VERSION "dbc-export 1 2026.26.6.5"

NS_ :

BS_:

BU_: APP APS BMS CC CMP CMPD CP DAS DI DIF DIR EPBL EPBR EVSE FC GTW HCML HCMR HVP ICR PCS PCS2 PLG PM PMF PMR PTC SCCM SCM SCS SDCR TAS UMC V2G VC VCBATT VCBATT0 VCBATT1 VCBATT2 VCFRONT VCFRONT1 VCFRONT2 VCLEFT VCRIGHT VCSEAT2L VCSEAT2R VCSEC

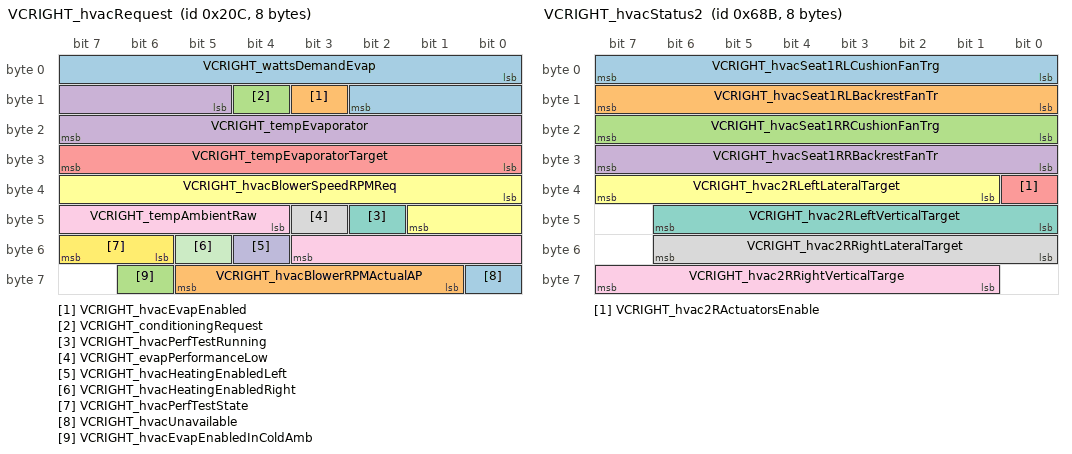
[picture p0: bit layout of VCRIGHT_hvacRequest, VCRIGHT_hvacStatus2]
BO_ 524 VCRIGHT_hvacRequest: 8 VCRIGHT
 SG_ VCRIGHT_wattsDemandEvap : 0|11@1+ (5,0) [0|10000] "W" Vector__XXX
 SG_ VCRIGHT_hvacEvapEnabled : 11|1@1+ (1,0) [0|1] "" Vector__XXX
 SG_ VCRIGHT_conditioningRequest : 12|1@1+ (1,0) [0|1] "" Vector__XXX
 SG_ VCRIGHT_tempEvaporator : 13|11@1+ (0.1,-40) [-40|105] "degC" Vector__XXX
 SG_ VCRIGHT_tempEvaporatorTarget : 24|8@1+ (0.2,0) [0|50] "degC" Vector__XXX
 SG_ VCRIGHT_hvacBlowerSpeedRPMReq : 32|10@1+ (5,0) [0|5115] "RPM" Vector__XXX
 SG_ VCRIGHT_hvacPerfTestRunning : 42|1@1+ (1,0) [0|1] "" Vector__XXX
 SG_ VCRIGHT_evapPerformanceLow : 43|1@1+ (1,0) [0|1] "" Vector__XXX
 SG_ VCRIGHT_tempAmbientRaw : 44|8@1+ (0.5,-40) [-39.5|80] "degC" Vector__XXX
 SG_ VCRIGHT_hvacHeatingEnabledLeft : 52|1@1+ (1,0) [0|1] "" Vector__XXX
 SG_ VCRIGHT_hvacHeatingEnabledRight : 53|1@1+ (1,0) [0|1] "" Vector__XXX
 SG_ VCRIGHT_hvacPerfTestState : 54|2@1+ (1,0) [0|3] "" Vector__XXX
 SG_ VCRIGHT_hvacUnavailable : 56|1@1+ (1,0) [0|1] "" Vector__XXX
 SG_ VCRIGHT_hvacBlowerRPMActualAP : 57|5@1+ (200,0) [0|4200] "rpm" Vector__XXX
 SG_ VCRIGHT_hvacEvapEnabledInColdAmb : 62|1@1+ (1,0) [0|1] "" Vector__XXX

BO_ 579 VCRIGHT_hvacStatus: 8 VCRIGHT
 SG_ VCRIGHT_hvacStatusIndex M : 0|3@1+ (1,0) [0|7] "" Vector__XXX
 SG_ VCRIGHT_warmingUpStatus m0 : 10|5@1+ (3,7) [7|100] "%" Vector__XXX
 SG_ VCRIGHT_coolingDownStatus m0 : 15|5@1+ (3,7) [7|100] "%" Vector__XXX
 SG_ VCRIGHT_childModeHVACState m0 : 20|2@1+ (1,0) [0|3] "" Vector__XXX
 SG_ VCRIGHT_dogModeState m0 : 22|4@1+ (1,0) [0|15] "" Vector__XXX
 SG_ VCRIGHT_hvacCabinTempEstValid m0 : 26|1@1+ (1,0) [0|1] "" Vector__XXX
 SG_ VCRIGHT_COPNotRunningReasonFilte m0 : 27|3@1+ (1,0) [0|7] "" Vector__XXX
 SG_ VCRIGHT_hvacCabinTempEst m0 : 30|11@1+ (0.1,-40) [-40|164] "degC" Vector__XXX
 SG_ VCRIGHT_hvacAirDistributionMode m0 : 41|3@1+ (1,0) [0|7] "" Vector__XXX
 SG_ VCRIGHT_hvacBlowerSegment m0 : 44|4@1+ (1,0) [0|15] "" Vector__XXX
 SG_ VCRIGHT_hvacRecirc m0 : 48|2@1+ (1,0) [0|3] "" Vector__XXX
 SG_ VCRIGHT_hvacACRunning m0 : 50|1@1+ (1,0) [0|1] "" Vector__XXX
 SG_ VCRIGHT_hvacPowerState m0 : 51|3@1+ (1,0) [0|7] "" Vector__XXX
 SG_ VCRIGHT_hvacVentStatus m0 : 54|2@1+ (1,0) [0|3] "" Vector__XXX
 SG_ VCRIGHT_hvacSecondRowState m0 : 56|3@1+ (1,0) [0|7] "" Vector__XXX
 SG_ VCRIGHT_hvacSystemNominal m0 : 59|1@1+ (1,0) [0|1] "" Vector__XXX
 SG_ VCRIGHT_hvacModelInitStatus m0 : 60|4@1+ (1,0) [0|15] "" Vector__XXX
 SG_ VCRIGHT_hvacMassflowRefrigSysRig m1 : 3|7@1+ (1,0) [0|125] "g/s" Vector__XXX
 SG_ VCRIGHT_hvacRecircDoorPercent m1 : 10|6@1+ (1.6,0) [0|100] "%" Vector__XXX
 SG_ VCRIGHT_tempDuctLeft m1 : 16|8@1+ (0.5,-22) [-22|105] "degC" Vector__XXX
 SG_ VCRIGHT_hvacMassflowRefrigSystem m1 : 24|8@1+ (1,0) [0|250] "g/s" Vector__XXX
 SG_ VCRIGHT_tempDuctRight m1 : 32|8@1+ (0.5,-22) [-22|105] "degC" Vector__XXX
 SG_ VCRIGHT_hvacMassflowRefrigSysLef m1 : 40|7@1+ (1,0) [0|125] "g/s" Vector__XXX
 SG_ VCRIGHT_hvacDuctTargetLeft m1 : 48|8@1+ (0.5,-40) [-40|80] "degC" Vector__XXX
 SG_ VCRIGHT_hvacDuctTargetRight m1 : 56|8@1+ (0.5,-40) [-40|80] "degC" Vector__XXX
 SG_ VCRIGHT_enableTripleCameraFanPow m2 : 9|1@1+ (1,0) [0|1] "" Vector__XXX
 SG_ VCRIGHT_tempDuctRightUpper m2 : 10|8@1+ (0.5,-22) [-22|105] "degC" Vector__XXX
 SG_ VCRIGHT_hpSplitTempsEnabled m2 : 18|1@1+ (1,0) [0|1] "" Vector__XXX
 SG_ VCRIGHT_hvacEvapInletTempEstimat m2 : 19|10@1+ (0.13,-40) [-40|90] "degC" Vector__XXX
 SG_ VCRIGHT_tempMonitorNotNominal m2 : 29|1@1+ (1,0) [0|1] "" Vector__XXX
 SG_ VCRIGHT_hvacCabinAtTempTarget m2 : 30|1@1+ (1,0) [0|1] "" Vector__XXX
 SG_ VCRIGHT_hvacReqSecondRow m2 : 31|1@1+ (1,0) [0|1] "" Vector__XXX
 SG_ VCRIGHT_hvacAirflowReason m2 : 32|5@1+ (1,0) [0|31] "" Vector__XXX
 SG_ VCRIGHT_autoHvacBlowerShouldLimi m2 : 37|1@1+ (1,0) [0|1] "" Vector__XXX
 SG_ VCRIGHT_hvacReqThirdRow m2 : 38|1@1+ (1,0) [0|1] "" Vector__XXX
 SG_ VCRIGHT_solarLoadOnVehicle m2 : 40|8@1+ (4,0) [0|1016] "W/m2" Vector__XXX
 SG_ VCRIGHT_refrigDistCommanded m2 : 48|1@1+ (1,0) [0|1] "" Vector__XXX
 SG_ VCRIGHT_hvacFrontRightSeatFanSta m2 : 49|2@1+ (1,0) [0|3] "" Vector__XXX
 SG_ VCRIGHT_hvacFrontLeftSeatFanStat m2 : 51|2@1+ (1,0) [0|3] "" Vector__XXX
 SG_ VCRIGHT_hvacRefHighPowerRequest m2 : 53|1@1+ (1,0) [0|1] "" Vector__XXX
 SG_ VCRIGHT_windshieldCameraHeaterDu m2 : 54|5@1+ (5,0) [0|100] "%" Vector__XXX
 SG_ VCRIGHT_extendedHvacPerfTestSupp m2 : 59|4@1+ (1,0) [0|15] "" Vector__XXX
 SG_ VCRIGHT_hvacFrontRightSeatHeatSt m3 : 4|2@1+ (1,0) [0|3] "" Vector__XXX
 SG_ VCRIGHT_hvacSeatFrontLeftTempTar m3 : 6|8@1+ (0.5,-40) [-40|80] "degC" Vector__XXX
 SG_ VCRIGHT_hvacManualToAutoNotify m3 : 14|3@1+ (1,0) [0|7] "" Vector__XXX
 SG_ VCRIGHT_hvacRequestsFullAuto m3 : 17|3@1+ (1,0) [0|7] "" Vector__XXX
 SG_ VCRIGHT_passengerPresentHvacCycl m3 : 21|1@1+ (1,0) [0|1] "" Vector__XXX
 SG_ VCRIGHT_hvacRequestsAutoIntake m3 : 22|1@1+ (1,0) [0|1] "" Vector__XXX
 SG_ VCRIGHT_steeringWheelHeatStatus m3 : 24|2@1+ (1,0) [0|3] "" Vector__XXX
 SG_ VCRIGHT_autoDefogStatus m3 : 26|2@1+ (1,0) [0|3] "" Vector__XXX
 SG_ VCRIGHT_solarElevation m3 : 31|9@1- (0.5,0) [-127.5|127.5] "deg" Vector__XXX
 SG_ VCRIGHT_minsToSunrise m3 : 40|8@1+ (10,0) [0|2540] "min" Vector__XXX
 SG_ VCRIGHT_minsToSunset m3 : 48|8@1+ (10,0) [0|2540] "min" Vector__XXX
 SG_ VCRIGHT_hvacLimitedReasonRight m3 : 56|3@1+ (1,0) [0|7] "" Vector__XXX
 SG_ VCRIGHT_hvacLimitedReasonLeft m3 : 59|3@1+ (1,0) [0|7] "" Vector__XXX
 SG_ VCRIGHT_hvacOverheatProtActive m3 : 63|1@1+ (1,0) [0|1] "" Vector__XXX
 SG_ VCRIGHT_autoSwingAvailable m4 : 9|1@1+ (1,0) [0|1] "" Vector__XXX
 SG_ VCRIGHT_tempDuctLeftUpper m4 : 10|8@1+ (0.5,-22) [-22|105] "degC" Vector__XXX
 SG_ VCRIGHT_hvacFrontLeftSeatHeatSta m4 : 18|2@1+ (1,0) [0|3] "" Vector__XXX
 SG_ VCRIGHT_hvacQdotLeft m4 : 20|14@1+ (1,-8191) [-8191|8191] "W" Vector__XXX
 SG_ VCRIGHT_hvacQdotRight m4 : 34|14@1+ (1,-8191) [-8191|8191] "W" Vector__XXX
 SG_ VCRIGHT_tempDuctLeftLower m4 : 48|8@1+ (0.5,-22) [-22|105] "degC" Vector__XXX
 SG_ VCRIGHT_tempDuctRightLower m4 : 56|8@1+ (0.5,-22) [-22|105] "degC" Vector__XXX
 SG_ VCRIGHT_foggingControllerResetRe m5 : 9|15@1+ (1,0) [0|32767] "" Vector__XXX
 SG_ VCRIGHT_modeledCabinPressure m5 : 24|8@1+ (1,0) [0|255] "Pa" Vector__XXX
 SG_ VCRIGHT_blowerTorqueIndex m5 : 32|7@1+ (1,0) [0|127] "%" Vector__XXX
 SG_ VCRIGHT_autoSwingLeftPosX m5 : 39|8@1+ (0.4,0) [0|100] "%" Vector__XXX
 SG_ VCRIGHT_autoSwingRightPositionX m5 : 48|8@1+ (0.4,0) [0|100] "%" Vector__XXX

BO_ 1675 VCRIGHT_hvacStatus2: 8 VCRIGHT
 SG_ VCRIGHT_hvacSeat1RLCushionFanTrg : 0|8@1+ (0.5,0) [0|100] "%" Vector__XXX
 SG_ VCRIGHT_hvacSeat1RLBackrestFanTr : 8|8@1+ (0.5,0) [0|100] "%" Vector__XXX
 SG_ VCRIGHT_hvacSeat1RRCushionFanTrg : 16|8@1+ (0.5,0) [0|100] "%" Vector__XXX
 SG_ VCRIGHT_hvacSeat1RRBackrestFanTr : 24|8@1+ (0.5,0) [0|100] "%" Vector__XXX
 SG_ VCRIGHT_hvac2RActuatorsEnable : 32|1@1+ (1,0) [0|1] "" Vector__XXX
 SG_ VCRIGHT_hvac2RLeftLateralTarget : 33|7@1+ (1,0) [0|100] "%" Vector__XXX
 SG_ VCRIGHT_hvac2RLeftVerticalTarget : 40|7@1+ (1,0) [0|100] "%" Vector__XXX
 SG_ VCRIGHT_hvac2RRightLateralTarget : 48|7@1+ (1,0) [0|100] "%" Vector__XXX
 SG_ VCRIGHT_hvac2RRightVerticalTarge : 57|7@1+ (1,0) [0|100] "%" Vector__XXX

BO_ 771 VCRIGHT_info: 8 VCRIGHT
 SG_ VCRIGHT_infoIndex M : 0|8@1+ (1,0) [0|255] "" Vector__XXX
 SG_ VCRIGHT_infoBuildType m10 : 8|3@1+ (1,0) [0|7] "" Vector__XXX
 SG_ VCRIGHT_infoBuildConfigId m10 : 16|16@1+ (1,0) [0|65535] "" Vector__XXX
 SG_ VCRIGHT_infoHardwareId m10 : 32|16@1+ (1,0) [0|65535] "" Vector__XXX
 SG_ VCRIGHT_infoComponentId m10 : 48|16@1+ (1,0) [0|65535] "" Vector__XXX
 SG_ VCRIGHT_infoPcbaId m11 : 8|8@1+ (1,0) [0|255] "" Vector__XXX
 SG_ VCRIGHT_infoAssemblyId m11 : 16|8@1+ (1,0) [0|254] "" Vector__XXX
 SG_ VCRIGHT_infoUsageId m11 : 24|16@1+ (1,0) [0|65535] "" Vector__XXX
 SG_ VCRIGHT_infoSubUsageId m11 : 40|16@1+ (1,0) [0|65535] "" Vector__XXX
 SG_ VCRIGHT_infoAppCrc m13 : 8|32@1+ (1,0) [0|4294967295] "" Vector__XXX
 SG_ VCRIGHT_infoLUMBARRAppCRC m16 : 32|32@1+ (1,0) [0|4294967295] "" Vector__XXX
 SG_ VCRIGHT_infoAppGitHash m17 : 8|56@1+ (1,0) [0|7.20575940379e+16] "" Vector__XXX
 SG_ VCRIGHT_infoBootGitHash m18 : 8|56@1+ (1,0) [0|7.20575940379e+16] "" Vector__XXX
 SG_ VCRIGHT_infoPlatformType m19 : 8|8@1+ (1,0) [0|255] "" Vector__XXX
 SG_ VCRIGHT_infoBootUdsProtoVersion m20 : 8|16@1+ (1,0) [0|65535] "" Vector__XXX
 SG_ VCRIGHT_infoBootCrc m20 : 24|32@1+ (1,0) [0|4294967295] "" Vector__XXX

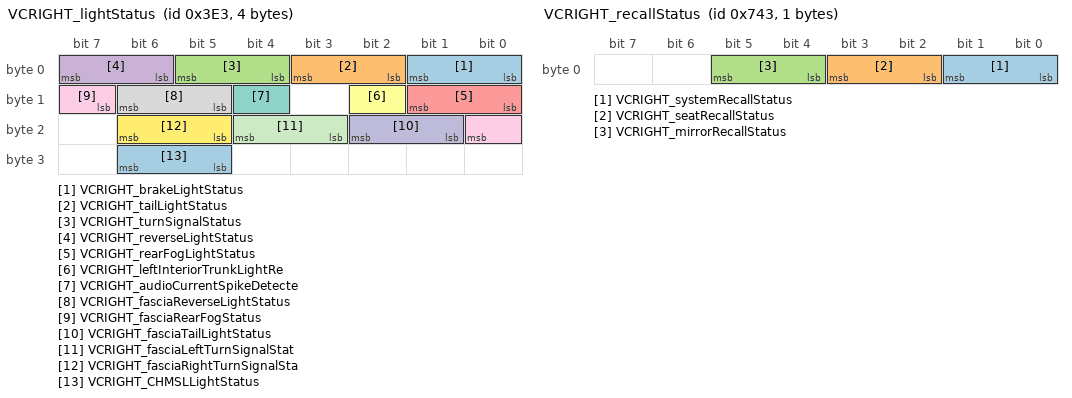
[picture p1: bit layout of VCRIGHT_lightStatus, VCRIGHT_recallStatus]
BO_ 995 VCRIGHT_lightStatus: 4 VCRIGHT
 SG_ VCRIGHT_brakeLightStatus : 0|2@1+ (1,0) [0|2] "" Vector__XXX
 SG_ VCRIGHT_tailLightStatus : 2|2@1+ (1,0) [0|2] "" Vector__XXX
 SG_ VCRIGHT_turnSignalStatus : 4|2@1+ (1,0) [0|2] "" Vector__XXX
 SG_ VCRIGHT_reverseLightStatus : 6|2@1+ (1,0) [0|2] "" Vector__XXX
 SG_ VCRIGHT_rearFogLightStatus : 8|2@1+ (1,0) [0|2] "" Vector__XXX
 SG_ VCRIGHT_leftInteriorTrunkLightRe : 10|1@1+ (1,0) [0|1] "" Vector__XXX
 SG_ VCRIGHT_audioCurrentSpikeDetecte : 12|1@1+ (1,0) [0|1] "" Vector__XXX
 SG_ VCRIGHT_fasciaReverseLightStatus : 13|2@1+ (1,0) [0|2] "" Vector__XXX
 SG_ VCRIGHT_fasciaRearFogStatus : 15|2@1+ (1,0) [0|2] "" Vector__XXX
 SG_ VCRIGHT_fasciaTailLightStatus : 17|2@1+ (1,0) [0|2] "" Vector__XXX
 SG_ VCRIGHT_fasciaLeftTurnSignalStat : 19|2@1+ (1,0) [0|2] "" Vector__XXX
 SG_ VCRIGHT_fasciaRightTurnSignalSta : 21|2@1+ (1,0) [0|2] "" Vector__XXX
 SG_ VCRIGHT_CHMSLLightStatus : 29|2@1+ (1,0) [0|2] "" Vector__XXX

BO_ 1803 VCRIGHT_logging0point1Hz: 8 VCRIGHT
 SG_ VCRIGHT_logging0point1HzIndex M : 0|4@1+ (1,0) [0|15] "" Vector__XXX
 SG_ VCRIGHT_glareShieldEstimatedResi m2 : 4|6@1+ (0.5,10) [10|40] "Ohm" Vector__XXX
 SG_ VCRIGHT_cabinAirFilterLifeRemain m2 : 10|7@1+ (1,0) [0|127] "%" Vector__XXX
 SG_ VCRIGHT_HEPAAirFilterLifeRemaini m2 : 17|7@1+ (1,0) [0|127] "%" Vector__XXX
 SG_ VCRIGHT_leftPTCCompromisedRod m2 : 24|3@1+ (1,0) [0|7] "" Vector__XXX
 SG_ VCRIGHT_rightPTCCompromisedRod m2 : 27|3@1+ (1,0) [0|7] "" Vector__XXX
 SG_ VCRIGHT_hepaFilterHealthScore m2 : 32|7@1+ (1,0) [0|127] "%" Vector__XXX
 SG_ VCRIGHT_cabinFilterHealthScore m2 : 40|7@1+ (1,0) [0|127] "%" Vector__XXX
 SG_ VCRIGHT_cabinTempBreathLevelFOff m2 : 47|8@1+ (0.5,-40) [-40|80] "degC" Vector__XXX
 SG_ VCRIGHT_airDistributionModeAdjus m2 : 55|9@1+ (0.001,1) [1|1.5] "-" Vector__XXX
 SG_ VCRIGHT_hvacLHBleedEndStop m3 : 8|8@1+ (0.02,0) [0|5] "V" Vector__XXX
 SG_ VCRIGHT_hvacRHBleedEndStop m3 : 16|8@1+ (0.02,0) [0|5] "V" Vector__XXX
 SG_ VCRIGHT_hvacLHVaneEndStop m3 : 24|8@1+ (0.02,0) [0|5] "V" Vector__XXX
 SG_ VCRIGHT_hvacRHVaneEndStop m3 : 32|8@1+ (0.02,0) [0|5] "V" Vector__XXX
 SG_ VCRIGHT_hvacUpperModeEndStop m3 : 40|8@1+ (0.02,0) [0|5] "V" Vector__XXX
 SG_ VCRIGHT_hvacLowerModeEndStop m3 : 48|8@1+ (0.02,0) [0|5] "V" Vector__XXX
 SG_ VCRIGHT_hvacIntakeEndStop m3 : 56|8@1+ (0.02,0) [0|5] "V" Vector__XXX
 SG_ VCRIGHT_hvacLHBleedZeroStop m4 : 8|8@1+ (0.02,0) [0|5] "V" Vector__XXX
 SG_ VCRIGHT_hvacRHBleedZeroStop m4 : 16|8@1+ (0.02,0) [0|5] "V" Vector__XXX
 SG_ VCRIGHT_hvacLHVaneZeroStop m4 : 24|8@1+ (0.02,0) [0|5] "V" Vector__XXX
 SG_ VCRIGHT_hvacRHVaneZeroStop m4 : 32|8@1+ (0.02,0) [0|5] "V" Vector__XXX
 SG_ VCRIGHT_hvacUpperModeZeroStop m4 : 40|8@1+ (0.02,0) [0|5] "V" Vector__XXX
 SG_ VCRIGHT_hvacLowerModeZeroStop m4 : 48|8@1+ (0.02,0) [0|5] "V" Vector__XXX
 SG_ VCRIGHT_hvacIntakeZeroStop m4 : 56|8@1+ (0.02,0) [0|5] "V" Vector__XXX
 SG_ VCRIGHT_averageDuctTempFCooling m5 : 8|8@1+ (0.5,-40) [-40|80] "degC" Vector__XXX
 SG_ VCRIGHT_fasciaTailLeftLightCurre m5 : 16|9@1+ (0.002,0) [0|1.02] "A" Vector__XXX
 SG_ VCRIGHT_fasciaTailLeftLight_0001 m5 : 25|3@1+ (1,0) [1|7] "" Vector__XXX
 SG_ VCRIGHT_fasciaTailRightLightCurr m5 : 28|9@1+ (0.002,0) [0|1.02] "A" Vector__XXX
 SG_ VCRIGHT_fasciaTailRightLigh_0001 m5 : 37|3@1+ (1,0) [1|7] "" Vector__XXX
 SG_ VCRIGHT_liftgateTailLeftLightCur m5 : 40|9@1+ (0.002,0) [0|1.02] "A" Vector__XXX
 SG_ VCRIGHT_liftgateTailLeftLig_0001 m5 : 49|3@1+ (1,0) [1|7] "" Vector__XXX
 SG_ VCRIGHT_liftgateTailRightLightCu m5 : 52|3@1+ (1,0) [1|7] "" Vector__XXX
 SG_ VCRIGHT_ambientTempLimp m6 : 8|8@1+ (0.5,-40) [-40|80] "degC" Vector__XXX
 SG_ VCRIGHT_cabinProbeTempLimp m6 : 16|8@1+ (0.5,-40) [-40|80] "degC" Vector__XXX
 SG_ VCRIGHT_thsTempLimp m6 : 24|8@1+ (0.5,-40) [-40|80] "degC" Vector__XXX
 SG_ VCRIGHT_thsCabinWaterMassLimp m6 : 32|8@1+ (0.5,0) [0|124] "g/kg" Vector__XXX
 SG_ VCRIGHT_thsSolarIrradianceLimp m6 : 40|8@1+ (5,0) [0|1270] "W/m2" Vector__XXX
 SG_ VCRIGHT_silentWakeRecordCount m6 : 48|5@1+ (1,0) [0|31] "" Vector__XXX
 SG_ VCRIGHT_interiorCameraLedCurrent m6 : 56|8@1+ (8,0) [0|2032] "mA" Vector__XXX
 SG_ VCRIGHT_evapCondensateMass m7 : 8|8@1+ (2,0) [0|500] "g" Vector__XXX
 SG_ VCRIGHT_airwaveRightLateralTotal m7 : 16|16@1+ (6100,0) [0|399763500] "deg" Vector__XXX
 SG_ VCRIGHT_airwaveLeftLateralTotalT m7 : 32|16@1+ (6100,0) [0|399763500] "deg" Vector__XXX
 SG_ VCRIGHT_hvacRearEndStop m7 : 48|8@1+ (0.02,0) [0|5] "V" Vector__XXX
 SG_ VCRIGHT_hvacRearZeroStop m7 : 56|8@1+ (0.02,0) [0|5] "V" Vector__XXX
 SG_ VCRIGHT_evapLoadInFresh m8 : 8|8@1+ (35,0) [0|8000] "W" Vector__XXX
 SG_ VCRIGHT_evapLoadInRecirc m8 : 16|8@1+ (35,0) [0|8000] "W" Vector__XXX
 SG_ VCRIGHT_tempIncarCabinDeep m8 : 24|8@1+ (0.5,-40) [-40|85] "degC" Vector__XXX
 SG_ VCRIGHT_cabinTempBreathLeve_0001 m8 : 32|8@1+ (0.5,-40) [-40|80] "degC" Vector__XXX
 SG_ VCRIGHT_cabinTempBreathLevelF10m m8 : 40|8@1+ (0.5,-40) [-40|80] "degC" Vector__XXX
 SG_ VCRIGHT_cabinTempBreathLeve_0002 m8 : 48|8@1+ (0.5,-40) [-40|80] "degC" Vector__XXX
 SG_ VCRIGHT_cabinTempBreathLevelF5mi m8 : 56|8@1+ (0.5,-40) [-40|80] "degC" Vector__XXX
 SG_ VCRIGHT_foggingMonitorRuntime m9 : 4|12@1+ (10,0) [0|40950] "Hours" Vector__XXX
 SG_ VCRIGHT_cabinTempInteriorFHeatin m9 : 16|8@1+ (0.5,-40) [-40|80] "degC" Vector__XXX
 SG_ VCRIGHT_cabinTempInteriorFCoolin m9 : 24|8@1+ (0.5,-40) [-40|80] "degC" Vector__XXX
 SG_ VCRIGHT_filterLifeBlowerTorque m9 : 32|10@1+ (0.006,-1.5) [-1.5|4.5] "Nm" Vector__XXX
 SG_ VCRIGHT_averageDuctTempFHeating m9 : 48|8@1+ (0.5,-40) [-40|80] "degC" Vector__XXX
 SG_ VCRIGHT_thsSolarSensorType m9 : 56|2@1+ (1,0) [0|3] "" Vector__XXX
 SG_ VCRIGHT_thsTempSensorType m9 : 58|2@1+ (1,0) [0|3] "" Vector__XXX

BO_ 611 VCRIGHT_logging10Hz: 8 VCRIGHT
 SG_ VCRIGHT_logging10HzIndex M : 0|3@1+ (1,0) [0|7] "" Vector__XXX
 SG_ VCRIGHT_hvacLHBleedTarget m0 : 3|8@1+ (0.4,0) [0|100] "%" Vector__XXX
 SG_ VCRIGHT_hvacRHBleedTarget m0 : 11|8@1+ (0.4,0) [0|100] "%" Vector__XXX
 SG_ VCRIGHT_hvacLHVaneTarget m0 : 19|8@1+ (0.4,0) [0|100] "%" Vector__XXX
 SG_ VCRIGHT_hvacRHVaneTarget m0 : 27|8@1+ (0.4,0) [0|100] "%" Vector__XXX
 SG_ VCRIGHT_hvacUpperModeTarget m0 : 35|10@1+ (0.1,0) [0|100] "%" Vector__XXX
 SG_ VCRIGHT_hvacLowerModeTarget m0 : 45|8@1+ (0.4,0) [0|100] "%" Vector__XXX
 SG_ VCRIGHT_hvacIntakeTarget m0 : 53|8@1+ (0.4,0) [0|100] "%" Vector__XXX
 SG_ VCRIGHT_hvacLHBleedPosition m1 : 3|8@1+ (0.4,0) [0|100] "%" Vector__XXX
 SG_ VCRIGHT_hvacRHBleedPosition m1 : 11|8@1+ (0.4,0) [0|100] "%" Vector__XXX
 SG_ VCRIGHT_hvacLHVanePosition m1 : 19|8@1+ (0.4,0) [0|100] "%" Vector__XXX
 SG_ VCRIGHT_hvacRHVanePosition m1 : 27|8@1+ (0.4,0) [0|100] "%" Vector__XXX
 SG_ VCRIGHT_hvacUpperModePosition m1 : 35|10@1+ (0.1,0) [0|100] "%" Vector__XXX
 SG_ VCRIGHT_hvacLowerModePosition m1 : 45|8@1+ (0.4,0) [0|100] "%" Vector__XXX
 SG_ VCRIGHT_hvacIntakePosition m1 : 53|8@1+ (0.4,0) [0|100] "%" Vector__XXX
 SG_ VCRIGHT_hvacLHBleedActuatorState m2 : 3|2@1+ (1,0) [0|3] "" Vector__XXX
 SG_ VCRIGHT_hvacRHBleedActuatorState m2 : 5|2@1+ (1,0) [0|3] "" Vector__XXX
 SG_ VCRIGHT_hvacLHVaneActuatorState m2 : 8|2@1+ (1,0) [0|3] "" Vector__XXX
 SG_ VCRIGHT_hvacRHVaneActuatorState m2 : 10|2@1+ (1,0) [0|3] "" Vector__XXX
 SG_ VCRIGHT_hvacUpperModeActState m2 : 12|2@1+ (1,0) [0|3] "" Vector__XXX
 SG_ VCRIGHT_hvacLowerModeActState m2 : 14|2@1+ (1,0) [0|3] "" Vector__XXX
 SG_ VCRIGHT_hvacIntakeActuatorState m2 : 16|2@1+ (1,0) [0|3] "" Vector__XXX
 SG_ VCRIGHT_hvacRearActuatorState m2 : 18|2@1+ (1,0) [0|3] "" Vector__XXX
 SG_ VCRIGHT_EvapPulldownBiasActive m2 : 20|1@1+ (1,0) [0|1] "" Vector__XXX
 SG_ VCRIGHT_tempDatLeftEst m2 : 21|9@1+ (0.5,-22) [-22|200] "degC" Vector__XXX
 SG_ VCRIGHT_tempDatRightEst m2 : 30|9@1+ (0.5,-22) [-22|200] "degC" Vector__XXX
 SG_ VCRIGHT_tempDuctLeftEst m2 : 40|8@1+ (0.5,-22) [-22|105] "degC" Vector__XXX
 SG_ VCRIGHT_tempDuctRightEst m2 : 48|8@1+ (0.5,-22) [-22|105] "degC" Vector__XXX
 SG_ VCRIGHT_ptcHeaterBadRodDetection m2 : 56|4@1+ (1,0) [0|15] "" Vector__XXX
 SG_ VCRIGHT_upperModeDrvActuatorStat m2 : 60|4@1+ (1,0) [0|15] "" Vector__XXX
 SG_ VCRIGHT_leftVerticalActuato_0001 m3 : 8|8@1+ (1,0) [0|255] "" Vector__XXX
 SG_ VCRIGHT_leftLateralActuatorStatu m3 : 16|8@1+ (1,0) [0|255] "" Vector__XXX
 SG_ VCRIGHT_rightVerticalActuat_0001 m3 : 24|8@1+ (1,0) [0|255] "" Vector__XXX
 SG_ VCRIGHT_rightLateralActuato_0001 m3 : 32|8@1+ (1,0) [0|255] "" Vector__XXX
 SG_ VCRIGHT_leftVerticalActuatorStat m3 : 40|4@1+ (1,0) [0|15] "" Vector__XXX
 SG_ VCRIGHT_leftLateralActuatorState m3 : 44|4@1+ (1,0) [0|15] "" Vector__XXX
 SG_ VCRIGHT_rightVerticalActuatorSta m3 : 48|4@1+ (1,0) [0|15] "" Vector__XXX
 SG_ VCRIGHT_rightLateralActuatorStat m3 : 52|4@1+ (1,0) [0|15] "" Vector__XXX
 SG_ VCRIGHT_windshieldRHExteriorSurf m3 : 56|8@1+ (1,0) [0|150] "%" Vector__XXX
 SG_ VCRIGHT_leftVerticalActuatorDuty m4 : 8|6@1- (4,0) [-100|100] "%" Vector__XXX
 SG_ VCRIGHT_leftLateralActuatorDuty m4 : 16|6@1- (4,0) [-100|100] "%" Vector__XXX
 SG_ VCRIGHT_rightVerticalActuatorDut m4 : 24|6@1- (4,0) [-100|100] "%" Vector__XXX
 SG_ VCRIGHT_rightLateralActuatorDuty m4 : 30|6@1- (4,0) [-100|100] "%" Vector__XXX
 SG_ VCRIGHT_frontLeftSeatTempTargetQ m4 : 36|6@1+ (0.75,20) [20|60] "degC" Vector__XXX
 SG_ VCRIGHT_frontRightSeatTempTarget m4 : 42|6@1+ (1,20) [20|60] "degC" Vector__XXX
 SG_ VCRIGHT_hvacRearPosition m4 : 48|8@1+ (0.4,0) [0|100] "%" Vector__XXX
 SG_ VCRIGHT_hvacRearTarget m4 : 56|8@1+ (0.4,0) [0|100] "%" Vector__XXX

BO_ 691 VCRIGHT_logging1Hz: 8 VCRIGHT
 SG_ VCRIGHT_logging1HzIndex M : 0|5@1+ (1,0) [0|31] "" Vector__XXX
 SG_ VCRIGHT_glareShieldHeaterState m0 : 5|3@1+ (1,0) [0|7] "" Vector__XXX
 SG_ VCRIGHT_tempIncarCabinProbe m0 : 8|8@1+ (0.5,-40) [-40|85] "degC" Vector__XXX
 SG_ VCRIGHT_cabinTempInteriorL2 m0 : 16|8@1+ (0.5,-40) [-40|80] "degC" Vector__XXX
 SG_ VCRIGHT_cabinTempInteriorSunnyL2 m0 : 24|8@1+ (0.6,-40) [-40|100] "degC" Vector__XXX
 SG_ VCRIGHT_tempIncarCabinMid m0 : 32|8@1+ (0.5,-40) [-40|85] "degC" Vector__XXX
 SG_ VCRIGHT_cabinTempInteriorL3 m0 : 40|8@1+ (0.5,-40) [-40|80] "degC" Vector__XXX
 SG_ VCRIGHT_cabinTempInteriorSunnyL3 m0 : 48|8@1+ (0.6,-40) [-40|100] "degC" Vector__XXX
 SG_ VCRIGHT_tempWetBulb m0 : 56|8@1+ (0.5,-40) [-40|80] "degC" Vector__XXX
 SG_ VCRIGHT_isRainingOrSnowing m1 : 5|1@1+ (1,0) [0|1] "" Vector__XXX
 SG_ VCRIGHT_cabinTempGlassRoof m1 : 8|8@1+ (0.5,-40) [-40|80] "degC" Vector__XXX
 SG_ VCRIGHT_cabinTempWindshield m1 : 16|8@1+ (0.5,-40) [-40|80] "degC" Vector__XXX
 SG_ VCRIGHT_cabinTempInterior m1 : 24|8@1+ (0.5,-40) [-40|80] "degC" Vector__XXX
 SG_ VCRIGHT_cabinTempInteriorSunny m1 : 32|8@1+ (0.6,-40) [-40|100] "degC" Vector__XXX
 SG_ VCRIGHT_cabinTempSideGlassLeft m1 : 40|8@1+ (0.5,-40) [-40|80] "degC" Vector__XXX
 SG_ VCRIGHT_cabinTempSideGlassRight m1 : 48|8@1+ (0.5,-40) [-40|80] "degC" Vector__XXX
 SG_ VCRIGHT_cabinTempBreathLevel m1 : 56|8@1+ (0.5,-40) [-40|80] "degC" Vector__XXX
 SG_ VCRIGHT_pcbaTemperature m2 : 5|11@1+ (0.125,-40) [-40|150] "degC" Vector__XXX
 SG_ VCRIGHT_wattsHeaterLeftTotal m2 : 16|10@1+ (5,0) [0|4000] "W" Vector__XXX
 SG_ VCRIGHT_wattsHeaterRightTotal m2 : 26|10@1+ (5,0) [0|4000] "W" Vector__XXX
 SG_ VCRIGHT_qdotLeftFFUnsat m2 : 36|9@1- (10,0) [-1500|1500] "W" Vector__XXX
 SG_ VCRIGHT_qdotRightFFUnsat m2 : 45|9@1- (10,0) [-1500|1500] "W" Vector__XXX
 SG_ VCRIGHT_nvhLevelDb m2 : 54|9@1+ (0.1,30) [30|80] "dB" Vector__XXX
 SG_ VCRIGHT_hvacSetTempActualLeft m3 : 8|8@1+ (0.1,15) [15|28] "degC" Vector__XXX
 SG_ VCRIGHT_hvacSetTempActualRight m3 : 16|8@1+ (0.1,15) [15|28] "degC" Vector__XXX
 SG_ VCRIGHT_hvacAutoTransitionReason m3 : 24|5@1+ (1,0) [0|31] "" Vector__XXX
 SG_ VCRIGHT_hvacMassflowTarget m3 : 29|8@1+ (1,0) [0|200] "g/s" Vector__XXX
 SG_ VCRIGHT_hvacQdotLimitedLeft m3 : 37|1@1+ (1,0) [0|1] "" Vector__XXX
 SG_ VCRIGHT_hvacQdotLimitedRight m3 : 38|1@1+ (1,0) [0|1] "" Vector__XXX
 SG_ VCRIGHT_LHPanelAirflowBlocked m3 : 39|1@1+ (1,0) [0|1] "" Vector__XXX
 SG_ VCRIGHT_RHPanelAirflowBlocked m3 : 40|1@1+ (1,0) [0|1] "" Vector__XXX
 SG_ VCRIGHT_floorAirflowBlocked m3 : 41|1@1+ (1,0) [0|1] "" Vector__XXX
 SG_ VCRIGHT_defrostAirflowBlocked m3 : 42|1@1+ (1,0) [0|1] "" Vector__XXX
 SG_ VCRIGHT_hvacFilterLifeDetectActi m3 : 43|1@1+ (1,0) [0|1] "" Vector__XXX
 SG_ VCRIGHT_hvacLHBleedOperationMode m3 : 44|1@1+ (1,0) [0|1] "" Vector__XXX
 SG_ VCRIGHT_hvacRHBleedOperationMode m3 : 45|1@1+ (1,0) [0|1] "" Vector__XXX
 SG_ VCRIGHT_hvacLHVaneOperationMode m3 : 46|1@1+ (1,0) [0|1] "" Vector__XXX
 SG_ VCRIGHT_hvacRHVaneOperationMode m3 : 47|1@1+ (1,0) [0|1] "" Vector__XXX
 SG_ VCRIGHT_hvacUpperModeOpMode m3 : 48|1@1+ (1,0) [0|1] "" Vector__XXX
 SG_ VCRIGHT_hvacLowerModeOpMode m3 : 49|1@1+ (1,0) [0|1] "" Vector__XXX
 SG_ VCRIGHT_hvacIntakeOperationMode m3 : 50|1@1+ (1,0) [0|1] "" Vector__XXX
 SG_ VCRIGHT_hvacRearOperationMode m3 : 51|1@1+ (1,0) [0|1] "" Vector__XXX
 SG_ VCRIGHT_isProbeFeedbackApplied m3 : 52|3@1+ (1,0) [0|7] "" Vector__XXX
 SG_ VCRIGHT_feedbackPullDownScalar m3 : 55|2@1+ (30,70) [70|130] "-" Vector__XXX
 SG_ VCRIGHT_feedForwardPullDownScala m3 : 57|6@1+ (1,70) [70|130] "-" Vector__XXX
 SG_ VCRIGHT_convectionTargetLeft m4 : 5|9@1+ (4,-1000) [-1000|1000] "W/m2" Vector__XXX
 SG_ VCRIGHT_convectionTargetRight m4 : 14|9@1+ (4,-1000) [-1000|1000] "W/m2" Vector__XXX
 SG_ VCRIGHT_convectionDeliveredLeft m4 : 23|9@1+ (4,-1000) [-1000|1000] "W/m2" Vector__XXX
 SG_ VCRIGHT_convectionDeliveredRight m4 : 32|9@1+ (4,-1000) [-1000|1000] "W/m2" Vector__XXX
 SG_ VCRIGHT_solarLoadRightOccupant m4 : 41|7@1+ (2,0) [0|252] "W/m2" Vector__XXX
 SG_ VCRIGHT_solarLoadLeftOccupant m4 : 48|7@1+ (2,0) [0|252] "W/m2" Vector__XXX
 SG_ VCRIGHT_ptcShutOutletMitigationA m4 : 55|1@1+ (1,0) [0|1] "" Vector__XXX
 SG_ VCRIGHT_solarLoadFromThsTemp m4 : 56|8@1+ (8,-1020) [-1020|1012] "W/m2" Vector__XXX
 SG_ VCRIGHT_hvacFoggingRiskLeve_0003 m5 : 5|6@1+ (1.6,0) [0|100] "%" Vector__XXX
 SG_ VCRIGHT_hvacFoggingRiskLeve_0004 m5 : 11|6@1+ (1.6,0) [0|100] "%" Vector__XXX
 SG_ VCRIGHT_hvacFoggingRiskLeve_0001 m5 : 17|6@1+ (1.6,0) [0|100] "%" Vector__XXX
 SG_ VCRIGHT_ptcHeaterTempDuctHigh m5 : 23|1@1+ (1,0) [0|1] "" Vector__XXX
 SG_ VCRIGHT_ptcHeaterTempDuctFault m5 : 24|1@1+ (1,0) [0|1] "" Vector__XXX
 SG_ VCRIGHT_ptcHeaterNoAirflow m5 : 25|1@1+ (1,0) [0|1] "" Vector__XXX
 SG_ VCRIGHT_ptcHeaterHvacActNotReady m5 : 26|1@1+ (1,0) [0|1] "" Vector__XXX
 SG_ VCRIGHT_ptcHeaterNoUiRequest m5 : 27|1@1+ (1,0) [0|1] "" Vector__XXX
 SG_ VCRIGHT_ptcHeaterNoHighVoltage m5 : 28|1@1+ (1,0) [0|1] "" Vector__XXX
 SG_ VCRIGHT_ptcHeaterLAirPathBlocked m5 : 29|1@1+ (1,0) [0|1] "" Vector__XXX
 SG_ VCRIGHT_ptcHeaterRAirPathBlocked m5 : 30|1@1+ (1,0) [0|1] "" Vector__XXX
 SG_ VCRIGHT_ptcHeaterReqAirpathBlock m5 : 31|1@1+ (1,0) [0|1] "" Vector__XXX
 SG_ VCRIGHT_hvacQdotFeedforward m5 : 32|16@1+ (1,-32767) [-32767|32767] "W" Vector__XXX
 SG_ VCRIGHT_cabinTempWshldDefog m5 : 48|8@1+ (0.5,-40) [-40|80] "degC" Vector__XXX
 SG_ VCRIGHT_cabinTempWshldDefogTop m5 : 56|8@1+ (0.5,-40) [-40|80] "degC" Vector__XXX
 SG_ VCRIGHT_hvacLHBleedVoltage m6 : 8|8@1+ (0.02,0) [0|5] "V" Vector__XXX
 SG_ VCRIGHT_hvacRHBleedVoltage m6 : 16|8@1+ (0.02,0) [0|5] "V" Vector__XXX
 SG_ VCRIGHT_hvacLHVaneVoltage m6 : 24|8@1+ (0.02,0) [0|5] "V" Vector__XXX
 SG_ VCRIGHT_hvacRHVaneVoltage m6 : 32|8@1+ (0.02,0) [0|5] "V" Vector__XXX
 SG_ VCRIGHT_hvacUpperModeVoltage m6 : 40|8@1+ (0.02,0) [0|5] "V" Vector__XXX
 SG_ VCRIGHT_hvacLowerModeVoltage m6 : 48|8@1+ (0.02,0) [0|5] "V" Vector__XXX
 SG_ VCRIGHT_hvacIntakeVoltage m6 : 56|8@1+ (0.02,0) [0|5] "V" Vector__XXX
 SG_ VCRIGHT_cabinTempBreathLevelFHea m7 : 5|8@1+ (0.5,-40) [-40|80] "degC" Vector__XXX
 SG_ VCRIGHT_cabinTempBreathLevelFCoo m7 : 13|8@1+ (0.5,-40) [-40|80] "degC" Vector__XXX
 SG_ VCRIGHT_hvacTorqueMassflowLinear m7 : 21|8@1+ (1,0) [0|250] "g/s" Vector__XXX
 SG_ VCRIGHT_hvacTorqueMassflowEstima m7 : 29|3@1+ (1,0) [0|7] "" Vector__XXX
 SG_ VCRIGHT_hvacFoggingRiskLevelCons m7 : 32|6@1+ (1.6,0) [0|100] "%" Vector__XXX
 SG_ VCRIGHT_hvacWindshieldRHConserva m7 : 38|6@1+ (2,0) [0|125] "%" Vector__XXX
 SG_ VCRIGHT_hvacFoggingRiskLevelFeed m7 : 44|7@1- (1.6,0) [-100|100] "%" Vector__XXX
 SG_ VCRIGHT_hvacFoggingRiskLevelInte m7 : 51|7@1- (1.6,0) [-100|100] "%" Vector__XXX
 SG_ VCRIGHT_hvacFoggingRiskLeve_0002 m7 : 58|6@1+ (1.6,0) [0|100] "%" Vector__XXX
 SG_ VCRIGHT_hvacCabOvrheatProtActive m8 : 5|1@1+ (1,0) [0|1] "" Vector__XXX
 SG_ VCRIGHT_hvacCabinPurgeAllowed m8 : 6|1@1+ (1,0) [0|1] "" Vector__XXX
 SG_ VCRIGHT_hvacCabOvrheatProtAllowe m8 : 7|1@1+ (1,0) [0|1] "" Vector__XXX
 SG_ VCRIGHT_AP_humidityModelBasedCab m8 : 8|10@1+ (0.04,0) [0|40] "g/kg" Vector__XXX
 SG_ VCRIGHT_cabinTempFanCurrent m8 : 18|6@1+ (0.001,-0.01) [-0.01|0.05] "A" Vector__XXX
 SG_ VCRIGHT_cabinTempFanOutput m8 : 24|1@1+ (1,0) [0|1] "" Vector__XXX
 SG_ VCRIGHT_cloudinessEstimatedPct m8 : 25|7@1+ (1,0) [0|100] "%" Vector__XXX
 SG_ VCRIGHT_solarLoadOnVehFiltered m8 : 32|8@1+ (4,0) [0|1016] "W/m2" Vector__XXX
 SG_ VCRIGHT_cabinTempProbeEstimate m8 : 40|8@1+ (0.5,-40) [-40|80] "degC" Vector__XXX
 SG_ VCRIGHT_cabinTempThs m8 : 48|8@1+ (0.5,-40) [-40|80] "degC" Vector__XXX
 SG_ VCRIGHT_cabinTempThsBracket m8 : 56|8@1+ (0.5,-40) [-40|80] "degC" Vector__XXX
 SG_ VCRIGHT_leftHeatOvertempProtect m9 : 5|1@1+ (1,0) [0|1] "" Vector__XXX
 SG_ VCRIGHT_rightHeatOvertempProtect m9 : 6|1@1+ (1,0) [0|1] "" Vector__XXX
 SG_ VCRIGHT_CO2ppm m9 : 7|10@1+ (5,0) [0|4000] "-" Vector__XXX
 SG_ VCRIGHT_timeLeftToCabinModelInit m9 : 17|7@1+ (1,0) [0|127] "" Vector__XXX
 SG_ VCRIGHT_hvacEstimateWindshieldRH m9 : 24|8@1+ (1,0) [0|150] "%" Vector__XXX
 SG_ VCRIGHT_hvacFoggingRiskLevel m9 : 32|7@1+ (1,0) [0|100] "%" Vector__XXX
 SG_ VCRIGHT_hvacCabinHumidityLevel m9 : 39|7@1+ (1,0) [0|100] "%" Vector__XXX
 SG_ VCRIGHT_hvacFlashFoggingDetected m9 : 47|1@1+ (1,0) [0|1] "" Vector__XXX
 SG_ VCRIGHT_solarSensitivityInfr m9 : 48|7@1+ (1,0) [0|100] "-" Vector__XXX
 SG_ VCRIGHT_solarSensitivityInfrCorr m9 : 55|7@1+ (1,0) [0|100] "-" Vector__XXX
 SG_ VCRIGHT_lumbarCurrent m10 : 5|4@1+ (0.2,0) [0|3] "A" Vector__XXX
 SG_ VCRIGHT_ocsCurrent m10 : 9|3@1+ (0.01,0) [0|0.07] "A" Vector__XXX
 SG_ VCRIGHT_rcmCurrent m10 : 12|5@1+ (0.1,0) [0|3.1] "A" Vector__XXX
 SG_ VCRIGHT_radioTunerCurrent m10 : 17|4@1+ (0.1,0) [0|1.5] "A" Vector__XXX
 SG_ VCRIGHT_rearOilPumpCurrent m10 : 21|5@1+ (0.5,0) [0|15.5] "A" Vector__XXX
 SG_ VCRIGHT_rearDefrostCurrent m10 : 26|5@1+ (2,0) [0|62] "A" Vector__XXX
 SG_ VCRIGHT_tailLightCurrent m10 : 31|4@1+ (0.1,0) [0|1.5] "A" Vector__XXX
 SG_ VCRIGHT_turnTailStopLightCurrent m10 : 35|4@1+ (0.1,0) [0|1.5] "A" Vector__XXX
 SG_ VCRIGHT_reverseFogLightsCurrent m10 : 39|4@1+ (0.1,0) [0|1.4] "A" Vector__XXX
 SG_ VCRIGHT_stopReverseTurnLightCurr m10 : 43|4@1+ (0.1,0) [0|1.5] "A" Vector__XXX
 SG_ VCRIGHT_sideMirrorCurrent m10 : 47|5@1+ (0.2,0) [0|6.2] "A" Vector__XXX
 SG_ VCRIGHT_sideMirrorHeaterCurrent m10 : 52|5@1+ (0.2,0) [0|6] "A" Vector__XXX
 SG_ VCRIGHT_frontSeatHeatCushionPwr m10 : 57|7@1+ (1,0) [0|127] "W" Vector__XXX
 SG_ VCRIGHT_trunkInteriorLEDCurrent m11 : 8|4@1+ (5,0) [0|70] "mA" Vector__XXX
 SG_ VCRIGHT_mapPocketLEDsCurrent m11 : 12|4@1+ (5,0) [0|70] "mA" Vector__XXX
 SG_ VCRIGHT_miscEFuseCurrent m11 : 16|5@1+ (0.05,0) [0|1.5] "A" Vector__XXX
 SG_ VCRIGHT_interiorHandleLEDCurrent m11 : 21|4@1+ (2,0) [0|30] "mA" Vector__XXX
 SG_ VCRIGHT_miscInteriorLightsCurren m11 : 25|3@1+ (5,0) [0|30] "mA" Vector__XXX
 SG_ VCRIGHT_frontPuddleLEDCurrent m11 : 28|3@1+ (0.05,0) [0|0.3] "A" Vector__XXX
 SG_ VCRIGHT_rearPuddleLEDCurrent m11 : 31|3@1+ (0.05,0) [0|0.3] "A" Vector__XXX
 SG_ VCRIGHT_liftgateShutfaceLEDCurre m11 : 34|3@1+ (5,0) [0|30] "mA" Vector__XXX
 SG_ VCRIGHT_3rSeatTOSCurrent m11 : 37|4@1+ (5,0) [0|70] "mA" Vector__XXX
 SG_ VCRIGHT_vbatFusedCurrent m11 : 41|4@1+ (0.1,0) [0|1.4] "A" Vector__XXX
 SG_ VCRIGHT_cabinTempGlassGridHeater m11 : 45|8@1+ (0.5,-40) [-40|80] "degC" Vector__XXX
 SG_ VCRIGHT_hvacAirflowReasonRight m11 : 53|5@1+ (1,0) [0|31] "" Vector__XXX
 SG_ VCRIGHT_hvacAirflowReasonLeft m11 : 58|5@1+ (1,0) [0|31] "" Vector__XXX
 SG_ VCRIGHT_hvacMassflowTargetLeft m12 : 5|8@1+ (1,0) [0|200] "g/s" Vector__XXX
 SG_ VCRIGHT_hvacMassflowTargetRight m12 : 13|8@1+ (1,0) [0|200] "g/s" Vector__XXX
 SG_ VCRIGHT_solarLoadLeftOccupantFil m12 : 21|7@1+ (2,0) [0|252] "W/m2" Vector__XXX
 SG_ VCRIGHT_solarLoadRightOccupantFi m12 : 28|7@1+ (2,0) [0|252] "W/m2" Vector__XXX
 SG_ VCRIGHT_windshieldRHCapped m12 : 35|8@1+ (1,0) [0|150] "%" Vector__XXX
 SG_ VCRIGHT_feedbackWarmUpScalar m12 : 43|2@1+ (16,84) [84|116] "-" Vector__XXX
 SG_ VCRIGHT_maxMassflowScalarWarmUp m12 : 45|5@1+ (1,74) [74|100] "-" Vector__XXX
 SG_ VCRIGHT_feedforwardWarmUpScalar m12 : 50|6@1+ (1,80) [80|120] "-" Vector__XXX
 SG_ VCRIGHT_frontSeatHeatBackrestPwr m12 : 56|7@1+ (1,0) [0|127] "W" Vector__XXX
 SG_ VCRIGHT_maxMassflowScalar m13 : 5|6@1+ (1,60) [60|100] "-" Vector__XXX
 SG_ VCRIGHT_massflowTargetAutoInManu m13 : 11|8@1+ (1,0) [0|250] "g/s" Vector__XXX
 SG_ VCRIGHT_airflowReasonAutoInManua m13 : 19|5@1+ (1,0) [0|31] "" Vector__XXX
 SG_ VCRIGHT_airflowReasonAutoIn_0001 m13 : 24|5@1+ (1,0) [0|31] "" Vector__XXX
 SG_ VCRIGHT_airflowReasonAutoIn_0002 m13 : 29|5@1+ (1,0) [0|31] "" Vector__XXX
 SG_ VCRIGHT_hvacTorqueMassflowQuadra m13 : 34|8@1+ (1,0) [0|250] "g/s" Vector__XXX
 SG_ VCRIGHT_vocSweatMassSeat m13 : 42|8@1+ (1,0) [0|254] "mg" Vector__XXX
 SG_ VCRIGHT_vocSweatConcentrationAir m13 : 50|8@1+ (0.1,0) [0|25.4] "mg/m3" Vector__XXX
 SG_ VCRIGHT_hvacBiLevelWhsldRhEst m13 : 58|6@1+ (2,20) [20|120] "%" Vector__XXX
 SG_ VCRIGHT_steeringWheelSurfaceTemp m14 : 5|10@1+ (0.1,-35) [-35|65] "degC" Vector__XXX
 SG_ VCRIGHT_steeringWheelSurfac_0001 m14 : 16|10@1+ (0.1,-35) [-35|65] "degC" Vector__XXX
 SG_ VCRIGHT_timeToComfortHeating m14 : 26|6@1+ (15,-15) [-15|930] "s" Vector__XXX
 SG_ VCRIGHT_timeToComfortCooling m14 : 32|6@1+ (15,-15) [-15|930] "s" Vector__XXX
 SG_ VCRIGHT_cabinWaterMassRaw m14 : 38|8@1+ (0.1,0) [0|25] "g/kg" Vector__XXX
 SG_ VCRIGHT_massflowSingleZoneSplit m14 : 46|7@1+ (1,0) [0|100] "-" Vector__XXX
 SG_ VCRIGHT_VOCPurgeState m14 : 53|3@1+ (1,0) [0|7] "" Vector__XXX
 SG_ VCRIGHT_cameraFoggingMonitorStat m14 : 56|3@1+ (1,0) [0|7] "" Vector__XXX
 SG_ VCRIGHT_windWeatherSource m14 : 59|2@1+ (1,0) [0|3] "" Vector__XXX
 SG_ VCRIGHT_humidityRatioWeatherSour m14 : 61|2@1+ (1,0) [0|3] "" Vector__XXX
 SG_ VCRIGHT_cabinOverheatProtectNotR m15 : 5|14@1+ (1,0) [0|16383] "" Vector__XXX
 SG_ VCRIGHT_hvacIntakeReason m15 : 19|5@1+ (1,0) [0|31] "" Vector__XXX
 SG_ VCRIGHT_hvacCabinPurgeActive m15 : 24|1@1+ (1,0) [0|1] "" Vector__XXX
 SG_ VCRIGHT_solarAzimuthCarRef m15 : 25|11@1- (0.5,0) [-511|511.5] "deg" Vector__XXX
 SG_ VCRIGHT_massflowPulldownBias m15 : 36|4@1+ (7,0) [0|100] "%" Vector__XXX
 SG_ VCRIGHT_evapPulldownBias m15 : 40|4@1+ (7,0) [0|100] "%" Vector__XXX
 SG_ VCRIGHT_modeledMassflowFresh m15 : 44|8@1+ (1,0) [0|255] "g/s" Vector__XXX
 SG_ VCRIGHT_modeledMassflowRecirc m15 : 52|8@1+ (1,0) [0|255] "g/s" Vector__XXX
 SG_ VCRIGHT_hvacLimpModeStatus m15 : 60|3@1+ (1,0) [0|7] "" Vector__XXX
 SG_ VCRIGHT_hvacEstimatedCameraWinds m16 : 5|8@1+ (1,0) [0|150] "%" Vector__XXX
 SG_ VCRIGHT_hvacRearVoltage m16 : 13|8@1+ (0.02,0) [0|5] "V" Vector__XXX
 SG_ VCRIGHT_cabinTempRoofL2 m16 : 21|8@1+ (0.5,-40) [-40|85] "degC" Vector__XXX
 SG_ VCRIGHT_cabinTempRoofL3 m16 : 29|8@1+ (0.5,-40) [-40|85] "degC" Vector__XXX
 SG_ VCRIGHT_odorRoutineState m16 : 37|3@1+ (1,0) [0|6] "" Vector__XXX
 SG_ VCRIGHT_rgbLedFrontCurrent m16 : 40|10@1+ (0.000488758552819,0) [0|0.499999999534] "A" Vector__XXX
 SG_ VCRIGHT_rgbLedRearCurrent m16 : 50|10@1+ (0.000488758552819,0) [0|0.499999999534] "A" Vector__XXX
 SG_ VCRIGHT_rgbLedFrontOutput m16 : 60|1@1+ (1,0) [0|1] "" Vector__XXX
 SG_ VCRIGHT_rgbLedRearOutput m16 : 61|1@1+ (1,0) [0|1] "" Vector__XXX
 SG_ VCRIGHT_cameraDefogState m16 : 62|2@1+ (1,0) [0|3] "" Vector__XXX

BO_ 1859 VCRIGHT_recallStatus: 1 VCRIGHT
 SG_ VCRIGHT_systemRecallStatus : 0|2@1+ (1,0) [1|3] "" Vector__XXX
 SG_ VCRIGHT_seatRecallStatus : 2|2@1+ (1,0) [1|3] "" Vector__XXX
 SG_ VCRIGHT_mirrorRecallStatus : 4|2@1+ (1,0) [1|3] "" Vector__XXX

BO_ 794 VCRIGHT_restraintStatus: 8 VCRIGHT
 SG_ VCRIGHT_frontOccupancyStatus : 0|3@1+ (1,0) [0|6] "" Vector__XXX
 SG_ VCRIGHT_frontBuckleStatus : 3|2@1+ (1,0) [0|3] "" Vector__XXX
 SG_ VCRIGHT_rearCenterBuckleStatus : 5|2@1+ (1,0) [0|3] "" Vector__XXX
 SG_ VCRIGHT_rearRightBuckleStatus : 8|2@1+ (1,0) [0|3] "" Vector__XXX
 SG_ VCRIGHT_rearRightOccupancyStatus : 10|2@1+ (1,0) [0|3] "" Vector__XXX
 SG_ VCRIGHT_3RowLeftBuckleStatus : 12|2@1+ (1,0) [0|3] "" Vector__XXX
 SG_ VCRIGHT_3RowRightBuckleStatus : 14|2@1+ (1,0) [0|3] "" Vector__XXX
 SG_ VCRIGHT_3RowLeftOccupancyStatus : 16|2@1+ (1,0) [0|3] "" Vector__XXX
 SG_ VCRIGHT_3RowRightOccupancyStatus : 18|2@1+ (1,0) [0|3] "" Vector__XXX
 SG_ VCRIGHT_seatTrackPosition : 20|3@1+ (1,0) [0|6] "" Vector__XXX
 SG_ VCRIGHT_occupantClassification : 23|3@1+ (1,0) [0|6] "" Vector__XXX
 SG_ VCRIGHT_occupantClassificationQF : 26|1@1+ (1,0) [0|1] "" Vector__XXX
 SG_ VCRIGHT_classificationEnabled : 27|1@1+ (1,0) [0|1] "" Vector__XXX
 SG_ VCRIGHT_classificationEnabledQF : 28|1@1+ (1,0) [0|1] "" Vector__XXX
 SG_ VCRIGHT_3RowRightABStatus : 30|2@1+ (1,0) [0|3] "" Vector__XXX
 SG_ VCRIGHT_restraintStatusCounter : 52|4@1+ (1,0) [0|15] "" Vector__XXX
 SG_ VCRIGHT_restraintStatusChecksum : 56|8@1+ (1,0) [0|255] "" Vector__XXX

BO_ 1251 VCRIGHT_seatStatus: 8 VCRIGHT
 SG_ VCRIGHT_seatStatusIndex M : 0|3@1+ (1,0) [0|7] "" Vector__XXX
 SG_ VC_AH_1RowRightSeatMovementHealt m0 : 5|3@1+ (1,0) [0|7] "" Vector__XXX
 SG_ VCRIGHT_frontSeatTrackPos m0 : 8|16@1- (1,0) [-32768|32767] "" Vector__XXX
 SG_ VCRIGHT_frontSeatTrackCurrent m0 : 24|12@1- (0.01,0) [-20.48|20.47] "A" Vector__XXX
 SG_ VCRIGHT_frontSeatTrackDuty m0 : 36|12@1- (0.1,0) [-204.8|204.7] "%" Vector__XXX
 SG_ VCRIGHT_frontSeatTrackState m0 : 48|3@1+ (1,0) [0|7] "" Vector__XXX
 SG_ VCRIGHT_frontSeatTrackCalibrated m0 : 51|1@1+ (1,0) [0|1] "" Vector__XXX
 SG_ VCRIGHT_frontSeatTrackLog m0 : 52|1@1+ (1,0) [0|1] "" Vector__XXX
 SG_ VCRIGHT_frontSeatTrackBridgeSt m0 : 53|2@1+ (1,0) [0|3] "" Vector__XXX
 SG_ VCRIGHT_frontSeatTrackPercentage m0 : 55|7@1+ (1,0) [0|100] "%" Vector__XXX
 SG_ VCRIGHT_frontSeatBackPos m1 : 8|16@1- (1,0) [-32768|32767] "" Vector__XXX
 SG_ VCRIGHT_frontSeatBackCurrent m1 : 24|12@1- (0.01,0) [-20.48|20.47] "A" Vector__XXX
 SG_ VCRIGHT_frontSeatBackDuty m1 : 36|12@1- (0.1,0) [-204.8|204.7] "%" Vector__XXX
 SG_ VCRIGHT_frontSeatBackState m1 : 48|3@1+ (1,0) [0|7] "" Vector__XXX
 SG_ VCRIGHT_frontSeatBackCalibrated m1 : 51|1@1+ (1,0) [0|1] "" Vector__XXX
 SG_ VCRIGHT_frontSeatBackLog m1 : 52|1@1+ (1,0) [0|1] "" Vector__XXX
 SG_ VCRIGHT_frontSeatBackBridgeSt m1 : 53|2@1+ (1,0) [0|3] "" Vector__XXX
 SG_ VCRIGHT_frontSeatBackPercentage m1 : 55|7@1+ (1,0) [0|100] "%" Vector__XXX
 SG_ VCRIGHT_frontSeatLiftPos m2 : 8|16@1- (1,0) [-32768|32767] "" Vector__XXX
 SG_ VCRIGHT_frontSeatLiftCurrent m2 : 24|12@1- (0.01,0) [-20.48|20.47] "A" Vector__XXX
 SG_ VCRIGHT_frontSeatLiftDuty m2 : 36|12@1- (0.1,0) [-204.8|204.7] "%" Vector__XXX
 SG_ VCRIGHT_frontSeatLiftState m2 : 48|3@1+ (1,0) [0|7] "" Vector__XXX
 SG_ VCRIGHT_frontSeatLiftCalibrated m2 : 51|1@1+ (1,0) [0|1] "" Vector__XXX
 SG_ VCRIGHT_frontSeatLiftLog m2 : 52|1@1+ (1,0) [0|1] "" Vector__XXX
 SG_ VCRIGHT_frontSeatLiftBridgeSt m2 : 53|2@1+ (1,0) [0|3] "" Vector__XXX
 SG_ VCRIGHT_frontSeatLiftPercentage m2 : 55|7@1+ (1,0) [0|100] "%" Vector__XXX
 SG_ VCRIGHT_frontSeatTiltPos m3 : 8|16@1- (1,0) [-32768|32767] "" Vector__XXX
 SG_ VCRIGHT_frontSeatTiltCurrent m3 : 24|12@1- (0.01,0) [-20.48|20.47] "A" Vector__XXX
 SG_ VCRIGHT_frontSeatTiltDuty m3 : 36|12@1- (0.1,0) [-204.8|204.7] "%" Vector__XXX
 SG_ VCRIGHT_frontSeatTiltState m3 : 48|3@1+ (1,0) [0|7] "" Vector__XXX
 SG_ VCRIGHT_frontSeatTiltCalibrated m3 : 51|1@1+ (1,0) [0|1] "" Vector__XXX
 SG_ VCRIGHT_frontSeatTiltLog m3 : 52|1@1+ (1,0) [0|1] "" Vector__XXX
 SG_ VCRIGHT_frontSeatTiltBridgeSt m3 : 53|2@1+ (1,0) [0|3] "" Vector__XXX
 SG_ VCRIGHT_frontSeatTiltPercentage m3 : 55|7@1+ (1,0) [0|100] "%" Vector__XXX
 SG_ VCRIGHT_lumbarAState m4 : 3|3@1+ (1,0) [0|7] "" Vector__XXX
 SG_ VCRIGHT_lumbarBState m4 : 6|3@1+ (1,0) [0|7] "" Vector__XXX
 SG_ VCRIGHT_lumbarAPressureHpa m4 : 9|12@1+ (1,0) [0|4095] "" Vector__XXX
 SG_ VCRIGHT_lumbarAPressureHpaFilt m4 : 21|10@1+ (1,0) [0|1023] "" Vector__XXX
 SG_ VCRIGHT_lumbarBPressureHpa m4 : 31|12@1+ (1,0) [0|4095] "" Vector__XXX
 SG_ VCRIGHT_lumbarBPressureHpaFilt m4 : 43|10@1+ (1,0) [0|1023] "" Vector__XXX
 SG_ VCRIGHT_lumbarActiveTooLongErr m4 : 53|1@1+ (1,0) [0|1] "" Vector__XXX
 SG_ VCRIGHT_lumbarMaxPErr m4 : 54|1@1+ (1,0) [0|1] "" Vector__XXX
 SG_ VCRIGHT_lumbarOvercurrentErr m4 : 55|1@1+ (1,0) [0|1] "" Vector__XXX
 SG_ VCRIGHT_lumbarMaxOperatingPErr m4 : 56|1@1+ (1,0) [0|1] "" Vector__XXX
 SG_ VCRIGHT_lumbarMinPErr m4 : 57|1@1+ (1,0) [0|1] "" Vector__XXX
 SG_ VCRIGHT_lumbarGeneralErr m4 : 58|1@1+ (1,0) [0|1] "" Vector__XXX
 SG_ VCRIGHT_lumbarDevMaxPumpPressA m4 : 59|1@1+ (1,0) [0|1] "" Vector__XXX
 SG_ VCRIGHT_lumbarDevMaxPumpPressB m4 : 60|1@1+ (1,0) [0|1] "" Vector__XXX
 SG_ VCRIGHT_frontSeatTrackPosReal m5 : 3|12@1- (1,0) [-2048|2047] "mm" Vector__XXX
 SG_ VCRIGHT_frontSeatBackPosReal m5 : 16|12@1- (0.1,0) [-204.8|204.7] "deg" Vector__XXX
 SG_ VCRIGHT_frontSeatLiftPosReal m5 : 28|12@1- (1,0) [-2048|2047] "mm" Vector__XXX
 SG_ VCRIGHT_frontSeatTiltPosReal m5 : 40|12@1- (0.1,0) [-204.8|204.7] "deg" Vector__XXX
 SG_ VCRIGHT_frontSeatThighSuppo_0001 m5 : 52|12@1- (1,0) [-2048|2047] "mm" Vector__XXX
 SG_ VCRIGHT_frontSeatTrackPosOffset m6 : 3|12@1- (1,0) [-2048|2047] "mm" Vector__XXX
 SG_ VCRIGHT_frontSeatBackPosOffset m6 : 16|12@1- (0.1,0) [-204.8|204.7] "deg" Vector__XXX
 SG_ VCRIGHT_frontSeatLiftPosOffset m6 : 28|12@1- (1,0) [-2048|2047] "mm" Vector__XXX
 SG_ VCRIGHT_frontSeatTiltPosOffset m6 : 40|12@1- (0.1,0) [-204.8|204.7] "deg" Vector__XXX
 SG_ VCRIGHT_frontSeatThighSupportPos m6 : 52|12@1- (1,0) [-2048|2047] "mm" Vector__XXX
 SG_ VCRIGHT_lumbarAPressurePercentag m7 : 3|7@1+ (1,0) [0|100] "%" Vector__XXX
 SG_ VCRIGHT_lumbarBPressurePercentag m7 : 10|7@1+ (1,0) [0|100] "%" Vector__XXX

BO_ 739 VCRIGHT_seatStatus2: 7 VCRIGHT
 SG_ VCRIGHT_seatStatus2Index M : 0|4@1+ (1,0) [0|15] "" Vector__XXX
 SG_ VCRIGHT_frontSeatHeatCurrent m0 : 4|12@1+ (0.01,0) [0|40.95] "A" Vector__XXX
 SG_ VCRIGHT_frontSeatHeatDuty m0 : 16|8@1+ (1,0) [0|255] "%" Vector__XXX
 SG_ VCRIGHT_frontSeatHeatTmp m0 : 24|12@1- (0.05,0) [-40|80] "degC" Vector__XXX
 SG_ VCRIGHT_frontSeatHeatTmpTarget m0 : 36|8@1- (0.5,0) [0|60] "degC" Vector__XXX
 SG_ VCRIGHT_frontSeatHeatInhibited m0 : 44|1@1+ (1,0) [0|1] "" Vector__XXX
 SG_ VCRIGHT_frontSeatHeatPowered m0 : 45|1@1+ (1,0) [0|1] "" Vector__XXX
 SG_ VC_AH_1RowRightSeatHeatVentHealt m0 : 54|2@1+ (1,0) [0|3] "" Vector__XXX
 SG_ VCRIGHT_rearLSeatHeatCurrent m1 : 4|12@1+ (0.01,0) [0|40.95] "A" Vector__XXX
 SG_ VCRIGHT_rearLSeatHeatDuty m1 : 16|8@1+ (1,0) [0|255] "%" Vector__XXX
 SG_ VCRIGHT_rearLSeatHeatTmp m1 : 24|12@1- (0.05,0) [-40|80] "degC" Vector__XXX
 SG_ VCRIGHT_rearLSeatHeatTmpTarget m1 : 36|8@1- (0.5,0) [0|60] "degC" Vector__XXX
 SG_ VCRIGHT_rearLSeatHeatInhibited m1 : 44|1@1+ (1,0) [0|1] "" Vector__XXX
 SG_ VCRIGHT_rearLSeatHeatPowered m1 : 45|1@1+ (1,0) [0|1] "" Vector__XXX
 SG_ VCRIGHT_rearCSeatHeatCurrent m2 : 4|12@1+ (0.01,0) [0|40.95] "A" Vector__XXX
 SG_ VCRIGHT_rearCSeatHeatDuty m2 : 16|8@1+ (1,0) [0|255] "%" Vector__XXX
 SG_ VCRIGHT_rearCSeatHeatTmp m2 : 24|12@1- (0.05,0) [-40|80] "degC" Vector__XXX
 SG_ VCRIGHT_rearCSeatHeatTmpTarget m2 : 36|8@1- (0.5,0) [0|60] "degC" Vector__XXX
 SG_ VCRIGHT_rearCSeatHeatInhibited m2 : 44|1@1+ (1,0) [0|1] "" Vector__XXX
 SG_ VCRIGHT_rearCSeatHeatPowered m2 : 45|1@1+ (1,0) [0|1] "" Vector__XXX
 SG_ VCRIGHT_rearRSeatHeatCurrent m3 : 4|12@1+ (0.01,0) [0|40.95] "A" Vector__XXX
 SG_ VCRIGHT_rearRSeatHeatDuty m3 : 16|8@1+ (1,0) [0|255] "%" Vector__XXX
 SG_ VCRIGHT_rearRSeatHeatTmp m3 : 24|12@1- (0.05,0) [-40|80] "degC" Vector__XXX
 SG_ VCRIGHT_rearRSeatHeatTmpTarget m3 : 36|8@1- (0.5,0) [0|60] "degC" Vector__XXX
 SG_ VCRIGHT_rearRSeatHeatInhibited m3 : 44|1@1+ (1,0) [0|1] "" Vector__XXX
 SG_ VCRIGHT_rearRSeatHeatPowered m3 : 45|1@1+ (1,0) [0|1] "" Vector__XXX
 SG_ VCRIGHT_2RowSeatReclineState m11 : 4|4@1+ (1,0) [0|14] "" Vector__XXX
 SG_ VCRIGHT_2RowSeatReclineDuty m11 : 8|8@1- (1,0) [-100|100] "%" Vector__XXX
 SG_ VCRIGHT_2RowSeatReclineCurrent m11 : 16|12@1- (0.05,0) [-100|100] "A" Vector__XXX
 SG_ VCRIGHT_2RowSeatReclineCalibrate m11 : 28|1@1+ (1,0) [0|1] "" Vector__XXX
 SG_ VCRIGHT_2RowSeatReclinePositionR m11 : 29|12@1- (1,0) [-2048|2047] "" Vector__XXX
 SG_ VCRIGHT_2RowSeatReclineAngle m11 : 41|12@1- (0.1,0) [-204.8|204.7] "deg" Vector__XXX
 SG_ VCRIGHT_2RowSeatReclineAbsPosSwi m11 : 53|2@1+ (1,0) [1|3] "" Vector__XXX
 SG_ VCRIGHT_2RowSeatReclinePositionS m12 : 4|3@1+ (1,0) [0|7] "" Vector__XXX
 SG_ VCRIGHT_2RowSeatReclineAdjustmen m12 : 7|1@1+ (1,0) [0|1] "" Vector__XXX
 SG_ VCRIGHT_2RowSeatReclineFoldAllow m12 : 8|1@1+ (1,0) [0|1] "" Vector__XXX
 SG_ VCRIGHT_2RowSeatReclineUnfoldAll m12 : 9|1@1+ (1,0) [0|1] "" Vector__XXX
 SG_ VCRIGHT_2RowSeatReclineNextToggl m12 : 10|2@1+ (1,0) [0|3] "" Vector__XXX
 SG_ VCRIGHT_2RowSeatReclineChoreoBlo m12 : 12|1@1+ (1,0) [0|1] "" Vector__XXX
 SG_ VCRIGHT_2RowSeat1RClashAvoidance m12 : 13|3@1+ (1,0) [0|7] "" Vector__XXX
 SG_ VCRIGHT_2RowSeat1RClashAvoi_0001 m12 : 16|2@1+ (1,0) [0|3] "" Vector__XXX
 SG_ VCRIGHT_2RowSeatReclineAbsP_0001 m12 : 18|12@1- (0.1,0) [-204.8|204.7] "deg" Vector__XXX
 SG_ VC_AH_2RowRightSeatMovementHealt m12 : 53|3@1+ (1,0) [0|7] "" Vector__XXX
 SG_ VCRIGHT_3RowSeatReclineState m14 : 4|4@1+ (1,0) [0|14] "" Vector__XXX
 SG_ VCRIGHT_3RowSeatReclineDuty m14 : 8|8@1- (1,0) [-100|100] "%" Vector__XXX
 SG_ VCRIGHT_3RowSeatReclineCurrent m14 : 16|12@1- (0.05,0) [-100|100] "A" Vector__XXX
 SG_ VCRIGHT_3RowSeatReclineCalibrate m14 : 28|1@1+ (1,0) [0|1] "" Vector__XXX
 SG_ VCRIGHT_3RowSeatReclinePositionR m14 : 29|12@1- (1,0) [-2048|2047] "" Vector__XXX
 SG_ VCRIGHT_3RowSeatReclineAngle m14 : 41|12@1- (0.1,0) [-204.8|204.7] "deg" Vector__XXX
 SG_ VCRIGHT_3RowSeatReclineNextToggl m14 : 53|2@1+ (1,0) [0|3] "" Vector__XXX
 SG_ VCRIGHT_3RRightSeatHeatCurrent m15 : 5|12@1+ (0.01,0) [0|40.95] "A" Vector__XXX
 SG_ VCRIGHT_3RRightSeatHeatDuty m15 : 17|8@1- (1,0) [-100|100] "%" Vector__XXX
 SG_ VCRIGHT_3RRightSeatHeatTmp m15 : 25|12@1- (0.05,0) [-40|80] "degC" Vector__XXX
 SG_ VCRIGHT_3RRightSeatHeatTmpTarget m15 : 37|8@1- (0.5,0) [0|60] "degC" Vector__XXX
 SG_ VCRIGHT_3RRightSeatHeatInhibited m15 : 45|1@1+ (1,0) [0|1] "" Vector__XXX
 SG_ VCRIGHT_3RowSeatReclinePositionS m15 : 46|3@1+ (1,0) [0|7] "" Vector__XXX
 SG_ VCRIGHT_3RowSeatReclineAdjustmen m15 : 49|1@1+ (1,0) [0|1] "" Vector__XXX
 SG_ VCRIGHT_3RowSeatReclineFoldAllow m15 : 50|1@1+ (1,0) [0|1] "" Vector__XXX
 SG_ VCRIGHT_3RowSeatReclineUnfoldAll m15 : 51|1@1+ (1,0) [0|1] "" Vector__XXX
 SG_ VCRIGHT_3RowSeatReclineChoreoBlo m15 : 52|1@1+ (1,0) [0|1] "" Vector__XXX
 SG_ VCRIGHT_3RowSeatReclineAbsPosSwi m15 : 53|2@1+ (1,0) [1|3] "" Vector__XXX

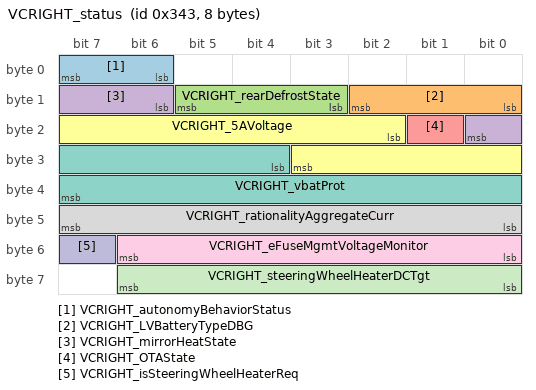
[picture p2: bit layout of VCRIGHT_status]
BO_ 835 VCRIGHT_status: 8 VCRIGHT
 SG_ VCRIGHT_autonomyBehaviorStatus : 6|2@1+ (1,0) [0|3] "" Vector__XXX
 SG_ VCRIGHT_LVBatteryTypeDBG : 8|3@1+ (1,0) [0|7] "" Vector__XXX
 SG_ VCRIGHT_rearDefrostState : 11|3@1+ (1,0) [1|7] "" Vector__XXX
 SG_ VCRIGHT_mirrorHeatState : 14|3@1+ (1,0) [1|7] "" Vector__XXX
 SG_ VCRIGHT_OTAState : 17|1@1+ (1,0) [0|1] "" Vector__XXX
 SG_ VCRIGHT_5AVoltage : 18|10@1+ (0.005443676,0) [0|5.568880548] "V" Vector__XXX
 SG_ VCRIGHT_vbatProt : 28|12@1+ (0.005443676,0) [0|22.29185322] "V" Vector__XXX
 SG_ VCRIGHT_rationalityAggregateCurr : 40|8@1+ (0.5,0) [0|127.5] "A" Vector__XXX
 SG_ VCRIGHT_eFuseMgmtVoltageMonitor : 48|7@1+ (0.125,0) [0|15.875] "V" Vector__XXX
 SG_ VCRIGHT_isSteeringWheelHeaterReq : 55|1@1+ (1,0) [0|1] "" Vector__XXX
 SG_ VCRIGHT_steeringWheelHeaterDCTgt : 56|7@1+ (0.01,0) [0|1] "-" Vector__XXX

BO_TX_BU_ 524 : VCRIGHT;
BO_TX_BU_ 579 : VCRIGHT;
BO_TX_BU_ 1675 : VCRIGHT;
BO_TX_BU_ 771 : VCRIGHT;
BO_TX_BU_ 995 : VCRIGHT;
BO_TX_BU_ 1803 : VCRIGHT;
BO_TX_BU_ 611 : VCRIGHT;
BO_TX_BU_ 691 : VCRIGHT;
BO_TX_BU_ 1859 : VCRIGHT;
BO_TX_BU_ 794 : VCRIGHT;
BO_TX_BU_ 1251 : VCRIGHT;
BO_TX_BU_ 739 : VCRIGHT;
BO_TX_BU_ 835 : VCRIGHT;
CM_ BO_ 524 "Right body controller message: hvac request; frame length observed on a vehicle bus";
CM_ SG_ 524 VCRIGHT_wattsDemandEvap "Right body controller: watts demand evap";
CM_ SG_ 524 VCRIGHT_hvacEvapEnabled "Right body controller: hvac evap enabled";
CM_ SG_ 524 VCRIGHT_conditioningRequest "Right body controller: conditioning request";
CM_ SG_ 524 VCRIGHT_tempEvaporator "Evaporator temperature; raw 2047 = signal not available (SNA)";
CM_ SG_ 524 VCRIGHT_tempEvaporatorTarget "Evaporator temperature target; raw 255 = signal not available (SNA)";
CM_ SG_ 524 VCRIGHT_hvacBlowerSpeedRPMReq "Right body controller: hvac blower speed RPM req";
CM_ SG_ 524 VCRIGHT_hvacPerfTestRunning "Right body controller: hvac perf test running";
CM_ SG_ 524 VCRIGHT_evapPerformanceLow "Right body controller: evap performance low";
CM_ SG_ 524 VCRIGHT_tempAmbientRaw "Right body controller: temp ambient raw; raw 0 = signal not available (SNA)";
CM_ SG_ 524 VCRIGHT_hvacHeatingEnabledLeft "Right body controller: hvac heating enabled left";
CM_ SG_ 524 VCRIGHT_hvacHeatingEnabledRight "Right body controller: hvac heating enabled right";
CM_ SG_ 524 VCRIGHT_hvacPerfTestState "The HVAC performance test running state";
CM_ SG_ 524 VCRIGHT_hvacUnavailable "Right body controller: hvac unavailable";
CM_ SG_ 524 VCRIGHT_hvacBlowerRPMActualAP "Right body controller: hvac blower RPM actual AP";
CM_ SG_ 524 VCRIGHT_hvacEvapEnabledInColdAmb "Right body controller: hvac evap enabled in cold ambient";
CM_ BO_ 579 "Right body controller message: hvac status; frame length observed on a vehicle bus";
CM_ SG_ 579 VCRIGHT_hvacStatusIndex "Right body controller: hvac status index";
CM_ SG_ 579 VCRIGHT_warmingUpStatus "Right body controller: warming up status";
CM_ SG_ 579 VCRIGHT_coolingDownStatus "Right body controller: cooling down status";
CM_ SG_ 579 VCRIGHT_childModeHVACState "Right body controller: child mode HVAC state";
CM_ SG_ 579 VCRIGHT_dogModeState "Reports the state of Dog Mode.";
CM_ SG_ 579 VCRIGHT_hvacCabinTempEstValid "Right body controller: hvac cabin temp est valid";
CM_ SG_ 579 VCRIGHT_COPNotRunningReasonFilte "Reports the reason cabin overheat protection is not running for User Interface (UI).";
CM_ SG_ 579 VCRIGHT_hvacCabinTempEst "Estimated temperature of the cabin";
CM_ SG_ 579 VCRIGHT_hvacAirDistributionMode "Cabin airflow distribution";
CM_ SG_ 579 VCRIGHT_hvacBlowerSegment "Cabin airflow blower set speed segment";
CM_ SG_ 579 VCRIGHT_hvacRecirc "UI airflow recirculation request state";
CM_ SG_ 579 VCRIGHT_hvacACRunning "Air conditioning is active";
CM_ SG_ 579 VCRIGHT_hvacPowerState "Commanded HVAC power state from UI";
CM_ SG_ 579 VCRIGHT_hvacVentStatus "HVAC vent status";
CM_ SG_ 579 VCRIGHT_hvacSecondRowState "Right body controller: hvac second row state";
CM_ SG_ 579 VCRIGHT_hvacSystemNominal "HVAC system state";
CM_ SG_ 579 VCRIGHT_hvacModelInitStatus "Right body controller: hvac model init status";
CM_ SG_ 579 VCRIGHT_hvacMassflowRefrigSysRig "Right body controller: hvac massflow refrig sys right";
CM_ SG_ 579 VCRIGHT_hvacRecircDoorPercent "Reports the HVAC air recirculation massflow fraction target.";
CM_ SG_ 579 VCRIGHT_tempDuctLeft "Fusion of upper and lower left duct temp sensor values for Heat Pump HVAC case, Raw left/right duct temp sensor value for the legacy HVAC case; raw 255 = signal not available (SNA)";
CM_ SG_ 579 VCRIGHT_hvacMassflowRefrigSystem "Right body controller: hvac massflow refrig system";
CM_ SG_ 579 VCRIGHT_tempDuctRight "Fusion of upper and lower right duct temp sensor values for Heat Pump HVAC case, Raw left/right duct temp sensor value for the legacy HVAC case; raw 255 = signal not available (SNA)";
CM_ SG_ 579 VCRIGHT_hvacMassflowRefrigSysLef "Right body controller: hvac massflow refrig sys left";
CM_ SG_ 579 VCRIGHT_hvacDuctTargetLeft "Left airflow duct temperature target; raw 255 = signal not available (SNA)";
CM_ SG_ 579 VCRIGHT_hvacDuctTargetRight "Right airflow duct temperature target; raw 255 = signal not available (SNA)";
CM_ SG_ 579 VCRIGHT_enableTripleCameraFanPow "Right body controller: enable triple camera fan power in sleep";
CM_ SG_ 579 VCRIGHT_tempDuctRightUpper "Right body controller: temp duct right upper; raw 255 = signal not available (SNA)";
CM_ SG_ 579 VCRIGHT_hpSplitTempsEnabled "Right body controller: hp split temps enabled";
CM_ SG_ 579 VCRIGHT_hvacEvapInletTempEstimat "Right body controller: hvac evap inlet temp estimate; raw 1023 = signal not available (SNA)";
CM_ SG_ 579 VCRIGHT_tempMonitorNotNominal "Right body controller: temp monitor not nominal";
CM_ SG_ 579 VCRIGHT_hvacCabinAtTempTarget "Cabin has reached target temp, send signal to UI";
CM_ SG_ 579 VCRIGHT_hvacReqSecondRow "Right body controller: hvac req second row";
CM_ SG_ 579 VCRIGHT_hvacAirflowReason "Reason for cabin airflow";
CM_ SG_ 579 VCRIGHT_autoHvacBlowerShouldLimi "Cabin airflow blower auto set speed recommendation based on NVH";
CM_ SG_ 579 VCRIGHT_hvacReqThirdRow "Right body controller: hvac req third row";
CM_ SG_ 579 VCRIGHT_solarLoadOnVehicle "Right body controller: solar load on vehicle; raw 255 = signal not available (SNA)";
CM_ SG_ 579 VCRIGHT_refrigDistCommanded "The HVAC system has set its settings to run the refrigerant distribution routine";
CM_ SG_ 579 VCRIGHT_hvacFrontRightSeatFanSta "Right body controller: hvac front right seat fan status";
CM_ SG_ 579 VCRIGHT_hvacFrontLeftSeatFanStat "Right body controller: hvac front left seat fan status";
CM_ SG_ 579 VCRIGHT_hvacRefHighPowerRequest "Right body controller: hvac ref high power request";
CM_ SG_ 579 VCRIGHT_windshieldCameraHeaterDu "Right body controller: windshield camera heater duty request";
CM_ SG_ 579 VCRIGHT_extendedHvacPerfTestSupp "The extended HVAC performance test running state";
CM_ SG_ 579 VCRIGHT_hvacFrontRightSeatHeatSt "Right body controller: hvac front right seat heat status";
CM_ SG_ 579 VCRIGHT_hvacSeatFrontLeftTempTar "Front left seat heating target temperature";
CM_ SG_ 579 VCRIGHT_hvacManualToAutoNotify "Right body controller: hvac manual to auto notify";
CM_ SG_ 579 VCRIGHT_hvacRequestsFullAuto "Request that the UI go to full auto HVAC mode";
CM_ SG_ 579 VCRIGHT_passengerPresentHvacCycl "Right body controller: passenger present hvac cycle";
CM_ SG_ 579 VCRIGHT_hvacRequestsAutoIntake "Request that the UI go to auto intake HVAC mode";
CM_ SG_ 579 VCRIGHT_steeringWheelHeatStatus "Right body controller: steering wheel heat status";
CM_ SG_ 579 VCRIGHT_autoDefogStatus "Indicates defog status of auto HVAC, used for providing messaging to the user";
CM_ SG_ 579 VCRIGHT_solarElevation "Right body controller: solar elevation; raw 256 = signal not available (SNA)";
CM_ SG_ 579 VCRIGHT_minsToSunrise "Right body controller: mins to sunrise; raw 255 = signal not available (SNA)";
CM_ SG_ 579 VCRIGHT_minsToSunset "Right body controller: mins to sunset; raw 255 = signal not available (SNA)";
CM_ SG_ 579 VCRIGHT_hvacLimitedReasonRight "Right body controller: hvac limited reason right";
CM_ SG_ 579 VCRIGHT_hvacLimitedReasonLeft "Right body controller: hvac limited reason left";
CM_ SG_ 579 VCRIGHT_hvacOverheatProtActive "Status of cabin overheat protection";
CM_ SG_ 579 VCRIGHT_autoSwingAvailable "Right body controller: auto swing available";
CM_ SG_ 579 VCRIGHT_tempDuctLeftUpper "Right body controller: temp duct left upper; raw 255 = signal not available (SNA)";
CM_ SG_ 579 VCRIGHT_hvacFrontLeftSeatHeatSta "Right body controller: hvac front left seat heat status";
CM_ SG_ 579 VCRIGHT_hvacQdotLeft "Right body controller: hvac qdot left";
CM_ SG_ 579 VCRIGHT_hvacQdotRight "Right body controller: hvac qdot right";
CM_ SG_ 579 VCRIGHT_tempDuctLeftLower "Right body controller: temp duct left lower; raw 255 = signal not available (SNA)";
CM_ SG_ 579 VCRIGHT_tempDuctRightLower "Right body controller: temp duct right lower; raw 255 = signal not available (SNA)";
CM_ SG_ 579 VCRIGHT_foggingControllerResetRe "Right body controller: fogging controller reset reason";
CM_ SG_ 579 VCRIGHT_modeledCabinPressure "Right body controller: modeled cabin pressure";
CM_ SG_ 579 VCRIGHT_blowerTorqueIndex "Right body controller: blower torque index";
CM_ SG_ 579 VCRIGHT_autoSwingLeftPosX "Right body controller: auto swing left pos x";
CM_ SG_ 579 VCRIGHT_autoSwingRightPositionX "Right body controller: auto swing right position x";
CM_ BO_ 1675 "Right body controller message: hvac status2; frame length from the layout, not yet observed on a vehicle bus";
CM_ SG_ 1675 VCRIGHT_hvacSeat1RLCushionFanTrg "Right body controller: hvac seat1 RL cushion fan trgt";
CM_ SG_ 1675 VCRIGHT_hvacSeat1RLBackrestFanTr "Right body controller: hvac seat1 RL backrest fan trgt";
CM_ SG_ 1675 VCRIGHT_hvacSeat1RRCushionFanTrg "Right body controller: hvac seat1 RR cushion fan trgt";
CM_ SG_ 1675 VCRIGHT_hvacSeat1RRBackrestFanTr "Right body controller: hvac seat1 RR backrest fan trgt";
CM_ SG_ 1675 VCRIGHT_hvac2RActuatorsEnable "Right body controller: hvac2 r actuators enable";
CM_ SG_ 1675 VCRIGHT_hvac2RLeftLateralTarget "Right body controller: hvac2 r left lateral target";
CM_ SG_ 1675 VCRIGHT_hvac2RLeftVerticalTarget "Right body controller: hvac2 r left vertical target";
CM_ SG_ 1675 VCRIGHT_hvac2RRightLateralTarget "Right body controller: hvac2 r right lateral target";
CM_ SG_ 1675 VCRIGHT_hvac2RRightVerticalTarge "Right body controller: hvac2 r right vertical target";
CM_ BO_ 771 "Right body controller message: info; frame length observed on a vehicle bus";
CM_ SG_ 771 VCRIGHT_infoIndex "Right body controller: info index";
CM_ SG_ 771 VCRIGHT_infoBuildType "Right body controller: info build type";
CM_ SG_ 771 VCRIGHT_infoBuildConfigId "Right body controller: info build config id";
CM_ SG_ 771 VCRIGHT_infoHardwareId "Right body controller: info hardware id";
CM_ SG_ 771 VCRIGHT_infoComponentId "Right body controller: info component id";
CM_ SG_ 771 VCRIGHT_infoPcbaId "Right body controller: info pcba id";
CM_ SG_ 771 VCRIGHT_infoAssemblyId "Right body controller: info assembly id; raw 255 = signal not available (SNA)";
CM_ SG_ 771 VCRIGHT_infoUsageId "Right body controller: info usage id";
CM_ SG_ 771 VCRIGHT_infoSubUsageId "Right body controller: info sub usage id";
CM_ SG_ 771 VCRIGHT_infoAppCrc "Right body controller: info app crc";
CM_ SG_ 771 VCRIGHT_infoLUMBARRAppCRC "Right body controller: info LUMBARR app CRC";
CM_ SG_ 771 VCRIGHT_infoAppGitHash "Right body controller: info app git hash";
CM_ SG_ 771 VCRIGHT_infoBootGitHash "Right body controller: info boot git hash";
CM_ SG_ 771 VCRIGHT_infoPlatformType "Right body controller: info platform type";
CM_ SG_ 771 VCRIGHT_infoBootUdsProtoVersion "Right body controller: info boot uds proto version";
CM_ SG_ 771 VCRIGHT_infoBootCrc "Right body controller: info boot crc";
CM_ BO_ 995 "Right body controller message: light status; frame length observed on a vehicle bus";
CM_ SG_ 995 VCRIGHT_brakeLightStatus "Status of rear right brake light source; raw 3 = signal not available (SNA)";
CM_ SG_ 995 VCRIGHT_tailLightStatus "Status of right tail (rear position) light source; raw 3 = signal not available (SNA)";
CM_ SG_ 995 VCRIGHT_turnSignalStatus "Status of rear right turn signal light source; raw 3 = signal not available (SNA)";
CM_ SG_ 995 VCRIGHT_reverseLightStatus "Status of the reverse light source(s); raw 3 = signal not available (SNA)";
CM_ SG_ 995 VCRIGHT_rearFogLightStatus "The desired on/off state of the rear fog light source(s); raw 3 = signal not available (SNA)";
CM_ SG_ 995 VCRIGHT_leftInteriorTrunkLightRe "Right body controller: left interior trunk light req";
CM_ SG_ 995 VCRIGHT_audioCurrentSpikeDetecte "Right body controller: audio current spike detected";
CM_ SG_ 995 VCRIGHT_fasciaReverseLightStatus "Status of fascia reverse lamp; raw 3 = signal not available (SNA)";
CM_ SG_ 995 VCRIGHT_fasciaRearFogStatus "Status of fascia rear fog lamp; raw 3 = signal not available (SNA)";
CM_ SG_ 995 VCRIGHT_fasciaTailLightStatus "Status of fascia tail lamp; raw 3 = signal not available (SNA)";
CM_ SG_ 995 VCRIGHT_fasciaLeftTurnSignalStat "Status of fascia left turn signal; raw 3 = signal not available (SNA)";
CM_ SG_ 995 VCRIGHT_fasciaRightTurnSignalSta "Status of fascia right turn signal; raw 3 = signal not available (SNA)";
CM_ SG_ 995 VCRIGHT_CHMSLLightStatus "Status of center high mount stop lamp; raw 3 = signal not available (SNA)";
CM_ BO_ 1803 "Right body controller message: logging0point1 hz; frame length observed on a vehicle bus";
CM_ SG_ 1803 VCRIGHT_logging0point1HzIndex "Right body controller: logging0point1 hz index";
CM_ SG_ 1803 VCRIGHT_glareShieldEstimatedResi "Reports estimated resistance of the glare shield heater.";
CM_ SG_ 1803 VCRIGHT_cabinAirFilterLifeRemain "Life remaining on the cabin air filter";
CM_ SG_ 1803 VCRIGHT_HEPAAirFilterLifeRemaini "Life remaining on the cabin air filter";
CM_ SG_ 1803 VCRIGHT_leftPTCCompromisedRod "Right body controller: left PTC compromised rod";
CM_ SG_ 1803 VCRIGHT_rightPTCCompromisedRod "Right body controller: right PTC compromised rod";
CM_ SG_ 1803 VCRIGHT_hepaFilterHealthScore "Right body controller: hepa filter health score";
CM_ SG_ 1803 VCRIGHT_cabinFilterHealthScore "Right body controller: cabin filter health score";
CM_ SG_ 1803 VCRIGHT_cabinTempBreathLevelFOff "Right body controller: cabin temp breath level f off; raw 255 = signal not available (SNA)";
CM_ SG_ 1803 VCRIGHT_airDistributionModeAdjus "Right body controller: air distribution mode adjustment factor";
CM_ SG_ 1803 VCRIGHT_hvacLHBleedEndStop "Right body controller: hvac LH bleed end stop";
CM_ SG_ 1803 VCRIGHT_hvacRHBleedEndStop "Right body controller: hvac RH bleed end stop";
CM_ SG_ 1803 VCRIGHT_hvacLHVaneEndStop "Right body controller: hvac LH vane end stop";
CM_ SG_ 1803 VCRIGHT_hvacRHVaneEndStop "Right body controller: hvac RH vane end stop";
CM_ SG_ 1803 VCRIGHT_hvacUpperModeEndStop "Right body controller: hvac upper mode end stop";
CM_ SG_ 1803 VCRIGHT_hvacLowerModeEndStop "Right body controller: hvac lower mode end stop";
CM_ SG_ 1803 VCRIGHT_hvacIntakeEndStop "Right body controller: hvac intake end stop";
CM_ SG_ 1803 VCRIGHT_hvacLHBleedZeroStop "Right body controller: hvac LH bleed zero stop";
CM_ SG_ 1803 VCRIGHT_hvacRHBleedZeroStop "Right body controller: hvac RH bleed zero stop";
CM_ SG_ 1803 VCRIGHT_hvacLHVaneZeroStop "Right body controller: hvac LH vane zero stop";
CM_ SG_ 1803 VCRIGHT_hvacRHVaneZeroStop "Right body controller: hvac RH vane zero stop";
CM_ SG_ 1803 VCRIGHT_hvacUpperModeZeroStop "Right body controller: hvac upper mode zero stop";
CM_ SG_ 1803 VCRIGHT_hvacLowerModeZeroStop "Right body controller: hvac lower mode zero stop";
CM_ SG_ 1803 VCRIGHT_hvacIntakeZeroStop "Right body controller: hvac intake zero stop";
CM_ SG_ 1803 VCRIGHT_averageDuctTempFCooling "Estimated average duct temp temp 15 min into the drive; raw 255 = signal not available (SNA)";
CM_ SG_ 1803 VCRIGHT_fasciaTailLeftLightCurre "Current sensed by the left fascia tail light HSD (high side driver); raw 511 = signal not available (SNA)";
CM_ SG_ 1803 VCRIGHT_fasciaTailLeftLight_0001 "State representing validity of the left fascia tail light HSD (high side driver) current sense; raw 0 = signal not available (SNA)";
CM_ SG_ 1803 VCRIGHT_fasciaTailRightLightCurr "Current sensed by the right fascia tail light HSD (high side driver); raw 511 = signal not available (SNA)";
CM_ SG_ 1803 VCRIGHT_fasciaTailRightLigh_0001 "State representing validity of the right fascia tail light HSD (high side driver) current sense; raw 0 = signal not available (SNA)";
CM_ SG_ 1803 VCRIGHT_liftgateTailLeftLightCur "Current sensed by the left liftgate tail light HSD (high side driver); raw 511 = signal not available (SNA)";
CM_ SG_ 1803 VCRIGHT_liftgateTailLeftLig_0001 "State representing validity of the left liftgate tail light HSD (high side driver) current sense; raw 0 = signal not available (SNA)";
CM_ SG_ 1803 VCRIGHT_liftgateTailRightLightCu "State representing validity of the right liftgate tail light HSD (high side driver) current sense; raw 0 = signal not available (SNA)";
CM_ SG_ 1803 VCRIGHT_ambientTempLimp "Reports the estimated ambient temperature in limp mode; raw 255 = signal not available (SNA)";
CM_ SG_ 1803 VCRIGHT_cabinProbeTempLimp "Reports the estimated cabin probe temperature in limp mode; raw 255 = signal not available (SNA)";
CM_ SG_ 1803 VCRIGHT_thsTempLimp "Reports the estimated Tesla HVAC Sensor (THS) temperature in limp mode; raw 255 = signal not available (SNA)";
CM_ SG_ 1803 VCRIGHT_thsCabinWaterMassLimp "Reports the estimated Tesla HVAC Sensor (THS) humidity cabin water mass backup in limp mode.";
CM_ SG_ 1803 VCRIGHT_thsSolarIrradianceLimp "Reports the estimated Tesla HVAC Sensor (THS) solar irradiance backup in limp mode; raw 255 = signal not available (SNA)";
CM_ SG_ 1803 VCRIGHT_silentWakeRecordCount "Reports the number of records recorded during silent wake events.";
CM_ SG_ 1803 VCRIGHT_interiorCameraLedCurrent "Right body controller: interior camera led current; raw 255 = signal not available (SNA)";
CM_ SG_ 1803 VCRIGHT_evapCondensateMass "Right body controller: evap condensate mass";
CM_ SG_ 1803 VCRIGHT_airwaveRightLateralTotal "Right body controller: airwave right lateral total travel";
CM_ SG_ 1803 VCRIGHT_airwaveLeftLateralTotalT "Right body controller: airwave left lateral total travel";
CM_ SG_ 1803 VCRIGHT_hvacRearEndStop "Right body controller: hvac rear end stop";
CM_ SG_ 1803 VCRIGHT_hvacRearZeroStop "Right body controller: hvac rear zero stop";
CM_ SG_ 1803 VCRIGHT_evapLoadInFresh "Right body controller: evap load in fresh";
CM_ SG_ 1803 VCRIGHT_evapLoadInRecirc "Right body controller: evap load in recirc";
CM_ SG_ 1803 VCRIGHT_tempIncarCabinDeep "Right body controller: temp incar cabin deep; raw 255 = signal not available (SNA)";
CM_ SG_ 1803 VCRIGHT_cabinTempBreathLeve_0001 "Right body controller: cabin temp breath level f10min heating; raw 255 = signal not available (SNA)";
CM_ SG_ 1803 VCRIGHT_cabinTempBreathLevelF10m "Right body controller: cabin temp breath level f10min cooling; raw 255 = signal not available (SNA)";
CM_ SG_ 1803 VCRIGHT_cabinTempBreathLeve_0002 "Right body controller: cabin temp breath level f5min heating; raw 255 = signal not available (SNA)";
CM_ SG_ 1803 VCRIGHT_cabinTempBreathLevelF5mi "Right body controller: cabin temp breath level f5min cooling; raw 255 = signal not available (SNA)";
CM_ SG_ 1803 VCRIGHT_foggingMonitorRuntime "Total runtime of the overnight camera fogging monitor";
CM_ SG_ 1803 VCRIGHT_cabinTempInteriorFHeatin "Right body controller: cabin temp interior f heating; raw 255 = signal not available (SNA)";
CM_ SG_ 1803 VCRIGHT_cabinTempInteriorFCoolin "Right body controller: cabin temp interior f cooling; raw 255 = signal not available (SNA)";
CM_ SG_ 1803 VCRIGHT_filterLifeBlowerTorque "Right body controller: filter life blower torque; raw 1023 = signal not available (SNA)";
CM_ SG_ 1803 VCRIGHT_averageDuctTempFHeating "Estimated average duct temp temp 15 min into the drive; raw 255 = signal not available (SNA)";
CM_ SG_ 1803 VCRIGHT_thsSolarSensorType "Indicates the solar sensor type for THS";
CM_ SG_ 1803 VCRIGHT_thsTempSensorType "Indicates the temperature sensor type for THS";
CM_ BO_ 611 "Right body controller message: logging10 hz; frame length observed on a vehicle bus";
CM_ SG_ 611 VCRIGHT_logging10HzIndex "Right body controller: logging10 hz index";
CM_ SG_ 611 VCRIGHT_hvacLHBleedTarget "Right body controller: hvac LH bleed target";
CM_ SG_ 611 VCRIGHT_hvacRHBleedTarget "Right body controller: hvac RH bleed target";
CM_ SG_ 611 VCRIGHT_hvacLHVaneTarget "Right body controller: hvac LH vane target";
CM_ SG_ 611 VCRIGHT_hvacRHVaneTarget "Right body controller: hvac RH vane target";
CM_ SG_ 611 VCRIGHT_hvacUpperModeTarget "Right body controller: hvac upper mode target";
CM_ SG_ 611 VCRIGHT_hvacLowerModeTarget "Right body controller: hvac lower mode target";
CM_ SG_ 611 VCRIGHT_hvacIntakeTarget "Right body controller: hvac intake target";
CM_ SG_ 611 VCRIGHT_hvacLHBleedPosition "Right body controller: hvac LH bleed position";
CM_ SG_ 611 VCRIGHT_hvacRHBleedPosition "Right body controller: hvac RH bleed position";
CM_ SG_ 611 VCRIGHT_hvacLHVanePosition "Right body controller: hvac LH vane position";
CM_ SG_ 611 VCRIGHT_hvacRHVanePosition "Right body controller: hvac RH vane position";
CM_ SG_ 611 VCRIGHT_hvacUpperModePosition "Right body controller: hvac upper mode position";
CM_ SG_ 611 VCRIGHT_hvacLowerModePosition "Right body controller: hvac lower mode position";
CM_ SG_ 611 VCRIGHT_hvacIntakePosition "Right body controller: hvac intake position";
CM_ SG_ 611 VCRIGHT_hvacLHBleedActuatorState "Right body controller: hvac LH bleed actuator state";
CM_ SG_ 611 VCRIGHT_hvacRHBleedActuatorState "Right body controller: hvac RH bleed actuator state";
CM_ SG_ 611 VCRIGHT_hvacLHVaneActuatorState "Right body controller: hvac LH vane actuator state";
CM_ SG_ 611 VCRIGHT_hvacRHVaneActuatorState "Right body controller: hvac RH vane actuator state";
CM_ SG_ 611 VCRIGHT_hvacUpperModeActState "Right body controller: hvac upper mode act state";
CM_ SG_ 611 VCRIGHT_hvacLowerModeActState "Right body controller: hvac lower mode act state";
CM_ SG_ 611 VCRIGHT_hvacIntakeActuatorState "Right body controller: hvac intake actuator state";
CM_ SG_ 611 VCRIGHT_hvacRearActuatorState "Right body controller: hvac rear actuator state";
CM_ SG_ 611 VCRIGHT_EvapPulldownBiasActive "Indicates if an evap pulldown smell mitigation is active";
CM_ SG_ 611 VCRIGHT_tempDatLeftEst "Right body controller: temp dat left est; raw 255 = signal not available (SNA)";
CM_ SG_ 611 VCRIGHT_tempDatRightEst "Right body controller: temp dat right est; raw 255 = signal not available (SNA)";
CM_ SG_ 611 VCRIGHT_tempDuctLeftEst "Right body controller: temp duct left est; raw 255 = signal not available (SNA)";
CM_ SG_ 611 VCRIGHT_tempDuctRightEst "Right body controller: temp duct right est; raw 255 = signal not available (SNA)";
CM_ SG_ 611 VCRIGHT_ptcHeaterBadRodDetection "Right body controller: ptc heater bad rod detection state";
CM_ SG_ 611 VCRIGHT_upperModeDrvActuatorStat "Reports the HVAC actuator state";
CM_ SG_ 611 VCRIGHT_leftVerticalActuato_0001 "Right body controller: left vertical actuator status";
CM_ SG_ 611 VCRIGHT_leftLateralActuatorStatu "Right body controller: left lateral actuator status";
CM_ SG_ 611 VCRIGHT_rightVerticalActuat_0001 "Right body controller: right vertical actuator status";
CM_ SG_ 611 VCRIGHT_rightLateralActuato_0001 "Right body controller: right lateral actuator status";
CM_ SG_ 611 VCRIGHT_leftVerticalActuatorStat "Reports the HVAC actuator state";
CM_ SG_ 611 VCRIGHT_leftLateralActuatorState "Reports the HVAC actuator state";
CM_ SG_ 611 VCRIGHT_rightVerticalActuatorSta "Reports the HVAC actuator state";
CM_ SG_ 611 VCRIGHT_rightLateralActuatorStat "Reports the HVAC actuator state";
CM_ SG_ 611 VCRIGHT_windshieldRHExteriorSurf "Right body controller: windshield RH exterior surface; raw 255 = signal not available (SNA)";
CM_ SG_ 611 VCRIGHT_leftVerticalActuatorDuty "Reports the HVAC motor duty cycle";
CM_ SG_ 611 VCRIGHT_leftLateralActuatorDuty "Reports the HVAC motor duty cycle";
CM_ SG_ 611 VCRIGHT_rightVerticalActuatorDut "Reports the HVAC motor duty cycle";
CM_ SG_ 611 VCRIGHT_rightLateralActuatorDuty "Reports the HVAC motor duty cycle";
CM_ SG_ 611 VCRIGHT_frontLeftSeatTempTargetQ "Reports the front left seat heating target temperature.";
CM_ SG_ 611 VCRIGHT_frontRightSeatTempTarget "Reports the front right seat heating target temperature.";
CM_ SG_ 611 VCRIGHT_hvacRearPosition "Right body controller: hvac rear position";
CM_ SG_ 611 VCRIGHT_hvacRearTarget "Right body controller: hvac rear target";
CM_ BO_ 691 "Right body controller message: logging1 hz; frame length observed on a vehicle bus";
CM_ SG_ 691 VCRIGHT_logging1HzIndex "Right body controller: logging1 hz index";
CM_ SG_ 691 VCRIGHT_glareShieldHeaterState "State of the glare shield heater";
CM_ SG_ 691 VCRIGHT_tempIncarCabinProbe "Right body controller: temp incar cabin probe; raw 255 = signal not available (SNA)";
CM_ SG_ 691 VCRIGHT_cabinTempInteriorL2 "Right body controller: cabin temp interior L2; raw 255 = signal not available (SNA)";
CM_ SG_ 691 VCRIGHT_cabinTempInteriorSunnyL2 "Right body controller: cabin temp interior sunny L2; raw 255 = signal not available (SNA)";
CM_ SG_ 691 VCRIGHT_tempIncarCabinMid "Right body controller: temp incar cabin mid; raw 250 = signal not available (SNA)";
CM_ SG_ 691 VCRIGHT_cabinTempInteriorL3 "Right body controller: cabin temp interior L3; raw 255 = signal not available (SNA)";
CM_ SG_ 691 VCRIGHT_cabinTempInteriorSunnyL3 "Right body controller: cabin temp interior sunny L3; raw 255 = signal not available (SNA)";
CM_ SG_ 691 VCRIGHT_tempWetBulb "Estimate the rain temp; raw 255 = signal not available (SNA)";
CM_ SG_ 691 VCRIGHT_isRainingOrSnowing "Right body controller: is raining or snowing";
CM_ SG_ 691 VCRIGHT_cabinTempGlassRoof "Modeled cabin temperature near the glass roof; raw 255 = signal not available (SNA)";
CM_ SG_ 691 VCRIGHT_cabinTempWindshield "Windshield temperature estimate; raw 255 = signal not available (SNA)";
CM_ SG_ 691 VCRIGHT_cabinTempInterior "Modeled interior cabin temperature; raw 255 = signal not available (SNA)";
CM_ SG_ 691 VCRIGHT_cabinTempInteriorSunny "Modeled interior surface temperature exposed to direct sunlight; raw 255 = signal not available (SNA)";
CM_ SG_ 691 VCRIGHT_cabinTempSideGlassLeft "Modeled glass temperature left; raw 255 = signal not available (SNA)";
CM_ SG_ 691 VCRIGHT_cabinTempSideGlassRight "Modeled glass temperature right; raw 255 = signal not available (SNA)";
CM_ SG_ 691 VCRIGHT_cabinTempBreathLevel "Modeled cabin temperature near occupant breathing level; raw 255 = signal not available (SNA)";
CM_ SG_ 691 VCRIGHT_pcbaTemperature "Right body controller: pcba temperature";
CM_ SG_ 691 VCRIGHT_wattsHeaterLeftTotal "Right body controller: watts heater left total";
CM_ SG_ 691 VCRIGHT_wattsHeaterRightTotal "Right body controller: watts heater right total";
CM_ SG_ 691 VCRIGHT_qdotLeftFFUnsat "Right body controller: qdot left FF unsat";
CM_ SG_ 691 VCRIGHT_qdotRightFFUnsat "Right body controller: qdot right FF unsat";
CM_ SG_ 691 VCRIGHT_nvhLevelDb "Right body controller: nvh level db";
CM_ SG_ 691 VCRIGHT_hvacSetTempActualLeft "HVAC internal left temperature set point";
CM_ SG_ 691 VCRIGHT_hvacSetTempActualRight "HVAC internal right temperature set point";
CM_ SG_ 691 VCRIGHT_hvacAutoTransitionReason "Reason for airflow mode change when system is operating in auto";
CM_ SG_ 691 VCRIGHT_hvacMassflowTarget "Right body controller: hvac massflow target";
CM_ SG_ 691 VCRIGHT_hvacQdotLimitedLeft "Right body controller: hvac qdot limited left";
CM_ SG_ 691 VCRIGHT_hvacQdotLimitedRight "Right body controller: hvac qdot limited right";
CM_ SG_ 691 VCRIGHT_LHPanelAirflowBlocked "Right body controller: LH panel airflow blocked";
CM_ SG_ 691 VCRIGHT_RHPanelAirflowBlocked "Right body controller: RH panel airflow blocked";
CM_ SG_ 691 VCRIGHT_floorAirflowBlocked "Right body controller: floor airflow blocked";
CM_ SG_ 691 VCRIGHT_defrostAirflowBlocked "Right body controller: defrost airflow blocked";
CM_ SG_ 691 VCRIGHT_hvacFilterLifeDetectActi "Indicates when filter life detection is active";
CM_ SG_ 691 VCRIGHT_hvacLHBleedOperationMode "Right body controller: hvac LH bleed operation mode";
CM_ SG_ 691 VCRIGHT_hvacRHBleedOperationMode "Right body controller: hvac RH bleed operation mode";
CM_ SG_ 691 VCRIGHT_hvacLHVaneOperationMode "Right body controller: hvac LH vane operation mode";
CM_ SG_ 691 VCRIGHT_hvacRHVaneOperationMode "Right body controller: hvac RH vane operation mode";
CM_ SG_ 691 VCRIGHT_hvacUpperModeOpMode "Right body controller: hvac upper mode op mode";
CM_ SG_ 691 VCRIGHT_hvacLowerModeOpMode "Right body controller: hvac lower mode op mode";
CM_ SG_ 691 VCRIGHT_hvacIntakeOperationMode "Right body controller: hvac intake operation mode";
CM_ SG_ 691 VCRIGHT_hvacRearOperationMode "Right body controller: hvac rear operation mode";
CM_ SG_ 691 VCRIGHT_isProbeFeedbackApplied "Right body controller: is probe feedback applied";
CM_ SG_ 691 VCRIGHT_feedbackPullDownScalar "Right body controller: feedback pull down scalar";
CM_ SG_ 691 VCRIGHT_feedForwardPullDownScala "Right body controller: feed forward pull down scalar";
CM_ SG_ 691 VCRIGHT_convectionTargetLeft "Right body controller: convection target left; raw 511 = signal not available (SNA)";
CM_ SG_ 691 VCRIGHT_convectionTargetRight "Right body controller: convection target right; raw 511 = signal not available (SNA)";
CM_ SG_ 691 VCRIGHT_convectionDeliveredLeft "Right body controller: convection delivered left; raw 511 = signal not available (SNA)";
CM_ SG_ 691 VCRIGHT_convectionDeliveredRight "Right body controller: convection delivered right; raw 511 = signal not available (SNA)";
CM_ SG_ 691 VCRIGHT_solarLoadRightOccupant "Right body controller: solar load right occupant; raw 127 = signal not available (SNA)";
CM_ SG_ 691 VCRIGHT_solarLoadLeftOccupant "Right body controller: solar load left occupant; raw 127 = signal not available (SNA)";
CM_ SG_ 691 VCRIGHT_ptcShutOutletMitigationA "Right body controller: ptc shut outlet mitigation active";
CM_ SG_ 691 VCRIGHT_solarLoadFromThsTemp "Right body controller: solar load from ths temp; raw 255 = signal not available (SNA)";
CM_ SG_ 691 VCRIGHT_hvacFoggingRiskLeve_0003 "Fogging risk feedforward with conservative estimate";
CM_ SG_ 691 VCRIGHT_hvacFoggingRiskLeve_0004 "Fogging risk feedforward with conservative target";
CM_ SG_ 691 VCRIGHT_hvacFoggingRiskLeve_0001 "Fogging risk with conservative target";
CM_ SG_ 691 VCRIGHT_ptcHeaterTempDuctHigh "Right body controller: ptc heater temp duct high";
CM_ SG_ 691 VCRIGHT_ptcHeaterTempDuctFault "Right body controller: ptc heater temp duct fault";
CM_ SG_ 691 VCRIGHT_ptcHeaterNoAirflow "Right body controller: ptc heater no airflow";
CM_ SG_ 691 VCRIGHT_ptcHeaterHvacActNotReady "Right body controller: ptc heater hvac act not ready";
CM_ SG_ 691 VCRIGHT_ptcHeaterNoUiRequest "Right body controller: ptc heater no ui request";
CM_ SG_ 691 VCRIGHT_ptcHeaterNoHighVoltage "Right body controller: ptc heater no high voltage";
CM_ SG_ 691 VCRIGHT_ptcHeaterLAirPathBlocked "Right body controller: ptc heater l air path blocked";
CM_ SG_ 691 VCRIGHT_ptcHeaterRAirPathBlocked "Right body controller: ptc heater r air path blocked";
CM_ SG_ 691 VCRIGHT_ptcHeaterReqAirpathBlock "Right body controller: ptc heater req airpath blocked";
CM_ SG_ 691 VCRIGHT_hvacQdotFeedforward "Right body controller: hvac qdot feedforward";
CM_ SG_ 691 VCRIGHT_cabinTempWshldDefog "Windshield temperature estimate used for defogging; raw 255 = signal not available (SNA)";
CM_ SG_ 691 VCRIGHT_cabinTempWshldDefogTop "Right body controller: cabin temp wshld defog top; raw 255 = signal not available (SNA)";
CM_ SG_ 691 VCRIGHT_hvacLHBleedVoltage "Right body controller: hvac LH bleed voltage";
CM_ SG_ 691 VCRIGHT_hvacRHBleedVoltage "Right body controller: hvac RH bleed voltage";
CM_ SG_ 691 VCRIGHT_hvacLHVaneVoltage "Right body controller: hvac LH vane voltage";
CM_ SG_ 691 VCRIGHT_hvacRHVaneVoltage "Right body controller: hvac RH vane voltage";
CM_ SG_ 691 VCRIGHT_hvacUpperModeVoltage "Right body controller: hvac upper mode voltage";
CM_ SG_ 691 VCRIGHT_hvacLowerModeVoltage "Right body controller: hvac lower mode voltage";
CM_ SG_ 691 VCRIGHT_hvacIntakeVoltage "Right body controller: hvac intake voltage";
CM_ SG_ 691 VCRIGHT_cabinTempBreathLevelFHea "Right body controller: cabin temp breath level f heating; raw 255 = signal not available (SNA)";
CM_ SG_ 691 VCRIGHT_cabinTempBreathLevelFCoo "Right body controller: cabin temp breath level f cooling; raw 255 = signal not available (SNA)";
CM_ SG_ 691 VCRIGHT_hvacTorqueMassflowLinear "Right body controller: hvac torque massflow linear fit";
CM_ SG_ 691 VCRIGHT_hvacTorqueMassflowEstima "Right body controller: hvac torque massflow estimate status";
CM_ SG_ 691 VCRIGHT_hvacFoggingRiskLevelCons "Fogging risk with conservative estimate";
CM_ SG_ 691 VCRIGHT_hvacWindshieldRHConserva "Windshield RH conservative estimate";
CM_ SG_ 691 VCRIGHT_hvacFoggingRiskLevelFeed "Fogging risk feedback";
CM_ SG_ 691 VCRIGHT_hvacFoggingRiskLevelInte "Fogging risk feedback integral";
CM_ SG_ 691 VCRIGHT_hvacFoggingRiskLeve_0002 "Fogging risk feedforward";
CM_ SG_ 691 VCRIGHT_hvacCabOvrheatProtActive "Status of cabin overheat protection";
CM_ SG_ 691 VCRIGHT_hvacCabinPurgeAllowed "Right body controller: hvac cabin purge allowed";
CM_ SG_ 691 VCRIGHT_hvacCabOvrheatProtAllowe "Cabin overheat protection is allowed to run";
CM_ SG_ 691 VCRIGHT_AP_humidityModelBasedCab "Right body controller: AP humidity model based cabin water mass; raw 1023 = signal not available (SNA)";
CM_ SG_ 691 VCRIGHT_cabinTempFanCurrent "Right body controller: cabin temp fan current";
CM_ SG_ 691 VCRIGHT_cabinTempFanOutput "Right body controller: cabin temp fan output";
CM_ SG_ 691 VCRIGHT_cloudinessEstimatedPct "Right body controller: cloudiness estimated pct";
CM_ SG_ 691 VCRIGHT_solarLoadOnVehFiltered "Right body controller: solar load on veh filtered; raw 255 = signal not available (SNA)";
CM_ SG_ 691 VCRIGHT_cabinTempProbeEstimate "Right body controller: cabin temp probe estimate; raw 255 = signal not available (SNA)";
CM_ SG_ 691 VCRIGHT_cabinTempThs "Estimated temperature from Tesla HVAC Sensor; raw 255 = signal not available (SNA)";
CM_ SG_ 691 VCRIGHT_cabinTempThsBracket "Right body controller: cabin temp ths bracket; raw 255 = signal not available (SNA)";
CM_ SG_ 691 VCRIGHT_leftHeatOvertempProtect "Right body controller: left heat overtemp protect";
CM_ SG_ 691 VCRIGHT_rightHeatOvertempProtect "Right body controller: right heat overtemp protect";
CM_ SG_ 691 VCRIGHT_CO2ppm "Right body controller: co2ppm; raw 1023 = signal not available (SNA)";
CM_ SG_ 691 VCRIGHT_timeLeftToCabinModelInit "Right body controller: time left to cabin model init";
CM_ SG_ 691 VCRIGHT_hvacEstimateWindshieldRH "Estimated windshield relative humidity";
CM_ SG_ 691 VCRIGHT_hvacFoggingRiskLevel "Control signal of the windshield fogging risk controller";
CM_ SG_ 691 VCRIGHT_hvacCabinHumidityLevel "Control signal of the cabin humidity controller";
CM_ SG_ 691 VCRIGHT_hvacFlashFoggingDetected "Windshield flash fogging risk detected";
CM_ SG_ 691 VCRIGHT_solarSensitivityInfr "Right body controller: solar sensitivity infr";
CM_ SG_ 691 VCRIGHT_solarSensitivityInfrCorr "Right body controller: solar sensitivity infr corr";
CM_ SG_ 691 VCRIGHT_lumbarCurrent "Electrical current of the lumbar ECU";
CM_ SG_ 691 VCRIGHT_ocsCurrent "Electrical current of the OCS ECU";
CM_ SG_ 691 VCRIGHT_rcmCurrent "Electrical current of the RCM ECU";
CM_ SG_ 691 VCRIGHT_radioTunerCurrent "Electrical current of the Radio Tuner";
CM_ SG_ 691 VCRIGHT_rearOilPumpCurrent "Right body controller: rear oil pump current";
CM_ SG_ 691 VCRIGHT_rearDefrostCurrent "Right body controller: rear defrost current";
CM_ SG_ 691 VCRIGHT_tailLightCurrent "Electrical current of the tail and license plate lights";
CM_ SG_ 691 VCRIGHT_turnTailStopLightCurrent "Reports the electrical current of the right rear turn indicator, right rear tail light, or right rear brake light";
CM_ SG_ 691 VCRIGHT_reverseFogLightsCurrent "Electrical current of the trunk fog light; raw 15 = signal not available (SNA)";
CM_ SG_ 691 VCRIGHT_stopReverseTurnLightCurr "Reports the electrical current of the right rear brake light, right rear reverse light, or right rear turn indicator";
CM_ SG_ 691 VCRIGHT_sideMirrorCurrent "Electrical current of side mirror tilt and fold";
CM_ SG_ 691 VCRIGHT_sideMirrorHeaterCurrent "Electrical current of the mirror heater; raw 31 = signal not available (SNA)";
CM_ SG_ 691 VCRIGHT_frontSeatHeatCushionPwr "Right body controller: front seat heat cushion pwr";
CM_ SG_ 691 VCRIGHT_trunkInteriorLEDCurrent "Electrical current of the trunk interior light; raw 15 = signal not available (SNA)";
CM_ SG_ 691 VCRIGHT_mapPocketLEDsCurrent "Electrical current of the map pocket lights; raw 15 = signal not available (SNA)";
CM_ SG_ 691 VCRIGHT_miscEFuseCurrent "Right body controller: misc e fuse current; raw 31 = signal not available (SNA)";
CM_ SG_ 691 VCRIGHT_interiorHandleLEDCurrent "Electrical current of the interior handle LED";
CM_ SG_ 691 VCRIGHT_miscInteriorLightsCurren "Electrical current of the misc interior lights; raw 7 = signal not available (SNA)";
CM_ SG_ 691 VCRIGHT_frontPuddleLEDCurrent "Electrical current of the front puddle LED; raw 7 = signal not available (SNA)";
CM_ SG_ 691 VCRIGHT_rearPuddleLEDCurrent "Electrical current of the rear puddle LED; raw 7 = signal not available (SNA)";
CM_ SG_ 691 VCRIGHT_liftgateShutfaceLEDCurre "Electrical current of the liftgate shutface LED; raw 7 = signal not available (SNA)";
CM_ SG_ 691 VCRIGHT_3rSeatTOSCurrent "Electrical current of the 3R TOS; raw 15 = signal not available (SNA)";
CM_ SG_ 691 VCRIGHT_vbatFusedCurrent "Right body controller: vbat fused current; raw 15 = signal not available (SNA)";
CM_ SG_ 691 VCRIGHT_cabinTempGlassGridHeater "Right body controller: cabin temp glass grid heater; raw 255 = signal not available (SNA)";
CM_ SG_ 691 VCRIGHT_hvacAirflowReasonRight "Right body controller: hvac airflow reason right";
CM_ SG_ 691 VCRIGHT_hvacAirflowReasonLeft "Right body controller: hvac airflow reason left";
CM_ SG_ 691 VCRIGHT_hvacMassflowTargetLeft "Right body controller: hvac massflow target left";
CM_ SG_ 691 VCRIGHT_hvacMassflowTargetRight "Right body controller: hvac massflow target right";
CM_ SG_ 691 VCRIGHT_solarLoadLeftOccupantFil "Right body controller: solar load left occupant filt; raw 127 = signal not available (SNA)";
CM_ SG_ 691 VCRIGHT_solarLoadRightOccupantFi "Right body controller: solar load right occupant filt; raw 127 = signal not available (SNA)";
CM_ SG_ 691 VCRIGHT_windshieldRHCapped "Estimated windshield relative humidity";
CM_ SG_ 691 VCRIGHT_feedbackWarmUpScalar "Right body controller: feedback warm up scalar";
CM_ SG_ 691 VCRIGHT_maxMassflowScalarWarmUp "Right body controller: max massflow scalar warm up";
CM_ SG_ 691 VCRIGHT_feedforwardWarmUpScalar "Right body controller: feedforward warm up scalar";
CM_ SG_ 691 VCRIGHT_frontSeatHeatBackrestPwr "Right body controller: front seat heat backrest pwr";
CM_ SG_ 691 VCRIGHT_maxMassflowScalar "Right body controller: max massflow scalar";
CM_ SG_ 691 VCRIGHT_massflowTargetAutoInManu "Right body controller: massflow target auto in manual mode";
CM_ SG_ 691 VCRIGHT_airflowReasonAutoInManua "Right body controller: airflow reason auto in manual mode";
CM_ SG_ 691 VCRIGHT_airflowReasonAutoIn_0001 "Right body controller: airflow reason auto in manual mode left";
CM_ SG_ 691 VCRIGHT_airflowReasonAutoIn_0002 "Right body controller: airflow reason auto in manual mode right";
CM_ SG_ 691 VCRIGHT_hvacTorqueMassflowQuadra "Right body controller: hvac torque massflow quadratic fit";
CM_ SG_ 691 VCRIGHT_vocSweatMassSeat "Right body controller: voc sweat mass seat; raw 255 = signal not available (SNA)";
CM_ SG_ 691 VCRIGHT_vocSweatConcentrationAir "Right body controller: voc sweat concentration air; raw 255 = signal not available (SNA)";
CM_ SG_ 691 VCRIGHT_hvacBiLevelWhsldRhEst "Right body controller: hvac bi level whsld rh est";
CM_ SG_ 691 VCRIGHT_steeringWheelSurfaceTemp "Right body controller: steering wheel surface temp est; raw 1023 = signal not available (SNA)";
CM_ SG_ 691 VCRIGHT_steeringWheelSurfac_0001 "Right body controller: steering wheel surface temp tgt; raw 1023 = signal not available (SNA)";
CM_ SG_ 691 VCRIGHT_timeToComfortHeating "Right body controller: time to comfort heating";
CM_ SG_ 691 VCRIGHT_timeToComfortCooling "Right body controller: time to comfort cooling";
CM_ SG_ 691 VCRIGHT_cabinWaterMassRaw "Right body controller: cabin water mass raw; raw 255 = signal not available (SNA)";
CM_ SG_ 691 VCRIGHT_massflowSingleZoneSplit "Right body controller: massflow single zone split";
CM_ SG_ 691 VCRIGHT_VOCPurgeState "Right body controller: VOC purge state";
CM_ SG_ 691 VCRIGHT_cameraFoggingMonitorStat "Right body controller: camera fogging monitor state";
CM_ SG_ 691 VCRIGHT_windWeatherSource "Right body controller: wind weather source";
CM_ SG_ 691 VCRIGHT_humidityRatioWeatherSour "Right body controller: humidity ratio weather source";
CM_ SG_ 691 VCRIGHT_cabinOverheatProtectNotR "Reports all reasons cabin overheat protection is not running.";
CM_ SG_ 691 VCRIGHT_hvacIntakeReason "Reason for current intake door position";
CM_ SG_ 691 VCRIGHT_hvacCabinPurgeActive "Indicates if cabin purge is active";
CM_ SG_ 691 VCRIGHT_solarAzimuthCarRef "Right body controller: solar azimuth car ref; raw 1025 = signal not available (SNA)";
CM_ SG_ 691 VCRIGHT_massflowPulldownBias "Right body controller: massflow pulldown bias";
CM_ SG_ 691 VCRIGHT_evapPulldownBias "Right body controller: evap pulldown bias";
CM_ SG_ 691 VCRIGHT_modeledMassflowFresh "Right body controller: modeled massflow fresh";
CM_ SG_ 691 VCRIGHT_modeledMassflowRecirc "Right body controller: modeled massflow recirc";
CM_ SG_ 691 VCRIGHT_hvacLimpModeStatus "Reports the cabin model limp mode status.";
CM_ SG_ 691 VCRIGHT_hvacEstimatedCameraWinds "Right body controller: hvac estimated camera windshield RH; raw 255 = signal not available (SNA)";
CM_ SG_ 691 VCRIGHT_hvacRearVoltage "Right body controller: hvac rear voltage";
CM_ SG_ 691 VCRIGHT_cabinTempRoofL2 "Right body controller: cabin temp roof L2; raw 255 = signal not available (SNA)";
CM_ SG_ 691 VCRIGHT_cabinTempRoofL3 "Right body controller: cabin temp roof L3; raw 255 = signal not available (SNA)";
CM_ SG_ 691 VCRIGHT_odorRoutineState "Right body controller: odor routine state; raw 7 = signal not available (SNA)";
CM_ SG_ 691 VCRIGHT_rgbLedFrontCurrent "Current drawn by the front door RGB LED";
CM_ SG_ 691 VCRIGHT_rgbLedRearCurrent "Current drawn by the rear door RGB LED";
CM_ SG_ 691 VCRIGHT_rgbLedFrontOutput "The power state of the front door RGB LED";
CM_ SG_ 691 VCRIGHT_rgbLedRearOutput "The power state of the rear door RGB LED";
CM_ SG_ 691 VCRIGHT_cameraDefogState "State of the camera defog feature";
CM_ BO_ 1859 "Right body controller message: recall status; frame length observed on a vehicle bus";
CM_ SG_ 1859 VCRIGHT_systemRecallStatus "Recall state of superset of body controls ECUs; raw 0 = signal not available (SNA)";
CM_ SG_ 1859 VCRIGHT_seatRecallStatus "Right body controller: seat recall status; raw 0 = signal not available (SNA)";
CM_ SG_ 1859 VCRIGHT_mirrorRecallStatus "Recall status for the right side view mirror; raw 0 = signal not available (SNA)";
CM_ BO_ 794 "Right body controller message: restraint status; frame length from the layout, not yet observed on a vehicle bus";
CM_ SG_ 794 VCRIGHT_frontOccupancyStatus "Right body controller: front occupancy status; raw 7 = signal not available (SNA)";
CM_ SG_ 794 VCRIGHT_frontBuckleStatus "Status of front right seatbelt buckle";
CM_ SG_ 794 VCRIGHT_rearCenterBuckleStatus "Right body controller: rear center buckle status";
CM_ SG_ 794 VCRIGHT_rearRightBuckleStatus "Right body controller: rear right buckle status";
CM_ SG_ 794 VCRIGHT_rearRightOccupancyStatus "Right body controller: rear right occupancy status";
CM_ SG_ 794 VCRIGHT_3RowLeftBuckleStatus "Status of third row left seatbelt buckle";
CM_ SG_ 794 VCRIGHT_3RowRightBuckleStatus "Right body controller: 3 row right buckle status";
CM_ SG_ 794 VCRIGHT_3RowLeftOccupancyStatus "Right body controller: 3 row left occupancy status";
CM_ SG_ 794 VCRIGHT_3RowRightOccupancyStatus "Right body controller: 3 row right occupancy status";
CM_ SG_ 794 VCRIGHT_seatTrackPosition "Right body controller: seat track position; raw 7 = signal not available (SNA)";
CM_ SG_ 794 VCRIGHT_occupantClassification "Right body controller: occupant classification; raw 7 = signal not available (SNA)";
CM_ SG_ 794 VCRIGHT_occupantClassificationQF "Right body controller: occupant classification QF";
CM_ SG_ 794 VCRIGHT_classificationEnabled "Indicates whether the RCM should consume VCRIGHT occupant classification rather than another source such as OCS1P";
CM_ SG_ 794 VCRIGHT_classificationEnabledQF "Indicates whether the VCRIGHT_classificationEnabled signal is valid";
CM_ SG_ 794 VCRIGHT_3RowRightABStatus "Reports status of third row right airbag suppression; raw 2 = signal not available (SNA)";
CM_ SG_ 794 VCRIGHT_restraintStatusCounter "Right body controller: restraint status counter";
CM_ SG_ 794 VCRIGHT_restraintStatusChecksum "Right body controller: restraint status checksum";
CM_ BO_ 1251 "Right body controller message: seat status; frame length observed on a vehicle bus";
CM_ SG_ 1251 VCRIGHT_seatStatusIndex "Right body controller: seat status index";
CM_ SG_ 1251 VC_AH_1RowRightSeatMovementHealt "Right body controller: AH 1 row right seat movement health";
CM_ SG_ 1251 VCRIGHT_frontSeatTrackPos "Motor encoder value representing front left seat track position";
CM_ SG_ 1251 VCRIGHT_frontSeatTrackCurrent "Current drawn by front left seat track motor";
CM_ SG_ 1251 VCRIGHT_frontSeatTrackDuty "Front left seat track motor duty cycle";
CM_ SG_ 1251 VCRIGHT_frontSeatTrackState "State of front right seat track motor";
CM_ SG_ 1251 VCRIGHT_frontSeatTrackCalibrated "Right body controller: front seat track calibrated";
CM_ SG_ 1251 VCRIGHT_frontSeatTrackLog "Right body controller: front seat track log";
CM_ SG_ 1251 VCRIGHT_frontSeatTrackBridgeSt "Bridge state";
CM_ SG_ 1251 VCRIGHT_frontSeatTrackPercentage "Communicates position of front seat track as percentage of its total range";
CM_ SG_ 1251 VCRIGHT_frontSeatBackPos "Motor encoder value representing front right seat backrest position";
CM_ SG_ 1251 VCRIGHT_frontSeatBackCurrent "Current drawn by front right seat backrest motor";
CM_ SG_ 1251 VCRIGHT_frontSeatBackDuty "Front right seat backrest motor duty cycle";
CM_ SG_ 1251 VCRIGHT_frontSeatBackState "Active state of front right seat backrest";
CM_ SG_ 1251 VCRIGHT_frontSeatBackCalibrated "Right body controller: front seat back calibrated";
CM_ SG_ 1251 VCRIGHT_frontSeatBackLog "Right body controller: front seat back log";
CM_ SG_ 1251 VCRIGHT_frontSeatBackBridgeSt "Bridge state";
CM_ SG_ 1251 VCRIGHT_frontSeatBackPercentage "Communicates position of front seat backrest recline as percentage of its total range";
CM_ SG_ 1251 VCRIGHT_frontSeatLiftPos "Motor encoder value representing front left seat lift position";
CM_ SG_ 1251 VCRIGHT_frontSeatLiftCurrent "Current drawn by front left seat lift motor";
CM_ SG_ 1251 VCRIGHT_frontSeatLiftDuty "Front left seat lift motor duty cycle";
CM_ SG_ 1251 VCRIGHT_frontSeatLiftState "Status of front left seat motor";
CM_ SG_ 1251 VCRIGHT_frontSeatLiftCalibrated "Right body controller: front seat lift calibrated";
CM_ SG_ 1251 VCRIGHT_frontSeatLiftLog "Right body controller: front seat lift log";
CM_ SG_ 1251 VCRIGHT_frontSeatLiftBridgeSt "Bridge state";
CM_ SG_ 1251 VCRIGHT_frontSeatLiftPercentage "Communicates position of front seat lift as percentage of its total range";
CM_ SG_ 1251 VCRIGHT_frontSeatTiltPos "Motor encoder value representing front left seat tilt position";
CM_ SG_ 1251 VCRIGHT_frontSeatTiltCurrent "Current drawn by front left seat tilt motor";
CM_ SG_ 1251 VCRIGHT_frontSeatTiltDuty "Front left seat tilt motor duty cycle";
CM_ SG_ 1251 VCRIGHT_frontSeatTiltState "State of front right seat tilt motor";
CM_ SG_ 1251 VCRIGHT_frontSeatTiltCalibrated "Right body controller: front seat tilt calibrated";
CM_ SG_ 1251 VCRIGHT_frontSeatTiltLog "Right body controller: front seat tilt log";
CM_ SG_ 1251 VCRIGHT_frontSeatTiltBridgeSt "Bridge state";
CM_ SG_ 1251 VCRIGHT_frontSeatTiltPercentage "Communicates position of front seat tilt as percentage of its total range";
CM_ SG_ 1251 VCRIGHT_lumbarAState "State of front right seat lumbar bladder A";
CM_ SG_ 1251 VCRIGHT_lumbarBState "State of front right lumbar bladder B";
CM_ SG_ 1251 VCRIGHT_lumbarAPressureHpa "Right body controller: lumbar a pressure hpa";
CM_ SG_ 1251 VCRIGHT_lumbarAPressureHpaFilt "logs filtered pressure of right seat lumbar bladder A";
CM_ SG_ 1251 VCRIGHT_lumbarBPressureHpa "Right body controller: lumbar b pressure hpa";
CM_ SG_ 1251 VCRIGHT_lumbarBPressureHpaFilt "logs filtered pressure of right seat lumbar bladder B";
CM_ SG_ 1251 VCRIGHT_lumbarActiveTooLongErr "Error reported by lumbar ECU: Valve activated too long";
CM_ SG_ 1251 VCRIGHT_lumbarMaxPErr "Error reported by lumbar ECU: max bladder pressure reached";
CM_ SG_ 1251 VCRIGHT_lumbarOvercurrentErr "Error reported by lumbar ECU: pump overcurrent";
CM_ SG_ 1251 VCRIGHT_lumbarMaxOperatingPErr "Error reported by lumbar ECU: max bladder operating pressure reached";
CM_ SG_ 1251 VCRIGHT_lumbarMinPErr "Error reported by lumbar ECU: min bladder pressure reached";
CM_ SG_ 1251 VCRIGHT_lumbarGeneralErr "Error reported by lumbar ECU: general error";
CM_ SG_ 1251 VCRIGHT_lumbarDevMaxPumpPressA "System has reached Tesla specified maximum pressure for lumbar bladder A";
CM_ SG_ 1251 VCRIGHT_lumbarDevMaxPumpPressB "System has reached Tesla specified maximum pressure for lumbar bladder B";
CM_ SG_ 1251 VCRIGHT_frontSeatTrackPosReal "Front right seat track position in millimeters";
CM_ SG_ 1251 VCRIGHT_frontSeatBackPosReal "Front right seat backrest position in degrees";
CM_ SG_ 1251 VCRIGHT_frontSeatLiftPosReal "Front right seat lift position in millimeters";
CM_ SG_ 1251 VCRIGHT_frontSeatTiltPosReal "Front right seat tilt position in degrees";
CM_ SG_ 1251 VCRIGHT_frontSeatThighSuppo_0001 "Position of front seat thigh support in a physical unit";
CM_ SG_ 1251 VCRIGHT_frontSeatTrackPosOffset "Communicates post calibration position offset of front right seat track in a physical unit";
CM_ SG_ 1251 VCRIGHT_frontSeatBackPosOffset "Communicates post calibration position offset of front right seat backrest in a physical unit";
CM_ SG_ 1251 VCRIGHT_frontSeatLiftPosOffset "Communicates post calibration position offset of front right seat lift in a physical unit";
CM_ SG_ 1251 VCRIGHT_frontSeatTiltPosOffset "Communicates post calibration position offset of front right seat tilt in a physical unit";
CM_ SG_ 1251 VCRIGHT_frontSeatThighSupportPos "Post calibration position offset of front seat thigh support in a physical unit";
CM_ SG_ 1251 VCRIGHT_lumbarAPressurePercentag "Percentage of lumbar bladder A pressure relative to maximum pressure";
CM_ SG_ 1251 VCRIGHT_lumbarBPressurePercentag "Percentage of lumbar bladder B pressure relative to maximum pressure";
CM_ BO_ 739 "Right body controller message: seat status2; frame length observed on a vehicle bus";
CM_ SG_ 739 VCRIGHT_seatStatus2Index "Right body controller: seat status2 index";
CM_ SG_ 739 VCRIGHT_frontSeatHeatCurrent "Right body controller: front seat heat current; raw 12 = signal not available (SNA)";
CM_ SG_ 739 VCRIGHT_frontSeatHeatDuty "Right body controller: front seat heat duty";
CM_ SG_ 739 VCRIGHT_frontSeatHeatTmp "Right body controller: front seat heat tmp";
CM_ SG_ 739 VCRIGHT_frontSeatHeatTmpTarget "Target temperature for front right seat heater";
CM_ SG_ 739 VCRIGHT_frontSeatHeatInhibited "Front right seat heater duty cycle";
CM_ SG_ 739 VCRIGHT_frontSeatHeatPowered "Right body controller: front seat heat powered";
CM_ SG_ 739 VC_AH_1RowRightSeatHeatVentHealt "Right body controller: AH 1 row right seat heat vent health";
CM_ SG_ 739 VCRIGHT_rearLSeatHeatCurrent "Current drawn by rear center seat heater";
CM_ SG_ 739 VCRIGHT_rearLSeatHeatDuty "Right body controller: rear l seat heat duty";
CM_ SG_ 739 VCRIGHT_rearLSeatHeatTmp "Right body controller: rear l seat heat tmp";
CM_ SG_ 739 VCRIGHT_rearLSeatHeatTmpTarget "Right body controller: rear l seat heat tmp target";
CM_ SG_ 739 VCRIGHT_rearLSeatHeatInhibited "Right body controller: rear l seat heat inhibited";
CM_ SG_ 739 VCRIGHT_rearLSeatHeatPowered "Right body controller: rear l seat heat powered";
CM_ SG_ 739 VCRIGHT_rearCSeatHeatCurrent "Right body controller: rear c seat heat current";
CM_ SG_ 739 VCRIGHT_rearCSeatHeatDuty "Right body controller: rear c seat heat duty";
CM_ SG_ 739 VCRIGHT_rearCSeatHeatTmp "Right body controller: rear c seat heat tmp";
CM_ SG_ 739 VCRIGHT_rearCSeatHeatTmpTarget "Right body controller: rear c seat heat tmp target";
CM_ SG_ 739 VCRIGHT_rearCSeatHeatInhibited "Right body controller: rear c seat heat inhibited";
CM_ SG_ 739 VCRIGHT_rearCSeatHeatPowered "Right body controller: rear c seat heat powered";
CM_ SG_ 739 VCRIGHT_rearRSeatHeatCurrent "Right body controller: rear r seat heat current";
CM_ SG_ 739 VCRIGHT_rearRSeatHeatDuty "Right body controller: rear r seat heat duty";
CM_ SG_ 739 VCRIGHT_rearRSeatHeatTmp "Right body controller: rear r seat heat tmp";
CM_ SG_ 739 VCRIGHT_rearRSeatHeatTmpTarget "Right body controller: rear r seat heat tmp target";
CM_ SG_ 739 VCRIGHT_rearRSeatHeatInhibited "Right body controller: rear r seat heat inhibited";
CM_ SG_ 739 VCRIGHT_rearRSeatHeatPowered "Right body controller: rear r seat heat powered";
CM_ SG_ 739 VCRIGHT_2RowSeatReclineState "Reports the active state of the 2nd row seat recliner; raw 15 = signal not available (SNA)";
CM_ SG_ 739 VCRIGHT_2RowSeatReclineDuty "Reports the 2nd row seat recliner motor duty cycle";
CM_ SG_ 739 VCRIGHT_2RowSeatReclineCurrent "Reports the 2nd row seat recliner motor current";
CM_ SG_ 739 VCRIGHT_2RowSeatReclineCalibrate "Reports calibration status of the 2nd row seat recliner";
CM_ SG_ 739 VCRIGHT_2RowSeatReclinePositionR "Reports the 2nd row seat recliner raw encoder count";
CM_ SG_ 739 VCRIGHT_2RowSeatReclineAngle "Reports the position of the 2nd row seat recliner in degrees";
CM_ SG_ 739 VCRIGHT_2RowSeatReclineAbsPosSwi "Reports the status of 2nd row seat recline absolute position (comfort zone) switch; raw 0 = signal not available (SNA)";
CM_ SG_ 739 VCRIGHT_2RowSeatReclinePositionS "Reports the active position state of the 2nd row seat recliner; raw 4 = signal not available (SNA)";
CM_ SG_ 739 VCRIGHT_2RowSeatReclineAdjustmen "Indicates whether adjustment requests are currently permitted for the rear seat recliner";
CM_ SG_ 739 VCRIGHT_2RowSeatReclineFoldAllow "Indicates whether auto-fold requests are currently permitted for the rear seat recliner";
CM_ SG_ 739 VCRIGHT_2RowSeatReclineUnfoldAll "Indicates whether auto-unfold requests are currently permitted for the rear seat recliner";
CM_ SG_ 739 VCRIGHT_2RowSeatReclineNextToggl "Right body controller: 2 row seat recline next toggle direction; raw 2 = signal not available (SNA)";
CM_ SG_ 739 VCRIGHT_2RowSeatReclineChoreoBlo "Right body controller: 2 row seat recline choreo blocked by occupancy";
CM_ SG_ 739 VCRIGHT_2RowSeat1RClashAvoidance "Right body controller: 2 row seat1 r clash avoidance blocked reason";
CM_ SG_ 739 VCRIGHT_2RowSeat1RClashAvoi_0001 "Right body controller: 2 row seat1 r clash avoidance state";
CM_ SG_ 739 VCRIGHT_2RowSeatReclineAbsP_0001 "Right body controller: 2 row seat recline abs pos switch trans point";
CM_ SG_ 739 VC_AH_2RowRightSeatMovementHealt "Right body controller: AH 2 row right seat movement health";
CM_ SG_ 739 VCRIGHT_3RowSeatReclineState "Reports active state of the rear seat recliner; raw 15 = signal not available (SNA)";
CM_ SG_ 739 VCRIGHT_3RowSeatReclineDuty "Reports the third row seat recliner motor duty cycle";
CM_ SG_ 739 VCRIGHT_3RowSeatReclineCurrent "Reports the third row seat recliner motor current";
CM_ SG_ 739 VCRIGHT_3RowSeatReclineCalibrate "Reports calibration status of the third row seat recliner";
CM_ SG_ 739 VCRIGHT_3RowSeatReclinePositionR "Reports the third row seat recliner raw encoder count";
CM_ SG_ 739 VCRIGHT_3RowSeatReclineAngle "Reports position of the 3rd row seat recliner in degrees";
CM_ SG_ 739 VCRIGHT_3RowSeatReclineNextToggl "Right body controller: 3 row seat recline next toggle direction; raw 2 = signal not available (SNA)";
CM_ SG_ 739 VCRIGHT_3RRightSeatHeatCurrent "Current drawn by 3rd row right seat heater";
CM_ SG_ 739 VCRIGHT_3RRightSeatHeatDuty "3rd row right seat heater duty cycle";
CM_ SG_ 739 VCRIGHT_3RRightSeatHeatTmp "Temperature of 3rd row right seat heater as reported by NTC";
CM_ SG_ 739 VCRIGHT_3RRightSeatHeatTmpTarget "Target temperature for 3rd row right seat heater";
CM_ SG_ 739 VCRIGHT_3RRightSeatHeatInhibited "Status describing whether 3rd row right seat heat is inhibited";
CM_ SG_ 739 VCRIGHT_3RowSeatReclinePositionS "Reports active position state of the rear seat recliner; raw 4 = signal not available (SNA)";
CM_ SG_ 739 VCRIGHT_3RowSeatReclineAdjustmen "Indicates whether adjustment requests are currently permitted for the rear seat recliner";
CM_ SG_ 739 VCRIGHT_3RowSeatReclineFoldAllow "Indicates whether auto-fold requests are currently permitted for the rear seat recliner";
CM_ SG_ 739 VCRIGHT_3RowSeatReclineUnfoldAll "Indicates whether auto-unfold requests are currently permitted for the rear seat recliner";
CM_ SG_ 739 VCRIGHT_3RowSeatReclineChoreoBlo "Right body controller: 3 row seat recline choreo blocked by occupancy";
CM_ SG_ 739 VCRIGHT_3RowSeatReclineAbsPosSwi "Reports status of 2R seat recline absolute position (comfort zone) switch; raw 0 = signal not available (SNA)";
CM_ BO_ 835 "Right body controller message: status; frame length observed on a vehicle bus";
CM_ SG_ 835 VCRIGHT_autonomyBehaviorStatus "Right body controller: autonomy behavior status";
CM_ SG_ 835 VCRIGHT_LVBatteryTypeDBG "Right body controller: LV battery type DBG";
CM_ SG_ 835 VCRIGHT_rearDefrostState "Right body controller: rear defrost state; raw 0 = signal not available (SNA)";
CM_ SG_ 835 VCRIGHT_mirrorHeatState "Right body controller: mirror heat state; raw 0 = signal not available (SNA)";
CM_ SG_ 835 VCRIGHT_OTAState "Right body controller: OTA state";
CM_ SG_ 835 VCRIGHT_5AVoltage "Right body controller: 5 a voltage";
CM_ SG_ 835 VCRIGHT_vbatProt "Input voltage monitor to controller";
CM_ SG_ 835 VCRIGHT_rationalityAggregateCurr "Right body controller: rationality aggregate current";
CM_ SG_ 835 VCRIGHT_eFuseMgmtVoltageMonitor "Right body controller: e fuse mgmt voltage monitor";
CM_ SG_ 835 VCRIGHT_isSteeringWheelHeaterReq "Right body controller: is steering wheel heater req";
CM_ SG_ 835 VCRIGHT_steeringWheelHeaterDCTgt "Right body controller: steering wheel heater DC tgt; raw 127 = signal not available (SNA)";
BA_DEF_ BO_ "GenMsgCycleTime" INT 0 3600000;
BA_DEF_ BO_ "GenMsgSendType" ENUM "Cyclic","NotUsed","NotUsed","NotUsed","NotUsed","NotUsed","NotUsed","IfActive","NoMsgSendType","NotUsed";
BA_DEF_ BO_ "VFrameFormat" ENUM "StandardCAN","ExtendedCAN","reserved","J1939PG","reserved","reserved","reserved","reserved","reserved","reserved","reserved","reserved","reserved","reserved","StandardCAN_FD","ExtendedCAN_FD";
BA_DEF_ BO_ "CANFD_BRS" ENUM "0","1";
BA_DEF_ SG_ "GenSigSNA" STRING;
BA_DEF_ SG_ "SystemSignalLongSymbol" STRING;
BA_DEF_ SG_ "Confidence" ENUM "validated","plausible","layout-only","contradicted";
BA_DEF_DEF_ "GenMsgCycleTime" 0;
BA_DEF_DEF_ "GenMsgSendType" "NoMsgSendType";
BA_DEF_DEF_ "VFrameFormat" "StandardCAN";
BA_DEF_DEF_ "CANFD_BRS" "1";
BA_DEF_DEF_ "GenSigSNA" "";
BA_DEF_DEF_ "SystemSignalLongSymbol" "";
BA_DEF_DEF_ "Confidence" "layout-only";
BA_ "GenMsgCycleTime" BO_ 524 100;
BA_ "GenMsgSendType" BO_ 524 0;
BA_ "GenMsgCycleTime" BO_ 579 20;
BA_ "GenMsgSendType" BO_ 579 0;
BA_ "GenMsgCycleTime" BO_ 1675 100;
BA_ "GenMsgSendType" BO_ 1675 0;
BA_ "GenMsgCycleTime" BO_ 771 1000;
BA_ "GenMsgSendType" BO_ 771 0;
BA_ "GenMsgCycleTime" BO_ 995 200;
BA_ "GenMsgSendType" BO_ 995 0;
BA_ "GenMsgCycleTime" BO_ 1803 1000;
BA_ "GenMsgSendType" BO_ 1803 0;
BA_ "GenMsgCycleTime" BO_ 611 20;
BA_ "GenMsgSendType" BO_ 611 0;
BA_ "GenMsgCycleTime" BO_ 691 60;
BA_ "GenMsgSendType" BO_ 691 0;
BA_ "GenMsgCycleTime" BO_ 1859 1000;
BA_ "GenMsgSendType" BO_ 1859 0;
BA_ "GenMsgCycleTime" BO_ 794 50;
BA_ "GenMsgSendType" BO_ 794 0;
BA_ "GenMsgCycleTime" BO_ 1251 100;
BA_ "GenMsgSendType" BO_ 1251 0;
BA_ "GenMsgCycleTime" BO_ 739 200;
BA_ "GenMsgSendType" BO_ 739 0;
BA_ "GenMsgCycleTime" BO_ 835 100;
BA_ "GenMsgSendType" BO_ 835 0;
BA_ "Confidence" SG_ 524 VCRIGHT_wattsDemandEvap 0;
BA_ "Confidence" SG_ 524 VCRIGHT_hvacEvapEnabled 0;
BA_ "Confidence" SG_ 524 VCRIGHT_conditioningRequest 0;
BA_ "Confidence" SG_ 524 VCRIGHT_tempEvaporator 0;
BA_ "GenSigSNA" SG_ 524 VCRIGHT_tempEvaporator "2047";
BA_ "Confidence" SG_ 524 VCRIGHT_tempEvaporatorTarget 0;
BA_ "GenSigSNA" SG_ 524 VCRIGHT_tempEvaporatorTarget "255";
BA_ "Confidence" SG_ 524 VCRIGHT_hvacBlowerSpeedRPMReq 0;
BA_ "Confidence" SG_ 524 VCRIGHT_hvacPerfTestRunning 0;
BA_ "Confidence" SG_ 524 VCRIGHT_evapPerformanceLow 0;
BA_ "Confidence" SG_ 524 VCRIGHT_tempAmbientRaw 0;
BA_ "GenSigSNA" SG_ 524 VCRIGHT_tempAmbientRaw "0";
BA_ "Confidence" SG_ 524 VCRIGHT_hvacHeatingEnabledLeft 0;
BA_ "Confidence" SG_ 524 VCRIGHT_hvacHeatingEnabledRight 0;
BA_ "Confidence" SG_ 524 VCRIGHT_hvacPerfTestState 0;
BA_ "Confidence" SG_ 524 VCRIGHT_hvacUnavailable 0;
BA_ "Confidence" SG_ 524 VCRIGHT_hvacBlowerRPMActualAP 0;
BA_ "Confidence" SG_ 524 VCRIGHT_hvacEvapEnabledInColdAmb 0;
BA_ "SystemSignalLongSymbol" SG_ 524 VCRIGHT_hvacEvapEnabledInColdAmb "VCRIGHT_hvacEvapEnabledInColdAmbient";
BA_ "Confidence" SG_ 579 VCRIGHT_hvacStatusIndex 1;
BA_ "Confidence" SG_ 579 VCRIGHT_warmingUpStatus 0;
BA_ "Confidence" SG_ 579 VCRIGHT_coolingDownStatus 0;
BA_ "Confidence" SG_ 579 VCRIGHT_childModeHVACState 0;
BA_ "Confidence" SG_ 579 VCRIGHT_dogModeState 0;
BA_ "Confidence" SG_ 579 VCRIGHT_hvacCabinTempEstValid 0;
BA_ "Confidence" SG_ 579 VCRIGHT_COPNotRunningReasonFilte 0;
BA_ "SystemSignalLongSymbol" SG_ 579 VCRIGHT_COPNotRunningReasonFilte "VCRIGHT_COPNotRunningReasonFiltered";
BA_ "Confidence" SG_ 579 VCRIGHT_hvacCabinTempEst 0;
BA_ "Confidence" SG_ 579 VCRIGHT_hvacAirDistributionMode 0;
BA_ "Confidence" SG_ 579 VCRIGHT_hvacBlowerSegment 0;
BA_ "Confidence" SG_ 579 VCRIGHT_hvacRecirc 0;
BA_ "Confidence" SG_ 579 VCRIGHT_hvacACRunning 0;
BA_ "Confidence" SG_ 579 VCRIGHT_hvacPowerState 0;
BA_ "Confidence" SG_ 579 VCRIGHT_hvacVentStatus 0;
BA_ "Confidence" SG_ 579 VCRIGHT_hvacSecondRowState 0;
BA_ "Confidence" SG_ 579 VCRIGHT_hvacSystemNominal 0;
BA_ "Confidence" SG_ 579 VCRIGHT_hvacModelInitStatus 0;
BA_ "Confidence" SG_ 579 VCRIGHT_hvacMassflowRefrigSysRig 0;
BA_ "SystemSignalLongSymbol" SG_ 579 VCRIGHT_hvacMassflowRefrigSysRig "VCRIGHT_hvacMassflowRefrigSysRight";
BA_ "Confidence" SG_ 579 VCRIGHT_hvacRecircDoorPercent 0;
BA_ "Confidence" SG_ 579 VCRIGHT_tempDuctLeft 0;
BA_ "GenSigSNA" SG_ 579 VCRIGHT_tempDuctLeft "255";
BA_ "Confidence" SG_ 579 VCRIGHT_hvacMassflowRefrigSystem 0;
BA_ "Confidence" SG_ 579 VCRIGHT_tempDuctRight 0;
BA_ "GenSigSNA" SG_ 579 VCRIGHT_tempDuctRight "255";
BA_ "Confidence" SG_ 579 VCRIGHT_hvacMassflowRefrigSysLef 0;
BA_ "SystemSignalLongSymbol" SG_ 579 VCRIGHT_hvacMassflowRefrigSysLef "VCRIGHT_hvacMassflowRefrigSysLeft";
BA_ "Confidence" SG_ 579 VCRIGHT_hvacDuctTargetLeft 0;
BA_ "GenSigSNA" SG_ 579 VCRIGHT_hvacDuctTargetLeft "255";
BA_ "Confidence" SG_ 579 VCRIGHT_hvacDuctTargetRight 0;
BA_ "GenSigSNA" SG_ 579 VCRIGHT_hvacDuctTargetRight "255";
BA_ "Confidence" SG_ 579 VCRIGHT_enableTripleCameraFanPow 0;
BA_ "SystemSignalLongSymbol" SG_ 579 VCRIGHT_enableTripleCameraFanPow "VCRIGHT_enableTripleCameraFanPowerInSleep";
BA_ "Confidence" SG_ 579 VCRIGHT_tempDuctRightUpper 0;
BA_ "GenSigSNA" SG_ 579 VCRIGHT_tempDuctRightUpper "255";
BA_ "Confidence" SG_ 579 VCRIGHT_hpSplitTempsEnabled 0;
BA_ "Confidence" SG_ 579 VCRIGHT_hvacEvapInletTempEstimat 0;
BA_ "GenSigSNA" SG_ 579 VCRIGHT_hvacEvapInletTempEstimat "1023";
BA_ "SystemSignalLongSymbol" SG_ 579 VCRIGHT_hvacEvapInletTempEstimat "VCRIGHT_hvacEvapInletTempEstimate";
BA_ "Confidence" SG_ 579 VCRIGHT_tempMonitorNotNominal 0;
BA_ "Confidence" SG_ 579 VCRIGHT_hvacCabinAtTempTarget 0;
BA_ "Confidence" SG_ 579 VCRIGHT_hvacReqSecondRow 0;
BA_ "Confidence" SG_ 579 VCRIGHT_hvacAirflowReason 0;
BA_ "Confidence" SG_ 579 VCRIGHT_autoHvacBlowerShouldLimi 0;
BA_ "SystemSignalLongSymbol" SG_ 579 VCRIGHT_autoHvacBlowerShouldLimi "VCRIGHT_autoHvacBlowerShouldLimit";
BA_ "Confidence" SG_ 579 VCRIGHT_hvacReqThirdRow 0;
BA_ "Confidence" SG_ 579 VCRIGHT_solarLoadOnVehicle 0;
BA_ "GenSigSNA" SG_ 579 VCRIGHT_solarLoadOnVehicle "255";
BA_ "Confidence" SG_ 579 VCRIGHT_refrigDistCommanded 0;
BA_ "Confidence" SG_ 579 VCRIGHT_hvacFrontRightSeatFanSta 0;
BA_ "SystemSignalLongSymbol" SG_ 579 VCRIGHT_hvacFrontRightSeatFanSta "VCRIGHT_hvacFrontRightSeatFanStatus";
BA_ "Confidence" SG_ 579 VCRIGHT_hvacFrontLeftSeatFanStat 0;
BA_ "SystemSignalLongSymbol" SG_ 579 VCRIGHT_hvacFrontLeftSeatFanStat "VCRIGHT_hvacFrontLeftSeatFanStatus";
BA_ "Confidence" SG_ 579 VCRIGHT_hvacRefHighPowerRequest 0;
BA_ "Confidence" SG_ 579 VCRIGHT_windshieldCameraHeaterDu 0;
BA_ "SystemSignalLongSymbol" SG_ 579 VCRIGHT_windshieldCameraHeaterDu "VCRIGHT_windshieldCameraHeaterDutyRequest";
BA_ "Confidence" SG_ 579 VCRIGHT_extendedHvacPerfTestSupp 0;
BA_ "SystemSignalLongSymbol" SG_ 579 VCRIGHT_extendedHvacPerfTestSupp "VCRIGHT_extendedHvacPerfTestSupportState";
BA_ "Confidence" SG_ 579 VCRIGHT_hvacFrontRightSeatHeatSt 0;
BA_ "SystemSignalLongSymbol" SG_ 579 VCRIGHT_hvacFrontRightSeatHeatSt "VCRIGHT_hvacFrontRightSeatHeatStatus";
BA_ "Confidence" SG_ 579 VCRIGHT_hvacSeatFrontLeftTempTar 0;
BA_ "SystemSignalLongSymbol" SG_ 579 VCRIGHT_hvacSeatFrontLeftTempTar "VCRIGHT_hvacSeatFrontLeftTempTarget";
BA_ "Confidence" SG_ 579 VCRIGHT_hvacManualToAutoNotify 0;
BA_ "Confidence" SG_ 579 VCRIGHT_hvacRequestsFullAuto 0;
BA_ "Confidence" SG_ 579 VCRIGHT_passengerPresentHvacCycl 0;
BA_ "SystemSignalLongSymbol" SG_ 579 VCRIGHT_passengerPresentHvacCycl "VCRIGHT_passengerPresentHvacCycle";
BA_ "Confidence" SG_ 579 VCRIGHT_hvacRequestsAutoIntake 0;
BA_ "Confidence" SG_ 579 VCRIGHT_steeringWheelHeatStatus 0;
BA_ "Confidence" SG_ 579 VCRIGHT_autoDefogStatus 0;
BA_ "Confidence" SG_ 579 VCRIGHT_solarElevation 0;
BA_ "GenSigSNA" SG_ 579 VCRIGHT_solarElevation "256";
BA_ "Confidence" SG_ 579 VCRIGHT_minsToSunrise 0;
BA_ "GenSigSNA" SG_ 579 VCRIGHT_minsToSunrise "255";
BA_ "Confidence" SG_ 579 VCRIGHT_minsToSunset 0;
BA_ "GenSigSNA" SG_ 579 VCRIGHT_minsToSunset "255";
BA_ "Confidence" SG_ 579 VCRIGHT_hvacLimitedReasonRight 0;
BA_ "Confidence" SG_ 579 VCRIGHT_hvacLimitedReasonLeft 0;
BA_ "Confidence" SG_ 579 VCRIGHT_hvacOverheatProtActive 0;
BA_ "Confidence" SG_ 579 VCRIGHT_autoSwingAvailable 0;
BA_ "Confidence" SG_ 579 VCRIGHT_tempDuctLeftUpper 0;
BA_ "GenSigSNA" SG_ 579 VCRIGHT_tempDuctLeftUpper "255";
BA_ "Confidence" SG_ 579 VCRIGHT_hvacFrontLeftSeatHeatSta 0;
BA_ "SystemSignalLongSymbol" SG_ 579 VCRIGHT_hvacFrontLeftSeatHeatSta "VCRIGHT_hvacFrontLeftSeatHeatStatus";
BA_ "Confidence" SG_ 579 VCRIGHT_hvacQdotLeft 0;
BA_ "Confidence" SG_ 579 VCRIGHT_hvacQdotRight 0;
BA_ "Confidence" SG_ 579 VCRIGHT_tempDuctLeftLower 0;
BA_ "GenSigSNA" SG_ 579 VCRIGHT_tempDuctLeftLower "255";
BA_ "Confidence" SG_ 579 VCRIGHT_tempDuctRightLower 0;
BA_ "GenSigSNA" SG_ 579 VCRIGHT_tempDuctRightLower "255";
BA_ "Confidence" SG_ 579 VCRIGHT_foggingControllerResetRe 0;
BA_ "SystemSignalLongSymbol" SG_ 579 VCRIGHT_foggingControllerResetRe "VCRIGHT_foggingControllerResetReason";
BA_ "Confidence" SG_ 579 VCRIGHT_modeledCabinPressure 0;
BA_ "Confidence" SG_ 579 VCRIGHT_blowerTorqueIndex 0;
BA_ "Confidence" SG_ 579 VCRIGHT_autoSwingLeftPosX 0;
BA_ "Confidence" SG_ 579 VCRIGHT_autoSwingRightPositionX 0;
BA_ "Confidence" SG_ 1675 VCRIGHT_hvacSeat1RLCushionFanTrg 0;
BA_ "SystemSignalLongSymbol" SG_ 1675 VCRIGHT_hvacSeat1RLCushionFanTrg "VCRIGHT_hvacSeat1RLCushionFanTrgt";
BA_ "Confidence" SG_ 1675 VCRIGHT_hvacSeat1RLBackrestFanTr 0;
BA_ "SystemSignalLongSymbol" SG_ 1675 VCRIGHT_hvacSeat1RLBackrestFanTr "VCRIGHT_hvacSeat1RLBackrestFanTrgt";
BA_ "Confidence" SG_ 1675 VCRIGHT_hvacSeat1RRCushionFanTrg 0;
BA_ "SystemSignalLongSymbol" SG_ 1675 VCRIGHT_hvacSeat1RRCushionFanTrg "VCRIGHT_hvacSeat1RRCushionFanTrgt";
BA_ "Confidence" SG_ 1675 VCRIGHT_hvacSeat1RRBackrestFanTr 0;
BA_ "SystemSignalLongSymbol" SG_ 1675 VCRIGHT_hvacSeat1RRBackrestFanTr "VCRIGHT_hvacSeat1RRBackrestFanTrgt";
BA_ "Confidence" SG_ 1675 VCRIGHT_hvac2RActuatorsEnable 0;
BA_ "Confidence" SG_ 1675 VCRIGHT_hvac2RLeftLateralTarget 0;
BA_ "Confidence" SG_ 1675 VCRIGHT_hvac2RLeftVerticalTarget 0;
BA_ "Confidence" SG_ 1675 VCRIGHT_hvac2RRightLateralTarget 0;
BA_ "Confidence" SG_ 1675 VCRIGHT_hvac2RRightVerticalTarge 0;
BA_ "SystemSignalLongSymbol" SG_ 1675 VCRIGHT_hvac2RRightVerticalTarge "VCRIGHT_hvac2RRightVerticalTarget";
BA_ "Confidence" SG_ 771 VCRIGHT_infoIndex 1;
BA_ "Confidence" SG_ 771 VCRIGHT_infoBuildType 0;
BA_ "Confidence" SG_ 771 VCRIGHT_infoBuildConfigId 0;
BA_ "Confidence" SG_ 771 VCRIGHT_infoHardwareId 0;
BA_ "Confidence" SG_ 771 VCRIGHT_infoComponentId 0;
BA_ "Confidence" SG_ 771 VCRIGHT_infoPcbaId 0;
BA_ "Confidence" SG_ 771 VCRIGHT_infoAssemblyId 0;
BA_ "GenSigSNA" SG_ 771 VCRIGHT_infoAssemblyId "255";
BA_ "Confidence" SG_ 771 VCRIGHT_infoUsageId 0;
BA_ "Confidence" SG_ 771 VCRIGHT_infoSubUsageId 0;
BA_ "Confidence" SG_ 771 VCRIGHT_infoAppCrc 0;
BA_ "Confidence" SG_ 771 VCRIGHT_infoLUMBARRAppCRC 0;
BA_ "Confidence" SG_ 771 VCRIGHT_infoAppGitHash 0;
BA_ "Confidence" SG_ 771 VCRIGHT_infoBootGitHash 0;
BA_ "Confidence" SG_ 771 VCRIGHT_infoPlatformType 0;
BA_ "Confidence" SG_ 771 VCRIGHT_infoBootUdsProtoVersion 0;
BA_ "Confidence" SG_ 771 VCRIGHT_infoBootCrc 0;
BA_ "Confidence" SG_ 995 VCRIGHT_brakeLightStatus 0;
BA_ "GenSigSNA" SG_ 995 VCRIGHT_brakeLightStatus "3";
BA_ "Confidence" SG_ 995 VCRIGHT_tailLightStatus 0;
BA_ "GenSigSNA" SG_ 995 VCRIGHT_tailLightStatus "3";
BA_ "Confidence" SG_ 995 VCRIGHT_turnSignalStatus 0;
BA_ "GenSigSNA" SG_ 995 VCRIGHT_turnSignalStatus "3";
BA_ "Confidence" SG_ 995 VCRIGHT_reverseLightStatus 0;
BA_ "GenSigSNA" SG_ 995 VCRIGHT_reverseLightStatus "3";
BA_ "Confidence" SG_ 995 VCRIGHT_rearFogLightStatus 0;
BA_ "GenSigSNA" SG_ 995 VCRIGHT_rearFogLightStatus "3";
BA_ "Confidence" SG_ 995 VCRIGHT_leftInteriorTrunkLightRe 0;
BA_ "SystemSignalLongSymbol" SG_ 995 VCRIGHT_leftInteriorTrunkLightRe "VCRIGHT_leftInteriorTrunkLightReq";
BA_ "Confidence" SG_ 995 VCRIGHT_audioCurrentSpikeDetecte 0;
BA_ "SystemSignalLongSymbol" SG_ 995 VCRIGHT_audioCurrentSpikeDetecte "VCRIGHT_audioCurrentSpikeDetected";
BA_ "Confidence" SG_ 995 VCRIGHT_fasciaReverseLightStatus 0;
BA_ "GenSigSNA" SG_ 995 VCRIGHT_fasciaReverseLightStatus "3";
BA_ "Confidence" SG_ 995 VCRIGHT_fasciaRearFogStatus 0;
BA_ "GenSigSNA" SG_ 995 VCRIGHT_fasciaRearFogStatus "3";
BA_ "Confidence" SG_ 995 VCRIGHT_fasciaTailLightStatus 0;
BA_ "GenSigSNA" SG_ 995 VCRIGHT_fasciaTailLightStatus "3";
BA_ "Confidence" SG_ 995 VCRIGHT_fasciaLeftTurnSignalStat 0;
BA_ "GenSigSNA" SG_ 995 VCRIGHT_fasciaLeftTurnSignalStat "3";
BA_ "SystemSignalLongSymbol" SG_ 995 VCRIGHT_fasciaLeftTurnSignalStat "VCRIGHT_fasciaLeftTurnSignalStatus";
BA_ "Confidence" SG_ 995 VCRIGHT_fasciaRightTurnSignalSta 0;
BA_ "GenSigSNA" SG_ 995 VCRIGHT_fasciaRightTurnSignalSta "3";
BA_ "SystemSignalLongSymbol" SG_ 995 VCRIGHT_fasciaRightTurnSignalSta "VCRIGHT_fasciaRightTurnSignalStatus";
BA_ "Confidence" SG_ 995 VCRIGHT_CHMSLLightStatus 0;
BA_ "GenSigSNA" SG_ 995 VCRIGHT_CHMSLLightStatus "3";
BA_ "Confidence" SG_ 1803 VCRIGHT_logging0point1HzIndex 1;
BA_ "Confidence" SG_ 1803 VCRIGHT_glareShieldEstimatedResi 0;
BA_ "SystemSignalLongSymbol" SG_ 1803 VCRIGHT_glareShieldEstimatedResi "VCRIGHT_glareShieldEstimatedResistance";
BA_ "Confidence" SG_ 1803 VCRIGHT_cabinAirFilterLifeRemain 0;
BA_ "SystemSignalLongSymbol" SG_ 1803 VCRIGHT_cabinAirFilterLifeRemain "VCRIGHT_cabinAirFilterLifeRemaining";
BA_ "Confidence" SG_ 1803 VCRIGHT_HEPAAirFilterLifeRemaini 0;
BA_ "SystemSignalLongSymbol" SG_ 1803 VCRIGHT_HEPAAirFilterLifeRemaini "VCRIGHT_HEPAAirFilterLifeRemaining";
BA_ "Confidence" SG_ 1803 VCRIGHT_leftPTCCompromisedRod 0;
BA_ "Confidence" SG_ 1803 VCRIGHT_rightPTCCompromisedRod 0;
BA_ "Confidence" SG_ 1803 VCRIGHT_hepaFilterHealthScore 0;
BA_ "Confidence" SG_ 1803 VCRIGHT_cabinFilterHealthScore 0;
BA_ "Confidence" SG_ 1803 VCRIGHT_cabinTempBreathLevelFOff 0;
BA_ "GenSigSNA" SG_ 1803 VCRIGHT_cabinTempBreathLevelFOff "255";
BA_ "Confidence" SG_ 1803 VCRIGHT_airDistributionModeAdjus 0;
BA_ "SystemSignalLongSymbol" SG_ 1803 VCRIGHT_airDistributionModeAdjus "VCRIGHT_airDistributionModeAdjustmentFactor";
BA_ "Confidence" SG_ 1803 VCRIGHT_hvacLHBleedEndStop 0;
BA_ "Confidence" SG_ 1803 VCRIGHT_hvacRHBleedEndStop 0;
BA_ "Confidence" SG_ 1803 VCRIGHT_hvacLHVaneEndStop 0;
BA_ "Confidence" SG_ 1803 VCRIGHT_hvacRHVaneEndStop 0;
BA_ "Confidence" SG_ 1803 VCRIGHT_hvacUpperModeEndStop 0;
BA_ "Confidence" SG_ 1803 VCRIGHT_hvacLowerModeEndStop 0;
BA_ "Confidence" SG_ 1803 VCRIGHT_hvacIntakeEndStop 0;
BA_ "Confidence" SG_ 1803 VCRIGHT_hvacLHBleedZeroStop 0;
BA_ "Confidence" SG_ 1803 VCRIGHT_hvacRHBleedZeroStop 0;
BA_ "Confidence" SG_ 1803 VCRIGHT_hvacLHVaneZeroStop 0;
BA_ "Confidence" SG_ 1803 VCRIGHT_hvacRHVaneZeroStop 0;
BA_ "Confidence" SG_ 1803 VCRIGHT_hvacUpperModeZeroStop 0;
BA_ "Confidence" SG_ 1803 VCRIGHT_hvacLowerModeZeroStop 0;
BA_ "Confidence" SG_ 1803 VCRIGHT_hvacIntakeZeroStop 0;
BA_ "Confidence" SG_ 1803 VCRIGHT_averageDuctTempFCooling 0;
BA_ "GenSigSNA" SG_ 1803 VCRIGHT_averageDuctTempFCooling "255";
BA_ "Confidence" SG_ 1803 VCRIGHT_fasciaTailLeftLightCurre 0;
BA_ "GenSigSNA" SG_ 1803 VCRIGHT_fasciaTailLeftLightCurre "511";
BA_ "SystemSignalLongSymbol" SG_ 1803 VCRIGHT_fasciaTailLeftLightCurre "VCRIGHT_fasciaTailLeftLightCurrent";
BA_ "Confidence" SG_ 1803 VCRIGHT_fasciaTailLeftLight_0001 3;
BA_ "GenSigSNA" SG_ 1803 VCRIGHT_fasciaTailLeftLight_0001 "0";
BA_ "SystemSignalLongSymbol" SG_ 1803 VCRIGHT_fasciaTailLeftLight_0001 "VCRIGHT_fasciaTailLeftLightCurrentSenseState";
BA_ "Confidence" SG_ 1803 VCRIGHT_fasciaTailRightLightCurr 0;
BA_ "GenSigSNA" SG_ 1803 VCRIGHT_fasciaTailRightLightCurr "511";
BA_ "SystemSignalLongSymbol" SG_ 1803 VCRIGHT_fasciaTailRightLightCurr "VCRIGHT_fasciaTailRightLightCurrent";
BA_ "Confidence" SG_ 1803 VCRIGHT_fasciaTailRightLigh_0001 3;
BA_ "GenSigSNA" SG_ 1803 VCRIGHT_fasciaTailRightLigh_0001 "0";
BA_ "SystemSignalLongSymbol" SG_ 1803 VCRIGHT_fasciaTailRightLigh_0001 "VCRIGHT_fasciaTailRightLightCurrentSenseState";
BA_ "Confidence" SG_ 1803 VCRIGHT_liftgateTailLeftLightCur 0;
BA_ "GenSigSNA" SG_ 1803 VCRIGHT_liftgateTailLeftLightCur "511";
BA_ "SystemSignalLongSymbol" SG_ 1803 VCRIGHT_liftgateTailLeftLightCur "VCRIGHT_liftgateTailLeftLightCurrent";
BA_ "Confidence" SG_ 1803 VCRIGHT_liftgateTailLeftLig_0001 3;
BA_ "GenSigSNA" SG_ 1803 VCRIGHT_liftgateTailLeftLig_0001 "0";
BA_ "SystemSignalLongSymbol" SG_ 1803 VCRIGHT_liftgateTailLeftLig_0001 "VCRIGHT_liftgateTailLeftLightCurrentSenseState";
BA_ "Confidence" SG_ 1803 VCRIGHT_liftgateTailRightLightCu 3;
BA_ "GenSigSNA" SG_ 1803 VCRIGHT_liftgateTailRightLightCu "0";
BA_ "SystemSignalLongSymbol" SG_ 1803 VCRIGHT_liftgateTailRightLightCu "VCRIGHT_liftgateTailRightLightCurrentSenseState";
BA_ "Confidence" SG_ 1803 VCRIGHT_ambientTempLimp 0;
BA_ "GenSigSNA" SG_ 1803 VCRIGHT_ambientTempLimp "255";
BA_ "Confidence" SG_ 1803 VCRIGHT_cabinProbeTempLimp 0;
BA_ "GenSigSNA" SG_ 1803 VCRIGHT_cabinProbeTempLimp "255";
BA_ "Confidence" SG_ 1803 VCRIGHT_thsTempLimp 3;
BA_ "GenSigSNA" SG_ 1803 VCRIGHT_thsTempLimp "255";
BA_ "Confidence" SG_ 1803 VCRIGHT_thsCabinWaterMassLimp 0;
BA_ "Confidence" SG_ 1803 VCRIGHT_thsSolarIrradianceLimp 0;
BA_ "GenSigSNA" SG_ 1803 VCRIGHT_thsSolarIrradianceLimp "255";
BA_ "Confidence" SG_ 1803 VCRIGHT_silentWakeRecordCount 0;
BA_ "Confidence" SG_ 1803 VCRIGHT_interiorCameraLedCurrent 0;
BA_ "GenSigSNA" SG_ 1803 VCRIGHT_interiorCameraLedCurrent "255";
BA_ "Confidence" SG_ 1803 VCRIGHT_evapCondensateMass 0;
BA_ "Confidence" SG_ 1803 VCRIGHT_airwaveRightLateralTotal 0;
BA_ "SystemSignalLongSymbol" SG_ 1803 VCRIGHT_airwaveRightLateralTotal "VCRIGHT_airwaveRightLateralTotalTravel";
BA_ "Confidence" SG_ 1803 VCRIGHT_airwaveLeftLateralTotalT 0;
BA_ "SystemSignalLongSymbol" SG_ 1803 VCRIGHT_airwaveLeftLateralTotalT "VCRIGHT_airwaveLeftLateralTotalTravel";
BA_ "Confidence" SG_ 1803 VCRIGHT_hvacRearEndStop 0;
BA_ "Confidence" SG_ 1803 VCRIGHT_hvacRearZeroStop 0;
BA_ "Confidence" SG_ 1803 VCRIGHT_evapLoadInFresh 0;
BA_ "Confidence" SG_ 1803 VCRIGHT_evapLoadInRecirc 0;
BA_ "Confidence" SG_ 1803 VCRIGHT_tempIncarCabinDeep 0;
BA_ "GenSigSNA" SG_ 1803 VCRIGHT_tempIncarCabinDeep "255";
BA_ "Confidence" SG_ 1803 VCRIGHT_cabinTempBreathLeve_0001 0;
BA_ "GenSigSNA" SG_ 1803 VCRIGHT_cabinTempBreathLeve_0001 "255";
BA_ "SystemSignalLongSymbol" SG_ 1803 VCRIGHT_cabinTempBreathLeve_0001 "VCRIGHT_cabinTempBreathLevelF10minHeating";
BA_ "Confidence" SG_ 1803 VCRIGHT_cabinTempBreathLevelF10m 0;
BA_ "GenSigSNA" SG_ 1803 VCRIGHT_cabinTempBreathLevelF10m "255";
BA_ "SystemSignalLongSymbol" SG_ 1803 VCRIGHT_cabinTempBreathLevelF10m "VCRIGHT_cabinTempBreathLevelF10minCooling";
BA_ "Confidence" SG_ 1803 VCRIGHT_cabinTempBreathLeve_0002 0;
BA_ "GenSigSNA" SG_ 1803 VCRIGHT_cabinTempBreathLeve_0002 "255";
BA_ "SystemSignalLongSymbol" SG_ 1803 VCRIGHT_cabinTempBreathLeve_0002 "VCRIGHT_cabinTempBreathLevelF5minHeating";
BA_ "Confidence" SG_ 1803 VCRIGHT_cabinTempBreathLevelF5mi 0;
BA_ "GenSigSNA" SG_ 1803 VCRIGHT_cabinTempBreathLevelF5mi "255";
BA_ "SystemSignalLongSymbol" SG_ 1803 VCRIGHT_cabinTempBreathLevelF5mi "VCRIGHT_cabinTempBreathLevelF5minCooling";
BA_ "Confidence" SG_ 1803 VCRIGHT_foggingMonitorRuntime 0;
BA_ "Confidence" SG_ 1803 VCRIGHT_cabinTempInteriorFHeatin 0;
BA_ "GenSigSNA" SG_ 1803 VCRIGHT_cabinTempInteriorFHeatin "255";
BA_ "SystemSignalLongSymbol" SG_ 1803 VCRIGHT_cabinTempInteriorFHeatin "VCRIGHT_cabinTempInteriorFHeating";
BA_ "Confidence" SG_ 1803 VCRIGHT_cabinTempInteriorFCoolin 0;
BA_ "GenSigSNA" SG_ 1803 VCRIGHT_cabinTempInteriorFCoolin "255";
BA_ "SystemSignalLongSymbol" SG_ 1803 VCRIGHT_cabinTempInteriorFCoolin "VCRIGHT_cabinTempInteriorFCooling";
BA_ "Confidence" SG_ 1803 VCRIGHT_filterLifeBlowerTorque 0;
BA_ "GenSigSNA" SG_ 1803 VCRIGHT_filterLifeBlowerTorque "1023";
BA_ "Confidence" SG_ 1803 VCRIGHT_averageDuctTempFHeating 0;
BA_ "GenSigSNA" SG_ 1803 VCRIGHT_averageDuctTempFHeating "255";
BA_ "Confidence" SG_ 1803 VCRIGHT_thsSolarSensorType 0;
BA_ "Confidence" SG_ 1803 VCRIGHT_thsTempSensorType 0;
BA_ "Confidence" SG_ 611 VCRIGHT_logging10HzIndex 1;
BA_ "Confidence" SG_ 611 VCRIGHT_hvacLHBleedTarget 0;
BA_ "Confidence" SG_ 611 VCRIGHT_hvacRHBleedTarget 0;
BA_ "Confidence" SG_ 611 VCRIGHT_hvacLHVaneTarget 0;
BA_ "Confidence" SG_ 611 VCRIGHT_hvacRHVaneTarget 0;
BA_ "Confidence" SG_ 611 VCRIGHT_hvacUpperModeTarget 0;
BA_ "Confidence" SG_ 611 VCRIGHT_hvacLowerModeTarget 0;
BA_ "Confidence" SG_ 611 VCRIGHT_hvacIntakeTarget 0;
BA_ "Confidence" SG_ 611 VCRIGHT_hvacLHBleedPosition 0;
BA_ "Confidence" SG_ 611 VCRIGHT_hvacRHBleedPosition 0;
BA_ "Confidence" SG_ 611 VCRIGHT_hvacLHVanePosition 0;
BA_ "Confidence" SG_ 611 VCRIGHT_hvacRHVanePosition 0;
BA_ "Confidence" SG_ 611 VCRIGHT_hvacUpperModePosition 0;
BA_ "Confidence" SG_ 611 VCRIGHT_hvacLowerModePosition 0;
BA_ "Confidence" SG_ 611 VCRIGHT_hvacIntakePosition 0;
BA_ "Confidence" SG_ 611 VCRIGHT_hvacLHBleedActuatorState 0;
BA_ "Confidence" SG_ 611 VCRIGHT_hvacRHBleedActuatorState 0;
BA_ "Confidence" SG_ 611 VCRIGHT_hvacLHVaneActuatorState 0;
BA_ "Confidence" SG_ 611 VCRIGHT_hvacRHVaneActuatorState 0;
BA_ "Confidence" SG_ 611 VCRIGHT_hvacUpperModeActState 0;
BA_ "Confidence" SG_ 611 VCRIGHT_hvacLowerModeActState 0;
BA_ "Confidence" SG_ 611 VCRIGHT_hvacIntakeActuatorState 0;
BA_ "Confidence" SG_ 611 VCRIGHT_hvacRearActuatorState 0;
BA_ "Confidence" SG_ 611 VCRIGHT_EvapPulldownBiasActive 0;
BA_ "Confidence" SG_ 611 VCRIGHT_tempDatLeftEst 0;
BA_ "GenSigSNA" SG_ 611 VCRIGHT_tempDatLeftEst "255";
BA_ "Confidence" SG_ 611 VCRIGHT_tempDatRightEst 0;
BA_ "GenSigSNA" SG_ 611 VCRIGHT_tempDatRightEst "255";
BA_ "Confidence" SG_ 611 VCRIGHT_tempDuctLeftEst 0;
BA_ "GenSigSNA" SG_ 611 VCRIGHT_tempDuctLeftEst "255";
BA_ "Confidence" SG_ 611 VCRIGHT_tempDuctRightEst 0;
BA_ "GenSigSNA" SG_ 611 VCRIGHT_tempDuctRightEst "255";
BA_ "Confidence" SG_ 611 VCRIGHT_ptcHeaterBadRodDetection 0;
BA_ "SystemSignalLongSymbol" SG_ 611 VCRIGHT_ptcHeaterBadRodDetection "VCRIGHT_ptcHeaterBadRodDetectionState";
BA_ "Confidence" SG_ 611 VCRIGHT_upperModeDrvActuatorStat 0;
BA_ "SystemSignalLongSymbol" SG_ 611 VCRIGHT_upperModeDrvActuatorStat "VCRIGHT_upperModeDrvActuatorState";
BA_ "Confidence" SG_ 611 VCRIGHT_leftVerticalActuato_0001 0;
BA_ "SystemSignalLongSymbol" SG_ 611 VCRIGHT_leftVerticalActuato_0001 "VCRIGHT_leftVerticalActuatorStatus";
BA_ "Confidence" SG_ 611 VCRIGHT_leftLateralActuatorStatu 0;
BA_ "SystemSignalLongSymbol" SG_ 611 VCRIGHT_leftLateralActuatorStatu "VCRIGHT_leftLateralActuatorStatus";
BA_ "Confidence" SG_ 611 VCRIGHT_rightVerticalActuat_0001 0;
BA_ "SystemSignalLongSymbol" SG_ 611 VCRIGHT_rightVerticalActuat_0001 "VCRIGHT_rightVerticalActuatorStatus";
BA_ "Confidence" SG_ 611 VCRIGHT_rightLateralActuato_0001 0;
BA_ "SystemSignalLongSymbol" SG_ 611 VCRIGHT_rightLateralActuato_0001 "VCRIGHT_rightLateralActuatorStatus";
BA_ "Confidence" SG_ 611 VCRIGHT_leftVerticalActuatorStat 0;
BA_ "SystemSignalLongSymbol" SG_ 611 VCRIGHT_leftVerticalActuatorStat "VCRIGHT_leftVerticalActuatorState";
BA_ "Confidence" SG_ 611 VCRIGHT_leftLateralActuatorState 0;
BA_ "Confidence" SG_ 611 VCRIGHT_rightVerticalActuatorSta 0;
BA_ "SystemSignalLongSymbol" SG_ 611 VCRIGHT_rightVerticalActuatorSta "VCRIGHT_rightVerticalActuatorState";
BA_ "Confidence" SG_ 611 VCRIGHT_rightLateralActuatorStat 0;
BA_ "SystemSignalLongSymbol" SG_ 611 VCRIGHT_rightLateralActuatorStat "VCRIGHT_rightLateralActuatorState";
BA_ "Confidence" SG_ 611 VCRIGHT_windshieldRHExteriorSurf 0;
BA_ "GenSigSNA" SG_ 611 VCRIGHT_windshieldRHExteriorSurf "255";
BA_ "SystemSignalLongSymbol" SG_ 611 VCRIGHT_windshieldRHExteriorSurf "VCRIGHT_windshieldRHExteriorSurface";
BA_ "Confidence" SG_ 611 VCRIGHT_leftVerticalActuatorDuty 0;
BA_ "Confidence" SG_ 611 VCRIGHT_leftLateralActuatorDuty 0;
BA_ "Confidence" SG_ 611 VCRIGHT_rightVerticalActuatorDut 0;
BA_ "SystemSignalLongSymbol" SG_ 611 VCRIGHT_rightVerticalActuatorDut "VCRIGHT_rightVerticalActuatorDuty";
BA_ "Confidence" SG_ 611 VCRIGHT_rightLateralActuatorDuty 0;
BA_ "Confidence" SG_ 611 VCRIGHT_frontLeftSeatTempTargetQ 0;
BA_ "SystemSignalLongSymbol" SG_ 611 VCRIGHT_frontLeftSeatTempTargetQ "VCRIGHT_frontLeftSeatTempTargetQuasiSS";
BA_ "Confidence" SG_ 611 VCRIGHT_frontRightSeatTempTarget 0;
BA_ "SystemSignalLongSymbol" SG_ 611 VCRIGHT_frontRightSeatTempTarget "VCRIGHT_frontRightSeatTempTargetQuasiSS";
BA_ "Confidence" SG_ 611 VCRIGHT_hvacRearPosition 0;
BA_ "Confidence" SG_ 611 VCRIGHT_hvacRearTarget 0;
BA_ "Confidence" SG_ 691 VCRIGHT_logging1HzIndex 1;
BA_ "Confidence" SG_ 691 VCRIGHT_glareShieldHeaterState 0;
BA_ "Confidence" SG_ 691 VCRIGHT_tempIncarCabinProbe 0;
BA_ "GenSigSNA" SG_ 691 VCRIGHT_tempIncarCabinProbe "255";
BA_ "Confidence" SG_ 691 VCRIGHT_cabinTempInteriorL2 0;
BA_ "GenSigSNA" SG_ 691 VCRIGHT_cabinTempInteriorL2 "255";
BA_ "Confidence" SG_ 691 VCRIGHT_cabinTempInteriorSunnyL2 0;
BA_ "GenSigSNA" SG_ 691 VCRIGHT_cabinTempInteriorSunnyL2 "255";
BA_ "Confidence" SG_ 691 VCRIGHT_tempIncarCabinMid 0;
BA_ "GenSigSNA" SG_ 691 VCRIGHT_tempIncarCabinMid "250";
BA_ "Confidence" SG_ 691 VCRIGHT_cabinTempInteriorL3 0;
BA_ "GenSigSNA" SG_ 691 VCRIGHT_cabinTempInteriorL3 "255";
BA_ "Confidence" SG_ 691 VCRIGHT_cabinTempInteriorSunnyL3 0;
BA_ "GenSigSNA" SG_ 691 VCRIGHT_cabinTempInteriorSunnyL3 "255";
BA_ "Confidence" SG_ 691 VCRIGHT_tempWetBulb 0;
BA_ "GenSigSNA" SG_ 691 VCRIGHT_tempWetBulb "255";
BA_ "Confidence" SG_ 691 VCRIGHT_isRainingOrSnowing 0;
BA_ "Confidence" SG_ 691 VCRIGHT_cabinTempGlassRoof 0;
BA_ "GenSigSNA" SG_ 691 VCRIGHT_cabinTempGlassRoof "255";
BA_ "Confidence" SG_ 691 VCRIGHT_cabinTempWindshield 0;
BA_ "GenSigSNA" SG_ 691 VCRIGHT_cabinTempWindshield "255";
BA_ "Confidence" SG_ 691 VCRIGHT_cabinTempInterior 0;
BA_ "GenSigSNA" SG_ 691 VCRIGHT_cabinTempInterior "255";
BA_ "Confidence" SG_ 691 VCRIGHT_cabinTempInteriorSunny 0;
BA_ "GenSigSNA" SG_ 691 VCRIGHT_cabinTempInteriorSunny "255";
BA_ "Confidence" SG_ 691 VCRIGHT_cabinTempSideGlassLeft 0;
BA_ "GenSigSNA" SG_ 691 VCRIGHT_cabinTempSideGlassLeft "255";
BA_ "Confidence" SG_ 691 VCRIGHT_cabinTempSideGlassRight 0;
BA_ "GenSigSNA" SG_ 691 VCRIGHT_cabinTempSideGlassRight "255";
BA_ "Confidence" SG_ 691 VCRIGHT_cabinTempBreathLevel 0;
BA_ "GenSigSNA" SG_ 691 VCRIGHT_cabinTempBreathLevel "255";
BA_ "Confidence" SG_ 691 VCRIGHT_pcbaTemperature 0;
BA_ "Confidence" SG_ 691 VCRIGHT_wattsHeaterLeftTotal 0;
BA_ "Confidence" SG_ 691 VCRIGHT_wattsHeaterRightTotal 0;
BA_ "Confidence" SG_ 691 VCRIGHT_qdotLeftFFUnsat 0;
BA_ "Confidence" SG_ 691 VCRIGHT_qdotRightFFUnsat 0;
BA_ "Confidence" SG_ 691 VCRIGHT_nvhLevelDb 0;
BA_ "Confidence" SG_ 691 VCRIGHT_hvacSetTempActualLeft 0;
BA_ "Confidence" SG_ 691 VCRIGHT_hvacSetTempActualRight 0;
BA_ "Confidence" SG_ 691 VCRIGHT_hvacAutoTransitionReason 0;
BA_ "Confidence" SG_ 691 VCRIGHT_hvacMassflowTarget 0;
BA_ "Confidence" SG_ 691 VCRIGHT_hvacQdotLimitedLeft 0;
BA_ "Confidence" SG_ 691 VCRIGHT_hvacQdotLimitedRight 0;
BA_ "Confidence" SG_ 691 VCRIGHT_LHPanelAirflowBlocked 0;
BA_ "Confidence" SG_ 691 VCRIGHT_RHPanelAirflowBlocked 0;
BA_ "Confidence" SG_ 691 VCRIGHT_floorAirflowBlocked 0;
BA_ "Confidence" SG_ 691 VCRIGHT_defrostAirflowBlocked 0;
BA_ "Confidence" SG_ 691 VCRIGHT_hvacFilterLifeDetectActi 0;
BA_ "SystemSignalLongSymbol" SG_ 691 VCRIGHT_hvacFilterLifeDetectActi "VCRIGHT_hvacFilterLifeDetectActive";
BA_ "Confidence" SG_ 691 VCRIGHT_hvacLHBleedOperationMode 0;
BA_ "Confidence" SG_ 691 VCRIGHT_hvacRHBleedOperationMode 0;
BA_ "Confidence" SG_ 691 VCRIGHT_hvacLHVaneOperationMode 0;
BA_ "Confidence" SG_ 691 VCRIGHT_hvacRHVaneOperationMode 0;
BA_ "Confidence" SG_ 691 VCRIGHT_hvacUpperModeOpMode 0;
BA_ "Confidence" SG_ 691 VCRIGHT_hvacLowerModeOpMode 0;
BA_ "Confidence" SG_ 691 VCRIGHT_hvacIntakeOperationMode 0;
BA_ "Confidence" SG_ 691 VCRIGHT_hvacRearOperationMode 0;
BA_ "Confidence" SG_ 691 VCRIGHT_isProbeFeedbackApplied 0;
BA_ "Confidence" SG_ 691 VCRIGHT_feedbackPullDownScalar 0;
BA_ "Confidence" SG_ 691 VCRIGHT_feedForwardPullDownScala 0;
BA_ "SystemSignalLongSymbol" SG_ 691 VCRIGHT_feedForwardPullDownScala "VCRIGHT_feedForwardPullDownScalar";
BA_ "Confidence" SG_ 691 VCRIGHT_convectionTargetLeft 0;
BA_ "GenSigSNA" SG_ 691 VCRIGHT_convectionTargetLeft "511";
BA_ "Confidence" SG_ 691 VCRIGHT_convectionTargetRight 0;
BA_ "GenSigSNA" SG_ 691 VCRIGHT_convectionTargetRight "511";
BA_ "Confidence" SG_ 691 VCRIGHT_convectionDeliveredLeft 0;
BA_ "GenSigSNA" SG_ 691 VCRIGHT_convectionDeliveredLeft "511";
BA_ "Confidence" SG_ 691 VCRIGHT_convectionDeliveredRight 0;
BA_ "GenSigSNA" SG_ 691 VCRIGHT_convectionDeliveredRight "511";
BA_ "Confidence" SG_ 691 VCRIGHT_solarLoadRightOccupant 0;
BA_ "GenSigSNA" SG_ 691 VCRIGHT_solarLoadRightOccupant "127";
BA_ "Confidence" SG_ 691 VCRIGHT_solarLoadLeftOccupant 0;
BA_ "GenSigSNA" SG_ 691 VCRIGHT_solarLoadLeftOccupant "127";
BA_ "Confidence" SG_ 691 VCRIGHT_ptcShutOutletMitigationA 0;
BA_ "SystemSignalLongSymbol" SG_ 691 VCRIGHT_ptcShutOutletMitigationA "VCRIGHT_ptcShutOutletMitigationActive";
BA_ "Confidence" SG_ 691 VCRIGHT_solarLoadFromThsTemp 0;
BA_ "GenSigSNA" SG_ 691 VCRIGHT_solarLoadFromThsTemp "255";
BA_ "Confidence" SG_ 691 VCRIGHT_hvacFoggingRiskLeve_0003 0;
BA_ "SystemSignalLongSymbol" SG_ 691 VCRIGHT_hvacFoggingRiskLeve_0003 "VCRIGHT_hvacFoggingRiskLevelFeedforwardConservativeEst";
BA_ "Confidence" SG_ 691 VCRIGHT_hvacFoggingRiskLeve_0004 0;
BA_ "SystemSignalLongSymbol" SG_ 691 VCRIGHT_hvacFoggingRiskLeve_0004 "VCRIGHT_hvacFoggingRiskLevelFeedforwardConservativeTar";
BA_ "Confidence" SG_ 691 VCRIGHT_hvacFoggingRiskLeve_0001 0;
BA_ "SystemSignalLongSymbol" SG_ 691 VCRIGHT_hvacFoggingRiskLeve_0001 "VCRIGHT_hvacFoggingRiskLevelConservativeTar";
BA_ "Confidence" SG_ 691 VCRIGHT_ptcHeaterTempDuctHigh 0;
BA_ "Confidence" SG_ 691 VCRIGHT_ptcHeaterTempDuctFault 0;
BA_ "Confidence" SG_ 691 VCRIGHT_ptcHeaterNoAirflow 0;
BA_ "Confidence" SG_ 691 VCRIGHT_ptcHeaterHvacActNotReady 0;
BA_ "Confidence" SG_ 691 VCRIGHT_ptcHeaterNoUiRequest 0;
BA_ "Confidence" SG_ 691 VCRIGHT_ptcHeaterNoHighVoltage 0;
BA_ "Confidence" SG_ 691 VCRIGHT_ptcHeaterLAirPathBlocked 0;
BA_ "Confidence" SG_ 691 VCRIGHT_ptcHeaterRAirPathBlocked 0;
BA_ "Confidence" SG_ 691 VCRIGHT_ptcHeaterReqAirpathBlock 0;
BA_ "SystemSignalLongSymbol" SG_ 691 VCRIGHT_ptcHeaterReqAirpathBlock "VCRIGHT_ptcHeaterReqAirpathBlocked";
BA_ "Confidence" SG_ 691 VCRIGHT_hvacQdotFeedforward 0;
BA_ "Confidence" SG_ 691 VCRIGHT_cabinTempWshldDefog 0;
BA_ "GenSigSNA" SG_ 691 VCRIGHT_cabinTempWshldDefog "255";
BA_ "Confidence" SG_ 691 VCRIGHT_cabinTempWshldDefogTop 0;
BA_ "GenSigSNA" SG_ 691 VCRIGHT_cabinTempWshldDefogTop "255";
BA_ "Confidence" SG_ 691 VCRIGHT_hvacLHBleedVoltage 0;
BA_ "Confidence" SG_ 691 VCRIGHT_hvacRHBleedVoltage 0;
BA_ "Confidence" SG_ 691 VCRIGHT_hvacLHVaneVoltage 0;
BA_ "Confidence" SG_ 691 VCRIGHT_hvacRHVaneVoltage 0;
BA_ "Confidence" SG_ 691 VCRIGHT_hvacUpperModeVoltage 0;
BA_ "Confidence" SG_ 691 VCRIGHT_hvacLowerModeVoltage 0;
BA_ "Confidence" SG_ 691 VCRIGHT_hvacIntakeVoltage 0;
BA_ "Confidence" SG_ 691 VCRIGHT_cabinTempBreathLevelFHea 0;
BA_ "GenSigSNA" SG_ 691 VCRIGHT_cabinTempBreathLevelFHea "255";
BA_ "SystemSignalLongSymbol" SG_ 691 VCRIGHT_cabinTempBreathLevelFHea "VCRIGHT_cabinTempBreathLevelFHeating";
BA_ "Confidence" SG_ 691 VCRIGHT_cabinTempBreathLevelFCoo 0;
BA_ "GenSigSNA" SG_ 691 VCRIGHT_cabinTempBreathLevelFCoo "255";
BA_ "SystemSignalLongSymbol" SG_ 691 VCRIGHT_cabinTempBreathLevelFCoo "VCRIGHT_cabinTempBreathLevelFCooling";
BA_ "Confidence" SG_ 691 VCRIGHT_hvacTorqueMassflowLinear 0;
BA_ "SystemSignalLongSymbol" SG_ 691 VCRIGHT_hvacTorqueMassflowLinear "VCRIGHT_hvacTorqueMassflowLinearFit";
BA_ "Confidence" SG_ 691 VCRIGHT_hvacTorqueMassflowEstima 0;
BA_ "SystemSignalLongSymbol" SG_ 691 VCRIGHT_hvacTorqueMassflowEstima "VCRIGHT_hvacTorqueMassflowEstimateStatus";
BA_ "Confidence" SG_ 691 VCRIGHT_hvacFoggingRiskLevelCons 0;
BA_ "SystemSignalLongSymbol" SG_ 691 VCRIGHT_hvacFoggingRiskLevelCons "VCRIGHT_hvacFoggingRiskLevelConservativeEst";
BA_ "Confidence" SG_ 691 VCRIGHT_hvacWindshieldRHConserva 0;
BA_ "SystemSignalLongSymbol" SG_ 691 VCRIGHT_hvacWindshieldRHConserva "VCRIGHT_hvacWindshieldRHConservativeEst";
BA_ "Confidence" SG_ 691 VCRIGHT_hvacFoggingRiskLevelFeed 0;
BA_ "SystemSignalLongSymbol" SG_ 691 VCRIGHT_hvacFoggingRiskLevelFeed "VCRIGHT_hvacFoggingRiskLevelFeedback";
BA_ "Confidence" SG_ 691 VCRIGHT_hvacFoggingRiskLevelInte 0;
BA_ "SystemSignalLongSymbol" SG_ 691 VCRIGHT_hvacFoggingRiskLevelInte "VCRIGHT_hvacFoggingRiskLevelIntegral";
BA_ "Confidence" SG_ 691 VCRIGHT_hvacFoggingRiskLeve_0002 0;
BA_ "SystemSignalLongSymbol" SG_ 691 VCRIGHT_hvacFoggingRiskLeve_0002 "VCRIGHT_hvacFoggingRiskLevelFeedforward";
BA_ "Confidence" SG_ 691 VCRIGHT_hvacCabOvrheatProtActive 0;
BA_ "Confidence" SG_ 691 VCRIGHT_hvacCabinPurgeAllowed 0;
BA_ "Confidence" SG_ 691 VCRIGHT_hvacCabOvrheatProtAllowe 0;
BA_ "SystemSignalLongSymbol" SG_ 691 VCRIGHT_hvacCabOvrheatProtAllowe "VCRIGHT_hvacCabOvrheatProtAllowed";
BA_ "Confidence" SG_ 691 VCRIGHT_AP_humidityModelBasedCab 0;
BA_ "GenSigSNA" SG_ 691 VCRIGHT_AP_humidityModelBasedCab "1023";
BA_ "SystemSignalLongSymbol" SG_ 691 VCRIGHT_AP_humidityModelBasedCab "VCRIGHT_AP_humidityModelBasedCabinWaterMass";
BA_ "Confidence" SG_ 691 VCRIGHT_cabinTempFanCurrent 0;
BA_ "Confidence" SG_ 691 VCRIGHT_cabinTempFanOutput 0;
BA_ "Confidence" SG_ 691 VCRIGHT_cloudinessEstimatedPct 0;
BA_ "Confidence" SG_ 691 VCRIGHT_solarLoadOnVehFiltered 0;
BA_ "GenSigSNA" SG_ 691 VCRIGHT_solarLoadOnVehFiltered "255";
BA_ "Confidence" SG_ 691 VCRIGHT_cabinTempProbeEstimate 0;
BA_ "GenSigSNA" SG_ 691 VCRIGHT_cabinTempProbeEstimate "255";
BA_ "Confidence" SG_ 691 VCRIGHT_cabinTempThs 0;
BA_ "GenSigSNA" SG_ 691 VCRIGHT_cabinTempThs "255";
BA_ "Confidence" SG_ 691 VCRIGHT_cabinTempThsBracket 0;
BA_ "GenSigSNA" SG_ 691 VCRIGHT_cabinTempThsBracket "255";
BA_ "Confidence" SG_ 691 VCRIGHT_leftHeatOvertempProtect 0;
BA_ "Confidence" SG_ 691 VCRIGHT_rightHeatOvertempProtect 0;
BA_ "Confidence" SG_ 691 VCRIGHT_CO2ppm 0;
BA_ "GenSigSNA" SG_ 691 VCRIGHT_CO2ppm "1023";
BA_ "Confidence" SG_ 691 VCRIGHT_timeLeftToCabinModelInit 0;
BA_ "Confidence" SG_ 691 VCRIGHT_hvacEstimateWindshieldRH 0;
BA_ "Confidence" SG_ 691 VCRIGHT_hvacFoggingRiskLevel 0;
BA_ "Confidence" SG_ 691 VCRIGHT_hvacCabinHumidityLevel 0;
BA_ "Confidence" SG_ 691 VCRIGHT_hvacFlashFoggingDetected 0;
BA_ "Confidence" SG_ 691 VCRIGHT_solarSensitivityInfr 0;
BA_ "Confidence" SG_ 691 VCRIGHT_solarSensitivityInfrCorr 0;
BA_ "Confidence" SG_ 691 VCRIGHT_lumbarCurrent 0;
BA_ "Confidence" SG_ 691 VCRIGHT_ocsCurrent 0;
BA_ "Confidence" SG_ 691 VCRIGHT_rcmCurrent 0;
BA_ "Confidence" SG_ 691 VCRIGHT_radioTunerCurrent 0;
BA_ "Confidence" SG_ 691 VCRIGHT_rearOilPumpCurrent 0;
BA_ "Confidence" SG_ 691 VCRIGHT_rearDefrostCurrent 0;
BA_ "Confidence" SG_ 691 VCRIGHT_tailLightCurrent 0;
BA_ "Confidence" SG_ 691 VCRIGHT_turnTailStopLightCurrent 0;
BA_ "Confidence" SG_ 691 VCRIGHT_reverseFogLightsCurrent 0;
BA_ "GenSigSNA" SG_ 691 VCRIGHT_reverseFogLightsCurrent "15";
BA_ "Confidence" SG_ 691 VCRIGHT_stopReverseTurnLightCurr 0;
BA_ "SystemSignalLongSymbol" SG_ 691 VCRIGHT_stopReverseTurnLightCurr "VCRIGHT_stopReverseTurnLightCurrent";
BA_ "Confidence" SG_ 691 VCRIGHT_sideMirrorCurrent 0;
BA_ "Confidence" SG_ 691 VCRIGHT_sideMirrorHeaterCurrent 0;
BA_ "GenSigSNA" SG_ 691 VCRIGHT_sideMirrorHeaterCurrent "31";
BA_ "Confidence" SG_ 691 VCRIGHT_frontSeatHeatCushionPwr 0;
BA_ "Confidence" SG_ 691 VCRIGHT_trunkInteriorLEDCurrent 0;
BA_ "GenSigSNA" SG_ 691 VCRIGHT_trunkInteriorLEDCurrent "15";
BA_ "Confidence" SG_ 691 VCRIGHT_mapPocketLEDsCurrent 0;
BA_ "GenSigSNA" SG_ 691 VCRIGHT_mapPocketLEDsCurrent "15";
BA_ "Confidence" SG_ 691 VCRIGHT_miscEFuseCurrent 0;
BA_ "GenSigSNA" SG_ 691 VCRIGHT_miscEFuseCurrent "31";
BA_ "Confidence" SG_ 691 VCRIGHT_interiorHandleLEDCurrent 0;
BA_ "Confidence" SG_ 691 VCRIGHT_miscInteriorLightsCurren 0;
BA_ "GenSigSNA" SG_ 691 VCRIGHT_miscInteriorLightsCurren "7";
BA_ "SystemSignalLongSymbol" SG_ 691 VCRIGHT_miscInteriorLightsCurren "VCRIGHT_miscInteriorLightsCurrent";
BA_ "Confidence" SG_ 691 VCRIGHT_frontPuddleLEDCurrent 0;
BA_ "GenSigSNA" SG_ 691 VCRIGHT_frontPuddleLEDCurrent "7";
BA_ "Confidence" SG_ 691 VCRIGHT_rearPuddleLEDCurrent 0;
BA_ "GenSigSNA" SG_ 691 VCRIGHT_rearPuddleLEDCurrent "7";
BA_ "Confidence" SG_ 691 VCRIGHT_liftgateShutfaceLEDCurre 0;
BA_ "GenSigSNA" SG_ 691 VCRIGHT_liftgateShutfaceLEDCurre "7";
BA_ "SystemSignalLongSymbol" SG_ 691 VCRIGHT_liftgateShutfaceLEDCurre "VCRIGHT_liftgateShutfaceLEDCurrent";
BA_ "Confidence" SG_ 691 VCRIGHT_3rSeatTOSCurrent 0;
BA_ "GenSigSNA" SG_ 691 VCRIGHT_3rSeatTOSCurrent "15";
BA_ "Confidence" SG_ 691 VCRIGHT_vbatFusedCurrent 0;
BA_ "GenSigSNA" SG_ 691 VCRIGHT_vbatFusedCurrent "15";
BA_ "Confidence" SG_ 691 VCRIGHT_cabinTempGlassGridHeater 0;
BA_ "GenSigSNA" SG_ 691 VCRIGHT_cabinTempGlassGridHeater "255";
BA_ "Confidence" SG_ 691 VCRIGHT_hvacAirflowReasonRight 0;
BA_ "Confidence" SG_ 691 VCRIGHT_hvacAirflowReasonLeft 0;
BA_ "Confidence" SG_ 691 VCRIGHT_hvacMassflowTargetLeft 0;
BA_ "Confidence" SG_ 691 VCRIGHT_hvacMassflowTargetRight 0;
BA_ "Confidence" SG_ 691 VCRIGHT_solarLoadLeftOccupantFil 0;
BA_ "GenSigSNA" SG_ 691 VCRIGHT_solarLoadLeftOccupantFil "127";
BA_ "SystemSignalLongSymbol" SG_ 691 VCRIGHT_solarLoadLeftOccupantFil "VCRIGHT_solarLoadLeftOccupantFilt";
BA_ "Confidence" SG_ 691 VCRIGHT_solarLoadRightOccupantFi 0;
BA_ "GenSigSNA" SG_ 691 VCRIGHT_solarLoadRightOccupantFi "127";
BA_ "SystemSignalLongSymbol" SG_ 691 VCRIGHT_solarLoadRightOccupantFi "VCRIGHT_solarLoadRightOccupantFilt";
BA_ "Confidence" SG_ 691 VCRIGHT_windshieldRHCapped 0;
BA_ "Confidence" SG_ 691 VCRIGHT_feedbackWarmUpScalar 0;
BA_ "Confidence" SG_ 691 VCRIGHT_maxMassflowScalarWarmUp 0;
BA_ "Confidence" SG_ 691 VCRIGHT_feedforwardWarmUpScalar 0;
BA_ "Confidence" SG_ 691 VCRIGHT_frontSeatHeatBackrestPwr 0;
BA_ "Confidence" SG_ 691 VCRIGHT_maxMassflowScalar 0;
BA_ "Confidence" SG_ 691 VCRIGHT_massflowTargetAutoInManu 0;
BA_ "SystemSignalLongSymbol" SG_ 691 VCRIGHT_massflowTargetAutoInManu "VCRIGHT_massflowTargetAutoInManualMode";
BA_ "Confidence" SG_ 691 VCRIGHT_airflowReasonAutoInManua 0;
BA_ "SystemSignalLongSymbol" SG_ 691 VCRIGHT_airflowReasonAutoInManua "VCRIGHT_airflowReasonAutoInManualMode";
BA_ "Confidence" SG_ 691 VCRIGHT_airflowReasonAutoIn_0001 0;
BA_ "SystemSignalLongSymbol" SG_ 691 VCRIGHT_airflowReasonAutoIn_0001 "VCRIGHT_airflowReasonAutoInManualModeLeft";
BA_ "Confidence" SG_ 691 VCRIGHT_airflowReasonAutoIn_0002 0;
BA_ "SystemSignalLongSymbol" SG_ 691 VCRIGHT_airflowReasonAutoIn_0002 "VCRIGHT_airflowReasonAutoInManualModeRight";
BA_ "Confidence" SG_ 691 VCRIGHT_hvacTorqueMassflowQuadra 0;
BA_ "SystemSignalLongSymbol" SG_ 691 VCRIGHT_hvacTorqueMassflowQuadra "VCRIGHT_hvacTorqueMassflowQuadraticFit";
BA_ "Confidence" SG_ 691 VCRIGHT_vocSweatMassSeat 0;
BA_ "GenSigSNA" SG_ 691 VCRIGHT_vocSweatMassSeat "255";
BA_ "Confidence" SG_ 691 VCRIGHT_vocSweatConcentrationAir 0;
BA_ "GenSigSNA" SG_ 691 VCRIGHT_vocSweatConcentrationAir "255";
BA_ "Confidence" SG_ 691 VCRIGHT_hvacBiLevelWhsldRhEst 0;
BA_ "Confidence" SG_ 691 VCRIGHT_steeringWheelSurfaceTemp 0;
BA_ "GenSigSNA" SG_ 691 VCRIGHT_steeringWheelSurfaceTemp "1023";
BA_ "SystemSignalLongSymbol" SG_ 691 VCRIGHT_steeringWheelSurfaceTemp "VCRIGHT_steeringWheelSurfaceTempEst";
BA_ "Confidence" SG_ 691 VCRIGHT_steeringWheelSurfac_0001 0;
BA_ "GenSigSNA" SG_ 691 VCRIGHT_steeringWheelSurfac_0001 "1023";
BA_ "SystemSignalLongSymbol" SG_ 691 VCRIGHT_steeringWheelSurfac_0001 "VCRIGHT_steeringWheelSurfaceTempTgt";
BA_ "Confidence" SG_ 691 VCRIGHT_timeToComfortHeating 0;
BA_ "Confidence" SG_ 691 VCRIGHT_timeToComfortCooling 0;
BA_ "Confidence" SG_ 691 VCRIGHT_cabinWaterMassRaw 0;
BA_ "GenSigSNA" SG_ 691 VCRIGHT_cabinWaterMassRaw "255";
BA_ "Confidence" SG_ 691 VCRIGHT_massflowSingleZoneSplit 0;
BA_ "Confidence" SG_ 691 VCRIGHT_VOCPurgeState 0;
BA_ "Confidence" SG_ 691 VCRIGHT_cameraFoggingMonitorStat 0;
BA_ "SystemSignalLongSymbol" SG_ 691 VCRIGHT_cameraFoggingMonitorStat "VCRIGHT_cameraFoggingMonitorState";
BA_ "Confidence" SG_ 691 VCRIGHT_windWeatherSource 0;
BA_ "Confidence" SG_ 691 VCRIGHT_humidityRatioWeatherSour 0;
BA_ "SystemSignalLongSymbol" SG_ 691 VCRIGHT_humidityRatioWeatherSour "VCRIGHT_humidityRatioWeatherSource";
BA_ "Confidence" SG_ 691 VCRIGHT_cabinOverheatProtectNotR 0;
BA_ "SystemSignalLongSymbol" SG_ 691 VCRIGHT_cabinOverheatProtectNotR "VCRIGHT_cabinOverheatProtectNotRunningReasonRaw";
BA_ "Confidence" SG_ 691 VCRIGHT_hvacIntakeReason 0;
BA_ "Confidence" SG_ 691 VCRIGHT_hvacCabinPurgeActive 0;
BA_ "Confidence" SG_ 691 VCRIGHT_solarAzimuthCarRef 0;
BA_ "GenSigSNA" SG_ 691 VCRIGHT_solarAzimuthCarRef "1025";
BA_ "Confidence" SG_ 691 VCRIGHT_massflowPulldownBias 0;
BA_ "Confidence" SG_ 691 VCRIGHT_evapPulldownBias 0;
BA_ "Confidence" SG_ 691 VCRIGHT_modeledMassflowFresh 0;
BA_ "Confidence" SG_ 691 VCRIGHT_modeledMassflowRecirc 0;
BA_ "Confidence" SG_ 691 VCRIGHT_hvacLimpModeStatus 0;
BA_ "Confidence" SG_ 691 VCRIGHT_hvacEstimatedCameraWinds 0;
BA_ "GenSigSNA" SG_ 691 VCRIGHT_hvacEstimatedCameraWinds "255";
BA_ "SystemSignalLongSymbol" SG_ 691 VCRIGHT_hvacEstimatedCameraWinds "VCRIGHT_hvacEstimatedCameraWindshieldRH";
BA_ "Confidence" SG_ 691 VCRIGHT_hvacRearVoltage 0;
BA_ "Confidence" SG_ 691 VCRIGHT_cabinTempRoofL2 0;
BA_ "GenSigSNA" SG_ 691 VCRIGHT_cabinTempRoofL2 "255";
BA_ "Confidence" SG_ 691 VCRIGHT_cabinTempRoofL3 0;
BA_ "GenSigSNA" SG_ 691 VCRIGHT_cabinTempRoofL3 "255";
BA_ "Confidence" SG_ 691 VCRIGHT_odorRoutineState 0;
BA_ "GenSigSNA" SG_ 691 VCRIGHT_odorRoutineState "7";
BA_ "Confidence" SG_ 691 VCRIGHT_rgbLedFrontCurrent 0;
BA_ "Confidence" SG_ 691 VCRIGHT_rgbLedRearCurrent 0;
BA_ "Confidence" SG_ 691 VCRIGHT_rgbLedFrontOutput 0;
BA_ "Confidence" SG_ 691 VCRIGHT_rgbLedRearOutput 0;
BA_ "Confidence" SG_ 691 VCRIGHT_cameraDefogState 0;
BA_ "Confidence" SG_ 1859 VCRIGHT_systemRecallStatus 0;
BA_ "GenSigSNA" SG_ 1859 VCRIGHT_systemRecallStatus "0";
BA_ "Confidence" SG_ 1859 VCRIGHT_seatRecallStatus 0;
BA_ "GenSigSNA" SG_ 1859 VCRIGHT_seatRecallStatus "0";
BA_ "Confidence" SG_ 1859 VCRIGHT_mirrorRecallStatus 0;
BA_ "GenSigSNA" SG_ 1859 VCRIGHT_mirrorRecallStatus "0";
BA_ "Confidence" SG_ 794 VCRIGHT_frontOccupancyStatus 0;
BA_ "GenSigSNA" SG_ 794 VCRIGHT_frontOccupancyStatus "7";
BA_ "Confidence" SG_ 794 VCRIGHT_frontBuckleStatus 0;
BA_ "Confidence" SG_ 794 VCRIGHT_rearCenterBuckleStatus 0;
BA_ "Confidence" SG_ 794 VCRIGHT_rearRightBuckleStatus 0;
BA_ "Confidence" SG_ 794 VCRIGHT_rearRightOccupancyStatus 0;
BA_ "Confidence" SG_ 794 VCRIGHT_3RowLeftBuckleStatus 0;
BA_ "Confidence" SG_ 794 VCRIGHT_3RowRightBuckleStatus 0;
BA_ "Confidence" SG_ 794 VCRIGHT_3RowLeftOccupancyStatus 0;
BA_ "Confidence" SG_ 794 VCRIGHT_3RowRightOccupancyStatus 0;
BA_ "Confidence" SG_ 794 VCRIGHT_seatTrackPosition 0;
BA_ "GenSigSNA" SG_ 794 VCRIGHT_seatTrackPosition "7";
BA_ "Confidence" SG_ 794 VCRIGHT_occupantClassification 0;
BA_ "GenSigSNA" SG_ 794 VCRIGHT_occupantClassification "7";
BA_ "Confidence" SG_ 794 VCRIGHT_occupantClassificationQF 0;
BA_ "Confidence" SG_ 794 VCRIGHT_classificationEnabled 0;
BA_ "Confidence" SG_ 794 VCRIGHT_classificationEnabledQF 0;
BA_ "Confidence" SG_ 794 VCRIGHT_3RowRightABStatus 0;
BA_ "GenSigSNA" SG_ 794 VCRIGHT_3RowRightABStatus "2";
BA_ "Confidence" SG_ 794 VCRIGHT_restraintStatusCounter 0;
BA_ "Confidence" SG_ 794 VCRIGHT_restraintStatusChecksum 0;
BA_ "Confidence" SG_ 1251 VCRIGHT_seatStatusIndex 1;
BA_ "Confidence" SG_ 1251 VC_AH_1RowRightSeatMovementHealt 0;
BA_ "SystemSignalLongSymbol" SG_ 1251 VC_AH_1RowRightSeatMovementHealt "VC_AH_1RowRightSeatMovementHealth";
BA_ "Confidence" SG_ 1251 VCRIGHT_frontSeatTrackPos 0;
BA_ "Confidence" SG_ 1251 VCRIGHT_frontSeatTrackCurrent 0;
BA_ "Confidence" SG_ 1251 VCRIGHT_frontSeatTrackDuty 0;
BA_ "Confidence" SG_ 1251 VCRIGHT_frontSeatTrackState 0;
BA_ "Confidence" SG_ 1251 VCRIGHT_frontSeatTrackCalibrated 0;
BA_ "Confidence" SG_ 1251 VCRIGHT_frontSeatTrackLog 0;
BA_ "Confidence" SG_ 1251 VCRIGHT_frontSeatTrackBridgeSt 0;
BA_ "Confidence" SG_ 1251 VCRIGHT_frontSeatTrackPercentage 0;
BA_ "Confidence" SG_ 1251 VCRIGHT_frontSeatBackPos 0;
BA_ "Confidence" SG_ 1251 VCRIGHT_frontSeatBackCurrent 0;
BA_ "Confidence" SG_ 1251 VCRIGHT_frontSeatBackDuty 0;
BA_ "Confidence" SG_ 1251 VCRIGHT_frontSeatBackState 0;
BA_ "Confidence" SG_ 1251 VCRIGHT_frontSeatBackCalibrated 0;
BA_ "Confidence" SG_ 1251 VCRIGHT_frontSeatBackLog 0;
BA_ "Confidence" SG_ 1251 VCRIGHT_frontSeatBackBridgeSt 0;
BA_ "Confidence" SG_ 1251 VCRIGHT_frontSeatBackPercentage 0;
BA_ "Confidence" SG_ 1251 VCRIGHT_frontSeatLiftPos 0;
BA_ "Confidence" SG_ 1251 VCRIGHT_frontSeatLiftCurrent 0;
BA_ "Confidence" SG_ 1251 VCRIGHT_frontSeatLiftDuty 0;
BA_ "Confidence" SG_ 1251 VCRIGHT_frontSeatLiftState 0;
BA_ "Confidence" SG_ 1251 VCRIGHT_frontSeatLiftCalibrated 0;
BA_ "Confidence" SG_ 1251 VCRIGHT_frontSeatLiftLog 0;
BA_ "Confidence" SG_ 1251 VCRIGHT_frontSeatLiftBridgeSt 0;
BA_ "Confidence" SG_ 1251 VCRIGHT_frontSeatLiftPercentage 0;
BA_ "Confidence" SG_ 1251 VCRIGHT_frontSeatTiltPos 0;
BA_ "Confidence" SG_ 1251 VCRIGHT_frontSeatTiltCurrent 0;
BA_ "Confidence" SG_ 1251 VCRIGHT_frontSeatTiltDuty 0;
BA_ "Confidence" SG_ 1251 VCRIGHT_frontSeatTiltState 0;
BA_ "Confidence" SG_ 1251 VCRIGHT_frontSeatTiltCalibrated 0;
BA_ "Confidence" SG_ 1251 VCRIGHT_frontSeatTiltLog 0;
BA_ "Confidence" SG_ 1251 VCRIGHT_frontSeatTiltBridgeSt 0;
BA_ "Confidence" SG_ 1251 VCRIGHT_frontSeatTiltPercentage 3;
BA_ "Confidence" SG_ 1251 VCRIGHT_lumbarAState 0;
BA_ "Confidence" SG_ 1251 VCRIGHT_lumbarBState 0;
BA_ "Confidence" SG_ 1251 VCRIGHT_lumbarAPressureHpa 0;
BA_ "Confidence" SG_ 1251 VCRIGHT_lumbarAPressureHpaFilt 0;
BA_ "Confidence" SG_ 1251 VCRIGHT_lumbarBPressureHpa 0;
BA_ "Confidence" SG_ 1251 VCRIGHT_lumbarBPressureHpaFilt 0;
BA_ "Confidence" SG_ 1251 VCRIGHT_lumbarActiveTooLongErr 0;
BA_ "Confidence" SG_ 1251 VCRIGHT_lumbarMaxPErr 0;
BA_ "Confidence" SG_ 1251 VCRIGHT_lumbarOvercurrentErr 0;
BA_ "Confidence" SG_ 1251 VCRIGHT_lumbarMaxOperatingPErr 0;
BA_ "Confidence" SG_ 1251 VCRIGHT_lumbarMinPErr 0;
BA_ "Confidence" SG_ 1251 VCRIGHT_lumbarGeneralErr 0;
BA_ "Confidence" SG_ 1251 VCRIGHT_lumbarDevMaxPumpPressA 0;
BA_ "Confidence" SG_ 1251 VCRIGHT_lumbarDevMaxPumpPressB 0;
BA_ "Confidence" SG_ 1251 VCRIGHT_frontSeatTrackPosReal 0;
BA_ "Confidence" SG_ 1251 VCRIGHT_frontSeatBackPosReal 0;
BA_ "Confidence" SG_ 1251 VCRIGHT_frontSeatLiftPosReal 0;
BA_ "Confidence" SG_ 1251 VCRIGHT_frontSeatTiltPosReal 0;
BA_ "Confidence" SG_ 1251 VCRIGHT_frontSeatThighSuppo_0001 0;
BA_ "SystemSignalLongSymbol" SG_ 1251 VCRIGHT_frontSeatThighSuppo_0001 "VCRIGHT_frontSeatThighSupportPosReal";
BA_ "Confidence" SG_ 1251 VCRIGHT_frontSeatTrackPosOffset 0;
BA_ "Confidence" SG_ 1251 VCRIGHT_frontSeatBackPosOffset 0;
BA_ "Confidence" SG_ 1251 VCRIGHT_frontSeatLiftPosOffset 0;
BA_ "Confidence" SG_ 1251 VCRIGHT_frontSeatTiltPosOffset 0;
BA_ "Confidence" SG_ 1251 VCRIGHT_frontSeatThighSupportPos 0;
BA_ "SystemSignalLongSymbol" SG_ 1251 VCRIGHT_frontSeatThighSupportPos "VCRIGHT_frontSeatThighSupportPosOffset";
BA_ "Confidence" SG_ 1251 VCRIGHT_lumbarAPressurePercentag 0;
BA_ "SystemSignalLongSymbol" SG_ 1251 VCRIGHT_lumbarAPressurePercentag "VCRIGHT_lumbarAPressurePercentage";
BA_ "Confidence" SG_ 1251 VCRIGHT_lumbarBPressurePercentag 0;
BA_ "SystemSignalLongSymbol" SG_ 1251 VCRIGHT_lumbarBPressurePercentag "VCRIGHT_lumbarBPressurePercentage";
BA_ "Confidence" SG_ 739 VCRIGHT_seatStatus2Index 1;
BA_ "Confidence" SG_ 739 VCRIGHT_frontSeatHeatCurrent 0;
BA_ "GenSigSNA" SG_ 739 VCRIGHT_frontSeatHeatCurrent "12";
BA_ "Confidence" SG_ 739 VCRIGHT_frontSeatHeatDuty 0;
BA_ "Confidence" SG_ 739 VCRIGHT_frontSeatHeatTmp 0;
BA_ "Confidence" SG_ 739 VCRIGHT_frontSeatHeatTmpTarget 3;
BA_ "Confidence" SG_ 739 VCRIGHT_frontSeatHeatInhibited 0;
BA_ "Confidence" SG_ 739 VCRIGHT_frontSeatHeatPowered 0;
BA_ "Confidence" SG_ 739 VC_AH_1RowRightSeatHeatVentHealt 0;
BA_ "SystemSignalLongSymbol" SG_ 739 VC_AH_1RowRightSeatHeatVentHealt "VC_AH_1RowRightSeatHeatVentHealth";
BA_ "Confidence" SG_ 739 VCRIGHT_rearLSeatHeatCurrent 0;
BA_ "Confidence" SG_ 739 VCRIGHT_rearLSeatHeatDuty 0;
BA_ "Confidence" SG_ 739 VCRIGHT_rearLSeatHeatTmp 0;
BA_ "Confidence" SG_ 739 VCRIGHT_rearLSeatHeatTmpTarget 0;
BA_ "Confidence" SG_ 739 VCRIGHT_rearLSeatHeatInhibited 0;
BA_ "Confidence" SG_ 739 VCRIGHT_rearLSeatHeatPowered 0;
BA_ "Confidence" SG_ 739 VCRIGHT_rearCSeatHeatCurrent 0;
BA_ "Confidence" SG_ 739 VCRIGHT_rearCSeatHeatDuty 0;
BA_ "Confidence" SG_ 739 VCRIGHT_rearCSeatHeatTmp 0;
BA_ "Confidence" SG_ 739 VCRIGHT_rearCSeatHeatTmpTarget 0;
BA_ "Confidence" SG_ 739 VCRIGHT_rearCSeatHeatInhibited 0;
BA_ "Confidence" SG_ 739 VCRIGHT_rearCSeatHeatPowered 0;
BA_ "Confidence" SG_ 739 VCRIGHT_rearRSeatHeatCurrent 0;
BA_ "Confidence" SG_ 739 VCRIGHT_rearRSeatHeatDuty 0;
BA_ "Confidence" SG_ 739 VCRIGHT_rearRSeatHeatTmp 0;
BA_ "Confidence" SG_ 739 VCRIGHT_rearRSeatHeatTmpTarget 3;
BA_ "Confidence" SG_ 739 VCRIGHT_rearRSeatHeatInhibited 0;
BA_ "Confidence" SG_ 739 VCRIGHT_rearRSeatHeatPowered 0;
BA_ "Confidence" SG_ 739 VCRIGHT_2RowSeatReclineState 0;
BA_ "GenSigSNA" SG_ 739 VCRIGHT_2RowSeatReclineState "15";
BA_ "Confidence" SG_ 739 VCRIGHT_2RowSeatReclineDuty 0;
BA_ "Confidence" SG_ 739 VCRIGHT_2RowSeatReclineCurrent 0;
BA_ "Confidence" SG_ 739 VCRIGHT_2RowSeatReclineCalibrate 0;
BA_ "SystemSignalLongSymbol" SG_ 739 VCRIGHT_2RowSeatReclineCalibrate "VCRIGHT_2RowSeatReclineCalibrated";
BA_ "Confidence" SG_ 739 VCRIGHT_2RowSeatReclinePositionR 0;
BA_ "SystemSignalLongSymbol" SG_ 739 VCRIGHT_2RowSeatReclinePositionR "VCRIGHT_2RowSeatReclinePositionRaw";
BA_ "Confidence" SG_ 739 VCRIGHT_2RowSeatReclineAngle 0;
BA_ "Confidence" SG_ 739 VCRIGHT_2RowSeatReclineAbsPosSwi 0;
BA_ "GenSigSNA" SG_ 739 VCRIGHT_2RowSeatReclineAbsPosSwi "0";
BA_ "SystemSignalLongSymbol" SG_ 739 VCRIGHT_2RowSeatReclineAbsPosSwi "VCRIGHT_2RowSeatReclineAbsPosSwitchState";
BA_ "Confidence" SG_ 739 VCRIGHT_2RowSeatReclinePositionS 0;
BA_ "GenSigSNA" SG_ 739 VCRIGHT_2RowSeatReclinePositionS "4";
BA_ "SystemSignalLongSymbol" SG_ 739 VCRIGHT_2RowSeatReclinePositionS "VCRIGHT_2RowSeatReclinePositionState";
BA_ "Confidence" SG_ 739 VCRIGHT_2RowSeatReclineAdjustmen 0;
BA_ "SystemSignalLongSymbol" SG_ 739 VCRIGHT_2RowSeatReclineAdjustmen "VCRIGHT_2RowSeatReclineAdjustmentAllowed";
BA_ "Confidence" SG_ 739 VCRIGHT_2RowSeatReclineFoldAllow 0;
BA_ "SystemSignalLongSymbol" SG_ 739 VCRIGHT_2RowSeatReclineFoldAllow "VCRIGHT_2RowSeatReclineFoldAllowed";
BA_ "Confidence" SG_ 739 VCRIGHT_2RowSeatReclineUnfoldAll 0;
BA_ "SystemSignalLongSymbol" SG_ 739 VCRIGHT_2RowSeatReclineUnfoldAll "VCRIGHT_2RowSeatReclineUnfoldAllowed";
BA_ "Confidence" SG_ 739 VCRIGHT_2RowSeatReclineNextToggl 0;
BA_ "GenSigSNA" SG_ 739 VCRIGHT_2RowSeatReclineNextToggl "2";
BA_ "SystemSignalLongSymbol" SG_ 739 VCRIGHT_2RowSeatReclineNextToggl "VCRIGHT_2RowSeatReclineNextToggleDirection";
BA_ "Confidence" SG_ 739 VCRIGHT_2RowSeatReclineChoreoBlo 0;
BA_ "SystemSignalLongSymbol" SG_ 739 VCRIGHT_2RowSeatReclineChoreoBlo "VCRIGHT_2RowSeatReclineChoreoBlockedByOccupancy";
BA_ "Confidence" SG_ 739 VCRIGHT_2RowSeat1RClashAvoidance 0;
BA_ "SystemSignalLongSymbol" SG_ 739 VCRIGHT_2RowSeat1RClashAvoidance "VCRIGHT_2RowSeat1RClashAvoidanceBlockedReason";
BA_ "Confidence" SG_ 739 VCRIGHT_2RowSeat1RClashAvoi_0001 0;
BA_ "SystemSignalLongSymbol" SG_ 739 VCRIGHT_2RowSeat1RClashAvoi_0001 "VCRIGHT_2RowSeat1RClashAvoidanceState";
BA_ "Confidence" SG_ 739 VCRIGHT_2RowSeatReclineAbsP_0001 0;
BA_ "SystemSignalLongSymbol" SG_ 739 VCRIGHT_2RowSeatReclineAbsP_0001 "VCRIGHT_2RowSeatReclineAbsPosSwitchTransPoint";
BA_ "Confidence" SG_ 739 VC_AH_2RowRightSeatMovementHealt 0;
BA_ "SystemSignalLongSymbol" SG_ 739 VC_AH_2RowRightSeatMovementHealt "VC_AH_2RowRightSeatMovementHealth";
BA_ "Confidence" SG_ 739 VCRIGHT_3RowSeatReclineState 0;
BA_ "GenSigSNA" SG_ 739 VCRIGHT_3RowSeatReclineState "15";
BA_ "Confidence" SG_ 739 VCRIGHT_3RowSeatReclineDuty 0;
BA_ "Confidence" SG_ 739 VCRIGHT_3RowSeatReclineCurrent 0;
BA_ "Confidence" SG_ 739 VCRIGHT_3RowSeatReclineCalibrate 0;
BA_ "SystemSignalLongSymbol" SG_ 739 VCRIGHT_3RowSeatReclineCalibrate "VCRIGHT_3RowSeatReclineCalibrated";
BA_ "Confidence" SG_ 739 VCRIGHT_3RowSeatReclinePositionR 0;
BA_ "SystemSignalLongSymbol" SG_ 739 VCRIGHT_3RowSeatReclinePositionR "VCRIGHT_3RowSeatReclinePositionRaw";
BA_ "Confidence" SG_ 739 VCRIGHT_3RowSeatReclineAngle 0;
BA_ "Confidence" SG_ 739 VCRIGHT_3RowSeatReclineNextToggl 0;
BA_ "GenSigSNA" SG_ 739 VCRIGHT_3RowSeatReclineNextToggl "2";
BA_ "SystemSignalLongSymbol" SG_ 739 VCRIGHT_3RowSeatReclineNextToggl "VCRIGHT_3RowSeatReclineNextToggleDirection";
BA_ "Confidence" SG_ 739 VCRIGHT_3RRightSeatHeatCurrent 0;
BA_ "Confidence" SG_ 739 VCRIGHT_3RRightSeatHeatDuty 0;
BA_ "Confidence" SG_ 739 VCRIGHT_3RRightSeatHeatTmp 0;
BA_ "Confidence" SG_ 739 VCRIGHT_3RRightSeatHeatTmpTarget 0;
BA_ "Confidence" SG_ 739 VCRIGHT_3RRightSeatHeatInhibited 0;
BA_ "Confidence" SG_ 739 VCRIGHT_3RowSeatReclinePositionS 0;
BA_ "GenSigSNA" SG_ 739 VCRIGHT_3RowSeatReclinePositionS "4";
BA_ "SystemSignalLongSymbol" SG_ 739 VCRIGHT_3RowSeatReclinePositionS "VCRIGHT_3RowSeatReclinePositionState";
BA_ "Confidence" SG_ 739 VCRIGHT_3RowSeatReclineAdjustmen 0;
BA_ "SystemSignalLongSymbol" SG_ 739 VCRIGHT_3RowSeatReclineAdjustmen "VCRIGHT_3RowSeatReclineAdjustmentAllowed";
BA_ "Confidence" SG_ 739 VCRIGHT_3RowSeatReclineFoldAllow 0;
BA_ "SystemSignalLongSymbol" SG_ 739 VCRIGHT_3RowSeatReclineFoldAllow "VCRIGHT_3RowSeatReclineFoldAllowed";
BA_ "Confidence" SG_ 739 VCRIGHT_3RowSeatReclineUnfoldAll 0;
BA_ "SystemSignalLongSymbol" SG_ 739 VCRIGHT_3RowSeatReclineUnfoldAll "VCRIGHT_3RowSeatReclineUnfoldAllowed";
BA_ "Confidence" SG_ 739 VCRIGHT_3RowSeatReclineChoreoBlo 0;
BA_ "SystemSignalLongSymbol" SG_ 739 VCRIGHT_3RowSeatReclineChoreoBlo "VCRIGHT_3RowSeatReclineChoreoBlockedByOccupancy";
BA_ "Confidence" SG_ 739 VCRIGHT_3RowSeatReclineAbsPosSwi 0;
BA_ "GenSigSNA" SG_ 739 VCRIGHT_3RowSeatReclineAbsPosSwi "0";
BA_ "SystemSignalLongSymbol" SG_ 739 VCRIGHT_3RowSeatReclineAbsPosSwi "VCRIGHT_3RowSeatReclineAbsPosSwitchState";
BA_ "Confidence" SG_ 835 VCRIGHT_autonomyBehaviorStatus 0;
BA_ "Confidence" SG_ 835 VCRIGHT_LVBatteryTypeDBG 0;
BA_ "Confidence" SG_ 835 VCRIGHT_rearDefrostState 0;
BA_ "GenSigSNA" SG_ 835 VCRIGHT_rearDefrostState "0";
BA_ "Confidence" SG_ 835 VCRIGHT_mirrorHeatState 0;
BA_ "GenSigSNA" SG_ 835 VCRIGHT_mirrorHeatState "0";
BA_ "Confidence" SG_ 835 VCRIGHT_OTAState 0;
BA_ "Confidence" SG_ 835 VCRIGHT_5AVoltage 0;
BA_ "Confidence" SG_ 835 VCRIGHT_vbatProt 0;
BA_ "Confidence" SG_ 835 VCRIGHT_rationalityAggregateCurr 0;
BA_ "SystemSignalLongSymbol" SG_ 835 VCRIGHT_rationalityAggregateCurr "VCRIGHT_rationalityAggregateCurrent";
BA_ "Confidence" SG_ 835 VCRIGHT_eFuseMgmtVoltageMonitor 0;
BA_ "Confidence" SG_ 835 VCRIGHT_isSteeringWheelHeaterReq 0;
BA_ "Confidence" SG_ 835 VCRIGHT_steeringWheelHeaterDCTgt 0;
BA_ "GenSigSNA" SG_ 835 VCRIGHT_steeringWheelHeaterDCTgt "127";
VAL_ 524 VCRIGHT_tempEvaporator 2047 "SNA" ;
VAL_ 524 VCRIGHT_tempEvaporatorTarget 255 "SNA" ;
VAL_ 524 VCRIGHT_tempAmbientRaw 0 "SNA" ;
VAL_ 524 VCRIGHT_hvacPerfTestState 2 "BLOWING" 1 "WAITING" 0 "STOPPED" ;
VAL_ 579 VCRIGHT_hvacStatusIndex 5 "MISC3" 4 "MISC2" 3 "MISC" 2 "VCFRONT2" 1 "VCFRONT" 0 "UI" ;
VAL_ 579 VCRIGHT_childModeHVACState 2 "ACTIVE_COMPROMISED" 1 "ACTIVE" 0 "IDLE" ;
VAL_ 579 VCRIGHT_dogModeState 15 "DOG_MODE_INVALID" 6 "DOG_MODE_RUNNING_TEMP_MONITOR_TRIP" 5 "DOG_MODE_RUNNING_DEVICE_OR_MODEL_FAULT" 4 "DOG_MODE_RUNNING" 3 "DOG_MODE_AVAILABLE" 2 "DOG_MODE_INITIALIZING" 1 "DOG_MODE_UNAVAILABLE_CABIN_TOO_HOT" 0 "DOG_MODE_UNAVAILABLE_MODEL_DEVICE_FAULT" ;
VAL_ 579 VCRIGHT_COPNotRunningReasonFilte 7 "CABIN_BELOW_THRESHOLD" 6 "WAITING" 5 "LOW_SOLAR_LOAD" 4 "TIMEOUT" 3 "ENERGY_CONSUMPTION_LIMIT" 2 "USER_INTERACTION" 1 "DISABLED" 0 "NONE" ;
VAL_ 579 VCRIGHT_hvacAirDistributionMode 7 "DEFROST_PANEL_FLOOR" 6 "DEFROST_PANEL" 5 "DEFROST_FLOOR" 4 "DEFROST" 3 "PANEL_FLOOR" 2 "PANEL" 1 "FLOOR" 0 "NONE" ;
VAL_ 579 VCRIGHT_hvacBlowerSegment 11 "11" 10 "10" 9 "9" 8 "8" 7 "7" 6 "6" 5 "5" 4 "4" 3 "3" 2 "2" 1 "1" 0 "OFF" ;
VAL_ 579 VCRIGHT_hvacRecirc 2 "FRESH" 1 "RECIRC" 0 "AUTO" ;
VAL_ 579 VCRIGHT_hvacACRunning 1 "ON" 0 "OFF" ;
VAL_ 579 VCRIGHT_hvacPowerState 4 "OVERHEAT_PROTECT" 3 "OVERHEAT_PROTECT_FANONLY" 2 "PRECONDITION" 1 "ON" 0 "OFF" ;
VAL_ 579 VCRIGHT_hvacVentStatus 3 "OFF" 2 "RIGHT" 1 "LEFT" 0 "BOTH" ;
VAL_ 579 VCRIGHT_hvacSecondRowState 4 "HIGH" 3 "MED" 2 "LOW" 1 "OFF" 0 "AUTO" ;
VAL_ 579 VCRIGHT_hvacModelInitStatus 9 "NOT_INIT_CAMERA_POCKET_BEING_INITIALIZED" 8 "INIT_FORWARD_CALC_LIMP" 7 "INIT_FROM_SENSORS_PREDICTION_ERROR_LIMP" 6 "INIT_FROM_SENSORS_LIMP" 5 "INIT_WAITING_FOR_SENSORS" 4 "INIT_FORWARD_CALC" 3 "INIT_FROM_SENSORS_PREDICTION_ERROR" 2 "INIT_FROM_SENSORS" 1 "NOT_INIT_WAIT_FOR_GTW" 0 "NOT_INIT_WAIT_FOR_SENSORS" ;
VAL_ 579 VCRIGHT_tempDuctLeft 255 "SNA" ;
VAL_ 579 VCRIGHT_tempDuctRight 255 "SNA" ;
VAL_ 579 VCRIGHT_hvacDuctTargetLeft 255 "SNA" ;
VAL_ 579 VCRIGHT_hvacDuctTargetRight 255 "SNA" ;
VAL_ 579 VCRIGHT_tempDuctRightUpper 255 "SNA" ;
VAL_ 579 VCRIGHT_hvacEvapInletTempEstimat 1023 "SNA" ;
VAL_ 579 VCRIGHT_hvacAirflowReason 21 "NONE" 20 "ODOR_ROUTINE" 19 "DRIVERLESS_SELF_TEST" 18 "VOC_PURGE" 17 "STRATIFICATION_TOP_PAD_AREA" 16 "HOT_DUCT_LOCKOUT" 15 "COLD_DUCT_LOCKOUT" 14 "BIOWEAPON_DEFENSE" 13 "EVAP_OIL_PURGE" 12 "EVAP_DRYING" 11 "SCREEN_PROTECTION" 10 "CABIN_OVERHEAT_PROTECT" 9 "CABIN_PURGE" 8 "OUTLET_TEMP_LIMIT" 7 "OCCUPANT_CONVECTION_REQUIREMENT" 6 "STRATIFICATION_INTERIOR_SURFACES" 5 "STRATIFICATION_GLASS_ROOF" 4 "MINIMUM_AUTO_AIRFLOW" 3 "CABIN_TEMPERATURE_CONTROL" 2 "UI_SHORTCUT" 1 "MANUAL_FAN_SPEED" 0 "HVAC_OFF" ;
VAL_ 579 VCRIGHT_solarLoadOnVehicle 255 "SNA" ;
VAL_ 579 VCRIGHT_hvacFrontRightSeatFanSta 3 "FAN_REQUEST_LEVEL3" 2 "FAN_REQUEST_LEVEL2" 1 "FAN_REQUEST_LEVEL1" 0 "FAN_REQUEST_OFF" ;
VAL_ 579 VCRIGHT_hvacFrontLeftSeatFanStat 3 "FAN_REQUEST_LEVEL3" 2 "FAN_REQUEST_LEVEL2" 1 "FAN_REQUEST_LEVEL1" 0 "FAN_REQUEST_OFF" ;
VAL_ 579 VCRIGHT_extendedHvacPerfTestSupp 10 "STOP" 9 "COUNT" 8 "8_CABIN_PURGE" 7 "7_BATTERY_COOL" 6 "6_BATTERY_HEAT_COP1" 5 "5_CABIN_HEAT_COP1" 4 "4_CABIN_COOL" 3 "3_SPLIT_REHEAT_COOL_DOMINANT" 2 "2_BATT_HEAT_CABIN_REHEAT_AS" 1 "1_CABIN_HEAT_AS" 0 "INIT" ;
VAL_ 579 VCRIGHT_hvacFrontRightSeatHeatSt 3 "HEATER_REQUEST_LEVEL3" 2 "HEATER_REQUEST_LEVEL2" 1 "HEATER_REQUEST_LEVEL1" 0 "HEATER_REQUEST_OFF" ;
VAL_ 579 VCRIGHT_hvacSeatFrontLeftTempTar 0 "OFF" ;
VAL_ 579 VCRIGHT_hvacManualToAutoNotify 6 "MISC3" 5 "MISC2" 4 "COMFORT_FORWARD_LOOK" 3 "FOGGING_COMFORT" 2 "FOGGING" 1 "COMFORT" 0 "OFF" ;
VAL_ 579 VCRIGHT_hvacRequestsFullAuto 7 "MISC4" 6 "MISC3" 5 "MISC2" 4 "MISC1" 3 "HVAC_OFF_FOGGING_RISK" 2 "MANUAL_HVAC_HIGH_FOGGING_RISK" 1 "HIGH_BLOWER_SPEED" 0 "NOT_ALLOWED" ;
VAL_ 579 VCRIGHT_steeringWheelHeatStatus 3 "STEERING_WHEEL_HEAT_LEVEL3" 2 "STEERING_WHEEL_HEAT_LEVEL2" 1 "STEERING_WHEEL_HEAT_LEVEL1" 0 "STEERING_WHEEL_HEAT_OFF" ;
VAL_ 579 VCRIGHT_autoDefogStatus 2 "INTERMEDIATE_DEFOG" 1 "DEFOG" 0 "NONE" ;
VAL_ 579 VCRIGHT_solarElevation -256 "SNA" ;
VAL_ 579 VCRIGHT_minsToSunrise 255 "SNA" ;
VAL_ 579 VCRIGHT_minsToSunset 255 "SNA" ;
VAL_ 579 VCRIGHT_hvacLimitedReasonRight 7 "HVAC_LIMITING_MANUAL_BLOWER" 6 "HVAC_LIMITING_CDL_AND_QDLH" 5 "HVAC_LIMITING_HDL_AND_QDLC" 4 "HVAC_LIMITING_QDOT_LIMITED_HEATING" 3 "HVAC_LIMITING_QDOT_LIMITED_COOLING" 2 "HVAC_LIMITING_COLD_DUCT_LOCKOUT" 1 "HVAC_LIMITING_HOT_DUCT_LOCKOUT" 0 "HVAC_LIMITING_NONE" ;
VAL_ 579 VCRIGHT_hvacLimitedReasonLeft 7 "HVAC_LIMITING_MANUAL_BLOWER" 6 "HVAC_LIMITING_CDL_AND_QDLH" 5 "HVAC_LIMITING_HDL_AND_QDLC" 4 "HVAC_LIMITING_QDOT_LIMITED_HEATING" 3 "HVAC_LIMITING_QDOT_LIMITED_COOLING" 2 "HVAC_LIMITING_COLD_DUCT_LOCKOUT" 1 "HVAC_LIMITING_HOT_DUCT_LOCKOUT" 0 "HVAC_LIMITING_NONE" ;
VAL_ 579 VCRIGHT_tempDuctLeftUpper 255 "SNA" ;
VAL_ 579 VCRIGHT_hvacFrontLeftSeatHeatSta 3 "HEATER_REQUEST_LEVEL3" 2 "HEATER_REQUEST_LEVEL2" 1 "HEATER_REQUEST_LEVEL1" 0 "HEATER_REQUEST_OFF" ;
VAL_ 579 VCRIGHT_tempDuctLeftLower 255 "SNA" ;
VAL_ 579 VCRIGHT_tempDuctRightLower 255 "SNA" ;
VAL_ 771 VCRIGHT_infoIndex 255 "END" 41 "SUBCOMPONENT14" 40 "SUBCOMPONENT13" 39 "SUBCOMPONENT12" 38 "SUBCOMPONENT11" 37 "SUBCOMPONENT10" 36 "SUBCOMPONENT9" 35 "SUBCOMPONENT8" 34 "SUBCOMPONENT7" 33 "SUBCOMPONENT6" 32 "SUBCOMPONENT5" 31 "SUBCOMPONENT4" 24 "SUBCOMPONENT3" 23 "SUBCOMPONENT2" 20 "UDS_PROTOCOL_BOOTCRC" 19 "VERSION_DEPRECATED" 18 "BOOTLOADER_GITHASH" 17 "APP_GITHASH" 16 "SUBCOMPONENT1" 15 "BOOTLOADER_CRC" 14 "BOOTLOADER_SVN" 13 "APP_CRC" 11 "PCBAID_ASSYID_USAGEID" 10 "BUILD_HWID_COMPONENTID" 9 "DEPRECATED_9" 8 "DEPRECATED_8" 7 "DEPRECATED_7" 6 "DEPRECATED_6" 5 "DEPRECATED_5" 4 "DEPRECATED_4" 3 "DEPRECATED_3" 2 "DEPRECATED_2" 1 "DEPRECATED_1" 0 "DEPRECATED_0" ;
VAL_ 771 VCRIGHT_infoBuildType 4 "INFO_MFG_BUILD" 3 "INFO_TRACEABLE_CI_BUILD" 2 "INFO_LOCAL_BUILD" 1 "INFO_PLATFORM_BUILD" 0 "INFO_UNKNOWN_BUILD" ;
VAL_ 771 VCRIGHT_infoAssemblyId 255 "ASSEMBLY_SNA" 1 "ASSEMBLY1" ;
VAL_ 995 VCRIGHT_brakeLightStatus 3 "LIGHT_SNA" 2 "LIGHT_FAULT" 1 "LIGHT_ON" 0 "LIGHT_OFF" ;
VAL_ 995 VCRIGHT_tailLightStatus 3 "LIGHT_SNA" 2 "LIGHT_FAULT" 1 "LIGHT_ON" 0 "LIGHT_OFF" ;
VAL_ 995 VCRIGHT_turnSignalStatus 3 "LIGHT_SNA" 2 "LIGHT_FAULT" 1 "LIGHT_ON" 0 "LIGHT_OFF" ;
VAL_ 995 VCRIGHT_reverseLightStatus 3 "LIGHT_SNA" 2 "LIGHT_FAULT" 1 "LIGHT_ON" 0 "LIGHT_OFF" ;
VAL_ 995 VCRIGHT_rearFogLightStatus 3 "LIGHT_SNA" 2 "LIGHT_FAULT" 1 "LIGHT_ON" 0 "LIGHT_OFF" ;
VAL_ 995 VCRIGHT_fasciaReverseLightStatus 3 "LIGHT_SNA" 2 "LIGHT_FAULT" 1 "LIGHT_ON" 0 "LIGHT_OFF" ;
VAL_ 995 VCRIGHT_fasciaRearFogStatus 3 "LIGHT_SNA" 2 "LIGHT_FAULT" 1 "LIGHT_ON" 0 "LIGHT_OFF" ;
VAL_ 995 VCRIGHT_fasciaTailLightStatus 3 "LIGHT_SNA" 2 "LIGHT_FAULT" 1 "LIGHT_ON" 0 "LIGHT_OFF" ;
VAL_ 995 VCRIGHT_fasciaLeftTurnSignalStat 3 "LIGHT_SNA" 2 "LIGHT_FAULT" 1 "LIGHT_ON" 0 "LIGHT_OFF" ;
VAL_ 995 VCRIGHT_fasciaRightTurnSignalSta 3 "LIGHT_SNA" 2 "LIGHT_FAULT" 1 "LIGHT_ON" 0 "LIGHT_OFF" ;
VAL_ 995 VCRIGHT_CHMSLLightStatus 3 "LIGHT_SNA" 2 "LIGHT_FAULT" 1 "LIGHT_ON" 0 "LIGHT_OFF" ;
VAL_ 1803 VCRIGHT_logging0point1HzIndex 10 "END" 9 "HVAC_5" 8 "HVAC_4" 7 "HVAC_3" 6 "HVAC_2" 5 "LIGHT_CURRENTS_2" 4 "HVAC_ACTUATOR_ZEROSTOP" 3 "HVAC_ACTUATOR_ENDSTOP" 2 "HVAC" 1 "LIGHT_CURRENTS_1" 0 "LIGHT_CURRENTS_0" ;
VAL_ 1803 VCRIGHT_leftPTCCompromisedRod 7 "CENTER_INNER" 6 "OUTER_CENTER" 5 "OUTER_INNER" 4 "OUTER" 3 "CENTER" 2 "INNER" 1 "ALL" 0 "NONE" ;
VAL_ 1803 VCRIGHT_rightPTCCompromisedRod 7 "CENTER_INNER" 6 "OUTER_CENTER" 5 "OUTER_INNER" 4 "OUTER" 3 "CENTER" 2 "INNER" 1 "ALL" 0 "NONE" ;
VAL_ 1803 VCRIGHT_cabinTempBreathLevelFOff 255 "SNA" ;
VAL_ 1803 VCRIGHT_averageDuctTempFCooling 255 "SNA" ;
VAL_ 1803 VCRIGHT_fasciaTailLeftLightCurre 511 "SNA" ;
VAL_ 1803 VCRIGHT_fasciaTailLeftLight_0001 4 "FALLING_EDGE_TRANSIENT" 3 "STEADY_STATE_ON" 2 "RISING_EDGE_TRANSIENT" 1 "STEADY_STATE_OFF" 0 "SNA" ;
VAL_ 1803 VCRIGHT_fasciaTailRightLightCurr 511 "SNA" ;
VAL_ 1803 VCRIGHT_fasciaTailRightLigh_0001 4 "FALLING_EDGE_TRANSIENT" 3 "STEADY_STATE_ON" 2 "RISING_EDGE_TRANSIENT" 1 "STEADY_STATE_OFF" 0 "SNA" ;
VAL_ 1803 VCRIGHT_liftgateTailLeftLightCur 511 "SNA" ;
VAL_ 1803 VCRIGHT_liftgateTailLeftLig_0001 4 "FALLING_EDGE_TRANSIENT" 3 "STEADY_STATE_ON" 2 "RISING_EDGE_TRANSIENT" 1 "STEADY_STATE_OFF" 0 "SNA" ;
VAL_ 1803 VCRIGHT_liftgateTailRightLightCu 4 "FALLING_EDGE_TRANSIENT" 3 "STEADY_STATE_ON" 2 "RISING_EDGE_TRANSIENT" 1 "STEADY_STATE_OFF" 0 "SNA" ;
VAL_ 1803 VCRIGHT_ambientTempLimp 255 "SNA" ;
VAL_ 1803 VCRIGHT_cabinProbeTempLimp 255 "SNA" ;
VAL_ 1803 VCRIGHT_thsTempLimp 255 "SNA" ;
VAL_ 1803 VCRIGHT_thsSolarIrradianceLimp 255 "SNA" ;
VAL_ 1803 VCRIGHT_interiorCameraLedCurrent 255 "SNA" ;
VAL_ 1803 VCRIGHT_tempIncarCabinDeep 255 "SNA" ;
VAL_ 1803 VCRIGHT_cabinTempBreathLeve_0001 255 "SNA" ;
VAL_ 1803 VCRIGHT_cabinTempBreathLevelF10m 255 "SNA" ;
VAL_ 1803 VCRIGHT_cabinTempBreathLeve_0002 255 "SNA" ;
VAL_ 1803 VCRIGHT_cabinTempBreathLevelF5mi 255 "SNA" ;
VAL_ 1803 VCRIGHT_cabinTempInteriorFHeatin 255 "SNA" ;
VAL_ 1803 VCRIGHT_cabinTempInteriorFCoolin 255 "SNA" ;
VAL_ 1803 VCRIGHT_filterLifeBlowerTorque 1023 "SNA" ;
VAL_ 1803 VCRIGHT_averageDuctTempFHeating 255 "SNA" ;
VAL_ 1803 VCRIGHT_thsSolarSensorType 2 "OPT4003" 1 "ISL76683" 0 "UNKNOWN" ;
VAL_ 1803 VCRIGHT_thsTempSensorType 2 "SHT41" 1 "SHT31" 0 "UNKNOWN" ;
VAL_ 611 VCRIGHT_logging10HzIndex 5 "END" 4 "HVAC_ACTUATOR_BRUSHED_DUTY" 3 "HVAC_ACTUATOR_BRUSHED" 2 "HVAC_ACTUATOR_STATE" 1 "HVAC_ACTUATOR_POSITIONS" 0 "HVAC_ACTUATOR_TARGETS" ;
VAL_ 611 VCRIGHT_hvacLHBleedActuatorState 2 "HVACACTUATOR_STATE_COASTING" 1 "HVACACTUATOR_STATE_RUNNING" 0 "HVACACTUATOR_STATE_BRAKING" ;
VAL_ 611 VCRIGHT_hvacRHBleedActuatorState 2 "HVACACTUATOR_STATE_COASTING" 1 "HVACACTUATOR_STATE_RUNNING" 0 "HVACACTUATOR_STATE_BRAKING" ;
VAL_ 611 VCRIGHT_hvacLHVaneActuatorState 2 "HVACACTUATOR_STATE_COASTING" 1 "HVACACTUATOR_STATE_RUNNING" 0 "HVACACTUATOR_STATE_BRAKING" ;
VAL_ 611 VCRIGHT_hvacRHVaneActuatorState 2 "HVACACTUATOR_STATE_COASTING" 1 "HVACACTUATOR_STATE_RUNNING" 0 "HVACACTUATOR_STATE_BRAKING" ;
VAL_ 611 VCRIGHT_hvacUpperModeActState 2 "HVACACTUATOR_STATE_COASTING" 1 "HVACACTUATOR_STATE_RUNNING" 0 "HVACACTUATOR_STATE_BRAKING" ;
VAL_ 611 VCRIGHT_hvacLowerModeActState 2 "HVACACTUATOR_STATE_COASTING" 1 "HVACACTUATOR_STATE_RUNNING" 0 "HVACACTUATOR_STATE_BRAKING" ;
VAL_ 611 VCRIGHT_hvacIntakeActuatorState 2 "HVACACTUATOR_STATE_COASTING" 1 "HVACACTUATOR_STATE_RUNNING" 0 "HVACACTUATOR_STATE_BRAKING" ;
VAL_ 611 VCRIGHT_hvacRearActuatorState 2 "HVACACTUATOR_STATE_COASTING" 1 "HVACACTUATOR_STATE_RUNNING" 0 "HVACACTUATOR_STATE_BRAKING" ;
VAL_ 611 VCRIGHT_tempDatLeftEst 255 "SNA" ;
VAL_ 611 VCRIGHT_tempDatRightEst 255 "SNA" ;
VAL_ 611 VCRIGHT_tempDuctLeftEst 255 "SNA" ;
VAL_ 611 VCRIGHT_tempDuctRightEst 255 "SNA" ;
VAL_ 611 VCRIGHT_ptcHeaterBadRodDetection 11 "UNAVAILABLE" 10 "CLEAR_FAULT_RESTART" 9 "CLEAR_FAULT" 8 "CHECK_RIGHT_INNER" 7 "CHECK_RIGHT_CENTER" 6 "CHECK_RIGHT_OUTER" 5 "CHECK_LEFT_INNER" 4 "CHECK_LEFT_CENTER" 3 "CHECK_LEFT_OUTER" 2 "DETECTED" 1 "IDLE" 0 "INIT" ;
VAL_ 611 VCRIGHT_upperModeDrvActuatorStat 11 "HVAC_ACTUATOR_BRUSHED_STATE_RUNNING_OVERSHOOT" 10 "HVAC_ACTUATOR_BRUSHED_STATE_NEGATIVE_BACKOFF" 9 "HVAC_ACTUATOR_BRUSHED_STATE_POSITIVE_BACKOFF" 8 "HVAC_ACTUATOR_BRUSHED_STATE_CONTROL_DISABLED" 7 "HVAC_ACTUATOR_BRUSHED_STATE_FAULT" 6 "HVAC_ACTUATOR_BRUSHED_STATE_BRAKING" 5 "HVAC_ACTUATOR_BRUSHED_STATE_RUNNING" 4 "HVAC_ACTUATOR_BRUSHED_STATE_NEGATIVE_STALL" 3 "HVAC_ACTUATOR_BRUSHED_STATE_NEGATIVE_RUN" 2 "HVAC_ACTUATOR_BRUSHED_STATE_POSITIVE_STALL" 1 "HVAC_ACTUATOR_BRUSHED_STATE_POSITIVE_RUN" 0 "HVAC_ACTUATOR_BRUSHED_STATE_INIT" ;
VAL_ 611 VCRIGHT_leftVerticalActuatorStat 11 "HVAC_ACTUATOR_BRUSHED_STATE_RUNNING_OVERSHOOT" 10 "HVAC_ACTUATOR_BRUSHED_STATE_NEGATIVE_BACKOFF" 9 "HVAC_ACTUATOR_BRUSHED_STATE_POSITIVE_BACKOFF" 8 "HVAC_ACTUATOR_BRUSHED_STATE_CONTROL_DISABLED" 7 "HVAC_ACTUATOR_BRUSHED_STATE_FAULT" 6 "HVAC_ACTUATOR_BRUSHED_STATE_BRAKING" 5 "HVAC_ACTUATOR_BRUSHED_STATE_RUNNING" 4 "HVAC_ACTUATOR_BRUSHED_STATE_NEGATIVE_STALL" 3 "HVAC_ACTUATOR_BRUSHED_STATE_NEGATIVE_RUN" 2 "HVAC_ACTUATOR_BRUSHED_STATE_POSITIVE_STALL" 1 "HVAC_ACTUATOR_BRUSHED_STATE_POSITIVE_RUN" 0 "HVAC_ACTUATOR_BRUSHED_STATE_INIT" ;
VAL_ 611 VCRIGHT_leftLateralActuatorState 11 "HVAC_ACTUATOR_BRUSHED_STATE_RUNNING_OVERSHOOT" 10 "HVAC_ACTUATOR_BRUSHED_STATE_NEGATIVE_BACKOFF" 9 "HVAC_ACTUATOR_BRUSHED_STATE_POSITIVE_BACKOFF" 8 "HVAC_ACTUATOR_BRUSHED_STATE_CONTROL_DISABLED" 7 "HVAC_ACTUATOR_BRUSHED_STATE_FAULT" 6 "HVAC_ACTUATOR_BRUSHED_STATE_BRAKING" 5 "HVAC_ACTUATOR_BRUSHED_STATE_RUNNING" 4 "HVAC_ACTUATOR_BRUSHED_STATE_NEGATIVE_STALL" 3 "HVAC_ACTUATOR_BRUSHED_STATE_NEGATIVE_RUN" 2 "HVAC_ACTUATOR_BRUSHED_STATE_POSITIVE_STALL" 1 "HVAC_ACTUATOR_BRUSHED_STATE_POSITIVE_RUN" 0 "HVAC_ACTUATOR_BRUSHED_STATE_INIT" ;
VAL_ 611 VCRIGHT_rightVerticalActuatorSta 11 "HVAC_ACTUATOR_BRUSHED_STATE_RUNNING_OVERSHOOT" 10 "HVAC_ACTUATOR_BRUSHED_STATE_NEGATIVE_BACKOFF" 9 "HVAC_ACTUATOR_BRUSHED_STATE_POSITIVE_BACKOFF" 8 "HVAC_ACTUATOR_BRUSHED_STATE_CONTROL_DISABLED" 7 "HVAC_ACTUATOR_BRUSHED_STATE_FAULT" 6 "HVAC_ACTUATOR_BRUSHED_STATE_BRAKING" 5 "HVAC_ACTUATOR_BRUSHED_STATE_RUNNING" 4 "HVAC_ACTUATOR_BRUSHED_STATE_NEGATIVE_STALL" 3 "HVAC_ACTUATOR_BRUSHED_STATE_NEGATIVE_RUN" 2 "HVAC_ACTUATOR_BRUSHED_STATE_POSITIVE_STALL" 1 "HVAC_ACTUATOR_BRUSHED_STATE_POSITIVE_RUN" 0 "HVAC_ACTUATOR_BRUSHED_STATE_INIT" ;
VAL_ 611 VCRIGHT_rightLateralActuatorStat 11 "HVAC_ACTUATOR_BRUSHED_STATE_RUNNING_OVERSHOOT" 10 "HVAC_ACTUATOR_BRUSHED_STATE_NEGATIVE_BACKOFF" 9 "HVAC_ACTUATOR_BRUSHED_STATE_POSITIVE_BACKOFF" 8 "HVAC_ACTUATOR_BRUSHED_STATE_CONTROL_DISABLED" 7 "HVAC_ACTUATOR_BRUSHED_STATE_FAULT" 6 "HVAC_ACTUATOR_BRUSHED_STATE_BRAKING" 5 "HVAC_ACTUATOR_BRUSHED_STATE_RUNNING" 4 "HVAC_ACTUATOR_BRUSHED_STATE_NEGATIVE_STALL" 3 "HVAC_ACTUATOR_BRUSHED_STATE_NEGATIVE_RUN" 2 "HVAC_ACTUATOR_BRUSHED_STATE_POSITIVE_STALL" 1 "HVAC_ACTUATOR_BRUSHED_STATE_POSITIVE_RUN" 0 "HVAC_ACTUATOR_BRUSHED_STATE_INIT" ;
VAL_ 611 VCRIGHT_windshieldRHExteriorSurf 255 "SNA" ;
VAL_ 611 VCRIGHT_frontLeftSeatTempTargetQ 0 "OFF" ;
VAL_ 611 VCRIGHT_frontRightSeatTempTarget 0 "OFF" ;
VAL_ 691 VCRIGHT_logging1HzIndex 17 "END" 16 "MISCELLANEOUS_LOGGING" 15 "HVAC_MISCELLANEOUS_3" 14 "STEERING_WHEEL_HEAT" 13 "HVAC_COMFORT_SOLAR_3" 12 "HVAC_COMFORT_SOLAR_2" 11 "HSD_CURRENTS_2" 10 "HSD_CURRENTS_1" 9 "HVAC_MISCELLANEOUS_2" 8 "HVAC_MISCELLANEOUS_1" 7 "HVAC_TEMP_SENSORS_AND_ESTIMATES_3" 6 "HVAC_ACTUATOR_VOLTAGES" 5 "HEATER_AND_DUCT_TARGETS" 4 "HVAC_COMFORT_SOLAR" 3 "HVAC_STATUS_AIRFLOW" 2 "HVAC_HUMIDITY_HEATER_TEMP" 1 "HVAC_TEMP_SENSORS_AND_ESTIMATES_2" 0 "HVAC_TEMP_SENSORS_AND_ESTIMATES_1" ;
VAL_ 691 VCRIGHT_glareShieldHeaterState 4 "FAULT" 3 "INACTIVE" 2 "PASSIVE" 1 "REQUESTED" 0 "IDLE" ;
VAL_ 691 VCRIGHT_tempIncarCabinProbe 255 "SNA" ;
VAL_ 691 VCRIGHT_cabinTempInteriorL2 255 "SNA" ;
VAL_ 691 VCRIGHT_cabinTempInteriorSunnyL2 255 "SNA" ;
VAL_ 691 VCRIGHT_tempIncarCabinMid 250 "SNA" ;
VAL_ 691 VCRIGHT_cabinTempInteriorL3 255 "SNA" ;
VAL_ 691 VCRIGHT_cabinTempInteriorSunnyL3 255 "SNA" ;
VAL_ 691 VCRIGHT_tempWetBulb 255 "SNA" ;
VAL_ 691 VCRIGHT_cabinTempGlassRoof 255 "SNA" ;
VAL_ 691 VCRIGHT_cabinTempWindshield 255 "SNA" ;
VAL_ 691 VCRIGHT_cabinTempInterior 255 "SNA" ;
VAL_ 691 VCRIGHT_cabinTempInteriorSunny 255 "SNA" ;
VAL_ 691 VCRIGHT_cabinTempSideGlassLeft 255 "SNA" ;
VAL_ 691 VCRIGHT_cabinTempSideGlassRight 255 "SNA" ;
VAL_ 691 VCRIGHT_cabinTempBreathLevel 255 "SNA" ;
VAL_ 691 VCRIGHT_hvacAutoTransitionReason 23 "END" 22 "VOC_PURGE" 21 "RETURN_FROM_DEFOG_OVERRIDE" 20 "HVAC_AIR_HUMID" 19 "BIODEFENSE" 18 "DUCT_TARGETS_INVALID" 17 "HVAC_OFF" 16 "EVAP_OIL_PURGE" 15 "EVAP_DRYING" 14 "CABIN_PURGE" 13 "SET_TEMP_HI" 12 "SET_TEMP_LO" 11 "DEFOG_OVERRIDE" 10 "BI_LEVEL_LANDING" 9 "DUCTS_COLD" 8 "TEMP_TARGET_LOW" 7 "OCCUPANT_CONVECTION_REQUIREMENT" 6 "EXCESS_OCCUPANT_CONVECTION" 5 "TEMP_TARGET_ABOVE_THRESHOLD" 4 "TEMP_TARGET_BELOW_THRESHOLD" 3 "HUMIDITY_LOW" 2 "HUMIDITY_MODERATE" 1 "HUMIDITY_HIGH" 0 "NONE" ;
VAL_ 691 VCRIGHT_hvacLHBleedOperationMode 1 "HVACACTUATOR_OPERATION_MODE_CALIBRATION" 0 "HVACACTUATOR_OPERATION_MODE_NORMAL" ;
VAL_ 691 VCRIGHT_hvacRHBleedOperationMode 1 "HVACACTUATOR_OPERATION_MODE_CALIBRATION" 0 "HVACACTUATOR_OPERATION_MODE_NORMAL" ;
VAL_ 691 VCRIGHT_hvacLHVaneOperationMode 1 "HVACACTUATOR_OPERATION_MODE_CALIBRATION" 0 "HVACACTUATOR_OPERATION_MODE_NORMAL" ;
VAL_ 691 VCRIGHT_hvacRHVaneOperationMode 1 "HVACACTUATOR_OPERATION_MODE_CALIBRATION" 0 "HVACACTUATOR_OPERATION_MODE_NORMAL" ;
VAL_ 691 VCRIGHT_hvacUpperModeOpMode 1 "HVACACTUATOR_OPERATION_MODE_CALIBRATION" 0 "HVACACTUATOR_OPERATION_MODE_NORMAL" ;
VAL_ 691 VCRIGHT_hvacLowerModeOpMode 1 "HVACACTUATOR_OPERATION_MODE_CALIBRATION" 0 "HVACACTUATOR_OPERATION_MODE_NORMAL" ;
VAL_ 691 VCRIGHT_hvacIntakeOperationMode 1 "HVACACTUATOR_OPERATION_MODE_CALIBRATION" 0 "HVACACTUATOR_OPERATION_MODE_NORMAL" ;
VAL_ 691 VCRIGHT_hvacRearOperationMode 1 "HVACACTUATOR_OPERATION_MODE_CALIBRATION" 0 "HVACACTUATOR_OPERATION_MODE_NORMAL" ;
VAL_ 691 VCRIGHT_isProbeFeedbackApplied 4 "NEGATIVEHIGH" 3 "POSITIVEHIGH" 2 "NEGATIVE" 1 "POSITIVE" 0 "OFF" ;
VAL_ 691 VCRIGHT_convectionTargetLeft 511 "SNA" ;
VAL_ 691 VCRIGHT_convectionTargetRight 511 "SNA" ;
VAL_ 691 VCRIGHT_convectionDeliveredLeft 511 "SNA" ;
VAL_ 691 VCRIGHT_convectionDeliveredRight 511 "SNA" ;
VAL_ 691 VCRIGHT_solarLoadRightOccupant 127 "SNA" ;
VAL_ 691 VCRIGHT_solarLoadLeftOccupant 127 "SNA" ;
VAL_ 691 VCRIGHT_solarLoadFromThsTemp 255 "SNA" ;
VAL_ 691 VCRIGHT_cabinTempWshldDefog 255 "SNA" ;
VAL_ 691 VCRIGHT_cabinTempWshldDefogTop 255 "SNA" ;
VAL_ 691 VCRIGHT_cabinTempBreathLevelFHea 255 "SNA" ;
VAL_ 691 VCRIGHT_cabinTempBreathLevelFCoo 255 "SNA" ;
VAL_ 691 VCRIGHT_hvacTorqueMassflowEstima 5 "HVAC_TORQUE_MASSFLOW_ESTIMATE_STATUS_COMPUTED_FILTERED" 4 "HVAC_TORQUE_MASSFLOW_ESTIMATE_STATUS_COMPUTED_UNFILTERED" 3 "HVAC_TORQUE_MASSFLOW_ESTIMATE_STATUS_CFM_NEGATIVE" 2 "HVAC_TORQUE_MASSFLOW_ESTIMATE_STATUS_DISCRIMINANT_NEGATIVE" 1 "HVAC_TORQUE_MASSFLOW_ESTIMATE_STATUS_TORQUE_BELOW_OFFSET" 0 "HVAC_TORQUE_MASSFLOW_ESTIMATE_STATUS_BLOWER_NOT_ACTIVE" ;
VAL_ 691 VCRIGHT_AP_humidityModelBasedCab 1023 "SNA" ;
VAL_ 691 VCRIGHT_solarLoadOnVehFiltered 255 "SNA" ;
VAL_ 691 VCRIGHT_cabinTempProbeEstimate 255 "SNA" ;
VAL_ 691 VCRIGHT_cabinTempThs 255 "SNA" ;
VAL_ 691 VCRIGHT_cabinTempThsBracket 255 "SNA" ;
VAL_ 691 VCRIGHT_CO2ppm 1023 "SNA" ;
VAL_ 691 VCRIGHT_reverseFogLightsCurrent 15 "SNA" ;
VAL_ 691 VCRIGHT_sideMirrorHeaterCurrent 31 "SNA" ;
VAL_ 691 VCRIGHT_trunkInteriorLEDCurrent 15 "SNA" ;
VAL_ 691 VCRIGHT_mapPocketLEDsCurrent 15 "SNA" ;
VAL_ 691 VCRIGHT_miscEFuseCurrent 31 "SNA" ;
VAL_ 691 VCRIGHT_miscInteriorLightsCurren 7 "SNA" ;
VAL_ 691 VCRIGHT_frontPuddleLEDCurrent 7 "SNA" ;
VAL_ 691 VCRIGHT_rearPuddleLEDCurrent 7 "SNA" ;
VAL_ 691 VCRIGHT_liftgateShutfaceLEDCurre 7 "SNA" ;
VAL_ 691 VCRIGHT_3rSeatTOSCurrent 15 "SNA" ;
VAL_ 691 VCRIGHT_vbatFusedCurrent 15 "SNA" ;
VAL_ 691 VCRIGHT_cabinTempGlassGridHeater 255 "SNA" ;
VAL_ 691 VCRIGHT_hvacAirflowReasonRight 21 "NONE" 20 "ODOR_ROUTINE" 19 "DRIVERLESS_SELF_TEST" 18 "VOC_PURGE" 17 "STRATIFICATION_TOP_PAD_AREA" 16 "HOT_DUCT_LOCKOUT" 15 "COLD_DUCT_LOCKOUT" 14 "BIOWEAPON_DEFENSE" 13 "EVAP_OIL_PURGE" 12 "EVAP_DRYING" 11 "SCREEN_PROTECTION" 10 "CABIN_OVERHEAT_PROTECT" 9 "CABIN_PURGE" 8 "OUTLET_TEMP_LIMIT" 7 "OCCUPANT_CONVECTION_REQUIREMENT" 6 "STRATIFICATION_INTERIOR_SURFACES" 5 "STRATIFICATION_GLASS_ROOF" 4 "MINIMUM_AUTO_AIRFLOW" 3 "CABIN_TEMPERATURE_CONTROL" 2 "UI_SHORTCUT" 1 "MANUAL_FAN_SPEED" 0 "HVAC_OFF" ;
VAL_ 691 VCRIGHT_hvacAirflowReasonLeft 21 "NONE" 20 "ODOR_ROUTINE" 19 "DRIVERLESS_SELF_TEST" 18 "VOC_PURGE" 17 "STRATIFICATION_TOP_PAD_AREA" 16 "HOT_DUCT_LOCKOUT" 15 "COLD_DUCT_LOCKOUT" 14 "BIOWEAPON_DEFENSE" 13 "EVAP_OIL_PURGE" 12 "EVAP_DRYING" 11 "SCREEN_PROTECTION" 10 "CABIN_OVERHEAT_PROTECT" 9 "CABIN_PURGE" 8 "OUTLET_TEMP_LIMIT" 7 "OCCUPANT_CONVECTION_REQUIREMENT" 6 "STRATIFICATION_INTERIOR_SURFACES" 5 "STRATIFICATION_GLASS_ROOF" 4 "MINIMUM_AUTO_AIRFLOW" 3 "CABIN_TEMPERATURE_CONTROL" 2 "UI_SHORTCUT" 1 "MANUAL_FAN_SPEED" 0 "HVAC_OFF" ;
VAL_ 691 VCRIGHT_solarLoadLeftOccupantFil 127 "SNA" ;
VAL_ 691 VCRIGHT_solarLoadRightOccupantFi 127 "SNA" ;
VAL_ 691 VCRIGHT_airflowReasonAutoInManua 21 "NONE" 20 "ODOR_ROUTINE" 19 "DRIVERLESS_SELF_TEST" 18 "VOC_PURGE" 17 "STRATIFICATION_TOP_PAD_AREA" 16 "HOT_DUCT_LOCKOUT" 15 "COLD_DUCT_LOCKOUT" 14 "BIOWEAPON_DEFENSE" 13 "EVAP_OIL_PURGE" 12 "EVAP_DRYING" 11 "SCREEN_PROTECTION" 10 "CABIN_OVERHEAT_PROTECT" 9 "CABIN_PURGE" 8 "OUTLET_TEMP_LIMIT" 7 "OCCUPANT_CONVECTION_REQUIREMENT" 6 "STRATIFICATION_INTERIOR_SURFACES" 5 "STRATIFICATION_GLASS_ROOF" 4 "MINIMUM_AUTO_AIRFLOW" 3 "CABIN_TEMPERATURE_CONTROL" 2 "UI_SHORTCUT" 1 "MANUAL_FAN_SPEED" 0 "HVAC_OFF" ;
VAL_ 691 VCRIGHT_airflowReasonAutoIn_0001 21 "NONE" 20 "ODOR_ROUTINE" 19 "DRIVERLESS_SELF_TEST" 18 "VOC_PURGE" 17 "STRATIFICATION_TOP_PAD_AREA" 16 "HOT_DUCT_LOCKOUT" 15 "COLD_DUCT_LOCKOUT" 14 "BIOWEAPON_DEFENSE" 13 "EVAP_OIL_PURGE" 12 "EVAP_DRYING" 11 "SCREEN_PROTECTION" 10 "CABIN_OVERHEAT_PROTECT" 9 "CABIN_PURGE" 8 "OUTLET_TEMP_LIMIT" 7 "OCCUPANT_CONVECTION_REQUIREMENT" 6 "STRATIFICATION_INTERIOR_SURFACES" 5 "STRATIFICATION_GLASS_ROOF" 4 "MINIMUM_AUTO_AIRFLOW" 3 "CABIN_TEMPERATURE_CONTROL" 2 "UI_SHORTCUT" 1 "MANUAL_FAN_SPEED" 0 "HVAC_OFF" ;
VAL_ 691 VCRIGHT_airflowReasonAutoIn_0002 21 "NONE" 20 "ODOR_ROUTINE" 19 "DRIVERLESS_SELF_TEST" 18 "VOC_PURGE" 17 "STRATIFICATION_TOP_PAD_AREA" 16 "HOT_DUCT_LOCKOUT" 15 "COLD_DUCT_LOCKOUT" 14 "BIOWEAPON_DEFENSE" 13 "EVAP_OIL_PURGE" 12 "EVAP_DRYING" 11 "SCREEN_PROTECTION" 10 "CABIN_OVERHEAT_PROTECT" 9 "CABIN_PURGE" 8 "OUTLET_TEMP_LIMIT" 7 "OCCUPANT_CONVECTION_REQUIREMENT" 6 "STRATIFICATION_INTERIOR_SURFACES" 5 "STRATIFICATION_GLASS_ROOF" 4 "MINIMUM_AUTO_AIRFLOW" 3 "CABIN_TEMPERATURE_CONTROL" 2 "UI_SHORTCUT" 1 "MANUAL_FAN_SPEED" 0 "HVAC_OFF" ;
VAL_ 691 VCRIGHT_vocSweatMassSeat 255 "SNA" ;
VAL_ 691 VCRIGHT_vocSweatConcentrationAir 255 "SNA" ;
VAL_ 691 VCRIGHT_steeringWheelSurfaceTemp 1023 "SNA" ;
VAL_ 691 VCRIGHT_steeringWheelSurfac_0001 1023 "SNA" ;
VAL_ 691 VCRIGHT_timeToComfortHeating 63 "HVAC_OFF" 62 "UNATTAINABLE" 0 "IN_COMFORT_BAND" ;
VAL_ 691 VCRIGHT_timeToComfortCooling 63 "HVAC_OFF" 62 "UNATTAINABLE" 0 "IN_COMFORT_BAND" ;
VAL_ 691 VCRIGHT_cabinWaterMassRaw 255 "SNA" ;
VAL_ 691 VCRIGHT_VOCPurgeState 5 "PURGING_AND_DRYING" 4 "WAITING" 3 "PURGING" 2 "IDLE" 1 "INACTIVE" 0 "INIT" ;
VAL_ 691 VCRIGHT_cameraFoggingMonitorStat 6 "PRE_RUN_PURGE" 5 "IDLE" 4 "INACTIVE" 3 "RUNNING" 2 "WAKEUP" 1 "MONITORING" 0 "INIT" ;
VAL_ 691 VCRIGHT_windWeatherSource 2 "FALLBACK" 1 "FORECAST" 0 "CURRENT" ;
VAL_ 691 VCRIGHT_humidityRatioWeatherSour 2 "FALLBACK" 1 "FORECAST" 0 "CURRENT" ;
VAL_ 691 VCRIGHT_hvacIntakeReason 26 "INTAKE_REASON_ODOR_ROUTINE" 25 "INTAKE_REASON_HVAC_OFF_IN_MOTION" 24 "INTAKE_REASON_LIFTGATE_CLOSING" 23 "INTAKE_REASON_DRIVERLESS_SELF_TEST" 22 "INTAKE_REASON_VOC_PURGE" 21 "INTAKE_REASON_STEAMING" 20 "INTAKE_REASON_PULLDOWN_IN_FRESH" 19 "INTAKE_REASON_RECIRC_NVH" 18 "INTAKE_REASON_CO2_PURGE" 17 "INTAKE_REASON_HVAC_OFF" 16 "INTAKE_REASON_PARK_POSITION" 15 "INTAKE_REASON_EVAP_DRYING" 14 "INTAKE_REASON_OIL_PURGE" 13 "INTAKE_REASON_CABIN_PURGE" 12 "INTAKE_REASON_COP" 11 "INTAKE_REASON_ENHANCED_FILTERATION" 10 "INTAKE_REASON_CHARGE_PORT_THAW" 9 "INTAKE_REASON_PRECON_OVERRIDE" 8 "INTAKE_REASON_HUMIDITY" 7 "INTAKE_REASON_BIO_WEAPON_STEADY" 6 "INTAKE_REASON_BIO_WEAPON_INIT" 5 "INTAKE_REASON_TEMPERATURE_CONTROL" 4 "INTAKE_REASON_MANUAL_RECIRC" 3 "INTAKE_REASON_MANUAL_FRESH" 2 "INTAKE_REASON_CAR_WASH" 1 "INTAKE_REASON_UDS" 0 "INTAKE_REASON_NONE" ;
VAL_ 691 VCRIGHT_solarAzimuthCarRef -1023 "SNA" ;
VAL_ 691 VCRIGHT_hvacLimpModeStatus 4 "LIMP_MODE_FAULTED" 3 "LIMP_MODE_ACTIVE" 2 "LIMP_MODE_READY" 1 "LIMP_MODE_WAITING_FOR_SENSORS" 0 "LIMP_MODE_NOT_NEEDED" ;
VAL_ 691 VCRIGHT_hvacEstimatedCameraWinds 255 "SNA" ;
VAL_ 691 VCRIGHT_cabinTempRoofL2 255 "SNA" ;
VAL_ 691 VCRIGHT_cabinTempRoofL3 255 "SNA" ;
VAL_ 691 VCRIGHT_odorRoutineState 7 "SNA" 6 "BLOCKED_NO_TRIP_END" 5 "BLOCKED_NO_HVAC_PERMISSION" 4 "BLOCKED_NO_RIDESTATE" 3 "AUTO_ACTIVE" 2 "WAITING_FOR_ACTIVATION" 1 "IDLE" 0 "INACTIVE" ;
VAL_ 691 VCRIGHT_cameraDefogState 3 "FAULT" 2 "ACTIVE" 1 "IDLE" 0 "INACTIVE" ;
VAL_ 1859 VCRIGHT_systemRecallStatus 3 "RECALL_INTERRUPTED" 2 "RECALL_COMPLETE" 1 "RECALL_IN_PROGRESS" 0 "RECALL_SNA" ;
VAL_ 1859 VCRIGHT_seatRecallStatus 3 "RECALL_INTERRUPTED" 2 "RECALL_COMPLETE" 1 "RECALL_IN_PROGRESS" 0 "RECALL_SNA" ;
VAL_ 1859 VCRIGHT_mirrorRecallStatus 3 "RECALL_INTERRUPTED" 2 "RECALL_COMPLETE" 1 "RECALL_IN_PROGRESS" 0 "RECALL_SNA" ;
VAL_ 794 VCRIGHT_frontOccupancyStatus 7 "SEAT_OCCUPANCY_SNA" 3 "SEAT_NOT_CONFIGURED" 2 "SEAT_OCCUPANCY_FAULTED" 1 "SEAT_OCCUPIED" 0 "SEAT_UNOCCUPIED" ;
VAL_ 794 VCRIGHT_frontBuckleStatus 3 "SEAT_BELT_BUCKLE_NOT_CONFIGURED" 2 "SEAT_BELT_BUCKLE_STATUS_FAULTED" 1 "SEAT_BELT_BUCKLE_STATUS_LATCHED" 0 "SEAT_BELT_BUCKLE_STATUS_UNLATCHED" ;
VAL_ 794 VCRIGHT_rearCenterBuckleStatus 3 "SEAT_BELT_BUCKLE_NOT_CONFIGURED" 2 "SEAT_BELT_BUCKLE_STATUS_FAULTED" 1 "SEAT_BELT_BUCKLE_STATUS_LATCHED" 0 "SEAT_BELT_BUCKLE_STATUS_UNLATCHED" ;
VAL_ 794 VCRIGHT_rearRightBuckleStatus 3 "SEAT_BELT_BUCKLE_NOT_CONFIGURED" 2 "SEAT_BELT_BUCKLE_STATUS_FAULTED" 1 "SEAT_BELT_BUCKLE_STATUS_LATCHED" 0 "SEAT_BELT_BUCKLE_STATUS_UNLATCHED" ;
VAL_ 794 VCRIGHT_rearRightOccupancyStatus 3 "SEAT_NOT_CONFIGURED" 2 "SEAT_OCCUPANCY_FAULTED" 1 "SEAT_OCCUPIED" 0 "SEAT_UNOCCUPIED" ;
VAL_ 794 VCRIGHT_3RowLeftBuckleStatus 3 "SEAT_BELT_BUCKLE_NOT_CONFIGURED" 2 "SEAT_BELT_BUCKLE_STATUS_FAULTED" 1 "SEAT_BELT_BUCKLE_STATUS_LATCHED" 0 "SEAT_BELT_BUCKLE_STATUS_UNLATCHED" ;
VAL_ 794 VCRIGHT_3RowRightBuckleStatus 3 "SEAT_BELT_BUCKLE_NOT_CONFIGURED" 2 "SEAT_BELT_BUCKLE_STATUS_FAULTED" 1 "SEAT_BELT_BUCKLE_STATUS_LATCHED" 0 "SEAT_BELT_BUCKLE_STATUS_UNLATCHED" ;
VAL_ 794 VCRIGHT_3RowLeftOccupancyStatus 3 "SEAT_NOT_CONFIGURED" 2 "SEAT_OCCUPANCY_FAULTED" 1 "SEAT_OCCUPIED" 0 "SEAT_UNOCCUPIED" ;
VAL_ 794 VCRIGHT_3RowRightOccupancyStatus 3 "SEAT_NOT_CONFIGURED" 2 "SEAT_OCCUPANCY_FAULTED" 1 "SEAT_OCCUPIED" 0 "SEAT_UNOCCUPIED" ;
VAL_ 794 VCRIGHT_seatTrackPosition 7 "SEAT_TRACK_POSITION_SNA" 3 "SEAT_TRACK_POSITION_FAULTED" 2 "SEAT_TRACK_POSITION_NOT_CONFIGURED" 1 "SEAT_TRACK_POSITION_REARWARD" 0 "SEAT_TRACK_POSITION_FORWARD" ;
VAL_ 794 VCRIGHT_occupantClassification 7 "SEAT_OCCUPANT_CLASSIFICATON_SNA" 6 "SEAT_OCCUPANT_CLASSIFICATON_OUT_OF_POSITION" 5 "SEAT_OCCUPANT_CLASSIFICATON_NOT_CONFIGURED" 4 "SEAT_OCCUPANT_CLASSIFICATON_INIT" 3 "SEAT_OCCUPANT_CLASSIFICATON_LARGE" 2 "SEAT_OCCUPANT_CLASSIFICATON_SMALL" 1 "SEAT_OCCUPANT_CLASSIFICATON_INHIBIT" 0 "SEAT_OCCUPANT_CLASSIFICATON_EMPTY" ;
VAL_ 794 VCRIGHT_occupantClassificationQF 1 "SEAT_OCCUPANT_CLASSIFICATON_NOT_FAULTED" 0 "SEAT_OCCUPANT_CLASSIFICATON_FAULTED" ;
VAL_ 794 VCRIGHT_classificationEnabled 1 "VCRIGHT_CLASSIFICATION_SOURCE" 0 "OCS1P_CLASSIFICATION_SOURCE" ;
VAL_ 794 VCRIGHT_classificationEnabledQF 1 "CLASSIFICATION_ENABLED_NOT_FAULTED" 0 "CLASSIFICATION_ENABLED_FAULTED" ;
VAL_ 794 VCRIGHT_3RowRightABStatus 2 "AIRBAG_STATE_SNA" 1 "AIRBAG_SUPPRESS" 0 "AIRBAG_ALLOW" ;
VAL_ 1251 VCRIGHT_seatStatusIndex 7 "RELATIVE_POSITION" 6 "OFFSETS" 5 "POSITION" 4 "LUMBAR" 3 "TILT" 2 "LIFT" 1 "BACK" 0 "TRACK" ;
VAL_ 1251 VC_AH_1RowRightSeatMovementHealt 4 "SEAT_CALIBRATION_REQUIRED" 3 "SEAT_IN_NON_USE_POSITION" 2 "SEAT_CANNOT_MOVE" 1 "SEAT_MOVEMENT_HEALTHY" 0 "SEAT_MOVEMENT_HEALTH_UNKNOWN" ;
VAL_ 1251 VCRIGHT_frontSeatTrackState 5 "SEAT_STATE_UNDEFINED" 4 "SEAT_STATE_CALIBRATING" 3 "SEAT_STATE_RECALLING" 2 "SEAT_STATE_MOVING_DOWN" 1 "SEAT_STATE_MOVING_UP" 0 "SEAT_STATE_STOPPED" ;
VAL_ 1251 VCRIGHT_frontSeatTrackBridgeSt 3 "IO_BRIDGE_STATE_COAST" 2 "IO_BRIDGE_STATE_BRAKE" 1 "IO_BRIDGE_STATE_ENABLED" 0 "IO_BRIDGE_STATE_DISABLED" ;
VAL_ 1251 VCRIGHT_frontSeatBackState 5 "SEAT_STATE_UNDEFINED" 4 "SEAT_STATE_CALIBRATING" 3 "SEAT_STATE_RECALLING" 2 "SEAT_STATE_MOVING_DOWN" 1 "SEAT_STATE_MOVING_UP" 0 "SEAT_STATE_STOPPED" ;
VAL_ 1251 VCRIGHT_frontSeatBackBridgeSt 3 "IO_BRIDGE_STATE_COAST" 2 "IO_BRIDGE_STATE_BRAKE" 1 "IO_BRIDGE_STATE_ENABLED" 0 "IO_BRIDGE_STATE_DISABLED" ;
VAL_ 1251 VCRIGHT_frontSeatLiftState 5 "SEAT_STATE_UNDEFINED" 4 "SEAT_STATE_CALIBRATING" 3 "SEAT_STATE_RECALLING" 2 "SEAT_STATE_MOVING_DOWN" 1 "SEAT_STATE_MOVING_UP" 0 "SEAT_STATE_STOPPED" ;
VAL_ 1251 VCRIGHT_frontSeatLiftBridgeSt 3 "IO_BRIDGE_STATE_COAST" 2 "IO_BRIDGE_STATE_BRAKE" 1 "IO_BRIDGE_STATE_ENABLED" 0 "IO_BRIDGE_STATE_DISABLED" ;
VAL_ 1251 VCRIGHT_frontSeatTiltState 5 "SEAT_STATE_UNDEFINED" 4 "SEAT_STATE_CALIBRATING" 3 "SEAT_STATE_RECALLING" 2 "SEAT_STATE_MOVING_DOWN" 1 "SEAT_STATE_MOVING_UP" 0 "SEAT_STATE_STOPPED" ;
VAL_ 1251 VCRIGHT_frontSeatTiltBridgeSt 3 "IO_BRIDGE_STATE_COAST" 2 "IO_BRIDGE_STATE_BRAKE" 1 "IO_BRIDGE_STATE_ENABLED" 0 "IO_BRIDGE_STATE_DISABLED" ;
VAL_ 1251 VCRIGHT_lumbarAState 5 "SEAT_STATE_UNDEFINED" 4 "SEAT_STATE_CALIBRATING" 3 "SEAT_STATE_RECALLING" 2 "SEAT_STATE_MOVING_DOWN" 1 "SEAT_STATE_MOVING_UP" 0 "SEAT_STATE_STOPPED" ;
VAL_ 1251 VCRIGHT_lumbarBState 5 "SEAT_STATE_UNDEFINED" 4 "SEAT_STATE_CALIBRATING" 3 "SEAT_STATE_RECALLING" 2 "SEAT_STATE_MOVING_DOWN" 1 "SEAT_STATE_MOVING_UP" 0 "SEAT_STATE_STOPPED" ;
VAL_ 739 VCRIGHT_seatStatus2Index 15 "SEAT_HEAT_3R_RIGHT" 14 "SEAT_3ROW_ADJUSTABLE_FOLD_FLAT" 13 "FRONT_SEAT_THIGH_SUPPORT" 12 "SEAT_2ROW_ADJUSTABLE_FOLD_FLAT_2" 11 "SEAT_2ROW_ADJUSTABLE_FOLD_FLAT" 10 "OCS_IEE" 9 "SEAT_2ROW_EASY_ENTRY" 8 "SEAT_SWITCH_VOLTAGES_2" 7 "SEAT_SWITCH_VOLTAGES_1" 6 "SEAT_2ROW_ACTUATOR" 5 "SEAT_HEAT_REARR_BACKREST" 4 "OCCUPANCY" 3 "SEAT_HEAT_REARR" 2 "SEAT_HEAT_REARC" 1 "SEAT_HEAT_REARL_CUSHION" 0 "SEAT_HEAT_FRONT" ;
VAL_ 739 VCRIGHT_frontSeatHeatCurrent 12 "SNA" ;
VAL_ 739 VC_AH_1RowRightSeatHeatVentHealt 2 "SEAT_HEAT_VENT_UNAVAILABLE" 1 "SEAT_HEAT_VENT_HEALTHY" 0 "SEAT_HEAT_VENT_HEALTH_UNKNOWN" ;
VAL_ 739 VCRIGHT_2RowSeatReclineState 15 "SEAT_ADJUSTABLE_FOLD_FLAT_STATE_SNA" 12 "SEAT_ADJUSTABLE_FOLD_FLAT_STATE_CALIBRATING_ABSOLUTE_SENSOR" 11 "SEAT_ADJUSTABLE_FOLD_FLAT_STATE_CALIBRATING_ZERO_POSITION" 10 "SEAT_ADJUSTABLE_FOLD_FLAT_STATE_WAITING_TO_CLEAR_FOR_UNFOLD" 9 "SEAT_ADJUSTABLE_FOLD_FLAT_STATE_WAITING_TO_CLEAR_FOR_FOLD" 8 "SEAT_ADJUSTABLE_FOLD_FLAT_STATE_MOVING_REARWARD_TO_POSITION" 7 "SEAT_ADJUSTABLE_FOLD_FLAT_STATE_MOVING_FORWARD_TO_POSITION" 6 "SEAT_ADJUSTABLE_FOLD_FLAT_STATE_UNFOLDING" 5 "SEAT_ADJUSTABLE_FOLD_FLAT_STATE_FOLDING" 4 "SEAT_ADJUSTABLE_FOLD_FLAT_STATE_ADJUSTING_REARWARD_FAST" 3 "SEAT_ADJUSTABLE_FOLD_FLAT_STATE_ADJUSTING_FORWARD_FAST" 2 "SEAT_ADJUSTABLE_FOLD_FLAT_STATE_ADJUSTING_REARWARD_COMFORT" 1 "SEAT_ADJUSTABLE_FOLD_FLAT_STATE_ADJUSTING_FORWARD_COMFORT" 0 "SEAT_ADJUSTABLE_FOLD_FLAT_STATE_STOPPED" ;
VAL_ 739 VCRIGHT_2RowSeatReclineAbsPosSwi 3 "SWITCH_FAULT" 2 "SWITCH_ON" 1 "SWITCH_OFF" 0 "SWITCH_SNA" ;
VAL_ 739 VCRIGHT_2RowSeatReclinePositionS 4 "SEAT_ADJUSTABLE_FOLD_FLAT_POSITION_STATE_SNA" 3 "SEAT_ADJUSTABLE_FOLD_FLAT_POSITION_STATE_UNKNOWN" 2 "SEAT_ADJUSTABLE_FOLD_FLAT_POSITION_STATE_UNSAFE_INTERMEDIATE" 1 "SEAT_ADJUSTABLE_FOLD_FLAT_POSITION_STATE_UNFOLDED" 0 "SEAT_ADJUSTABLE_FOLD_FLAT_POSITION_STATE_FOLDED" ;
VAL_ 739 VCRIGHT_2RowSeatReclineNextToggl 2 "SEAT_ADJUSTABLE_FOLD_FLAT_NEXT_TOGGLE_DIRECTION_SNA" 1 "SEAT_ADJUSTABLE_FOLD_FLAT_NEXT_TOGGLE_DIRECTION_UNFOLD" 0 "SEAT_ADJUSTABLE_FOLD_FLAT_NEXT_TOGGLE_DIRECTION_FOLD" ;
VAL_ 739 VCRIGHT_2RowSeat1RClashAvoidance 6 "SEAT_FOLD_FLAT_CLASH_AVOIDANCE_REASON_FRONT_SEAT_OCCUPANCY" 5 "SEAT_FOLD_FLAT_CLASH_AVOIDANCE_REASON_FRONT_SEAT_MOVING" 4 "SEAT_FOLD_FLAT_CLASH_AVOIDANCE_REASON_FRONT_SEAT_PROFILE_RECALL" 3 "SEAT_FOLD_FLAT_CLASH_AVOIDANCE_REASON_REAR_SEAT_UNCALIBRATED" 2 "SEAT_FOLD_FLAT_CLASH_AVOIDANCE_REASON_FRONT_SEAT_UNCALIBRATED" 1 "SEAT_FOLD_FLAT_CLASH_AVOIDANCE_REASON_VEHICLE_IN_MOTION" 0 "SEAT_FOLD_FLAT_CLASH_AVOIDANCE_REASON_NONE" ;
VAL_ 739 VCRIGHT_2RowSeat1RClashAvoi_0001 3 "SEAT_FOLD_FLAT_CLASH_AVOIDANCE_STATE_RESTORING_FRONT_SEAT" 2 "SEAT_FOLD_FLAT_CLASH_AVOIDANCE_STATE_WAITING_TO_RESTORE_FRONT_SEAT" 1 "SEAT_FOLD_FLAT_CLASH_AVOIDANCE_STATE_FRONT_SEAT_CLEARING" 0 "SEAT_FOLD_FLAT_CLASH_AVOIDANCE_STATE_IDLE" ;
VAL_ 739 VC_AH_2RowRightSeatMovementHealt 4 "SEAT_CALIBRATION_REQUIRED" 3 "SEAT_IN_NON_USE_POSITION" 2 "SEAT_CANNOT_MOVE" 1 "SEAT_MOVEMENT_HEALTHY" 0 "SEAT_MOVEMENT_HEALTH_UNKNOWN" ;
VAL_ 739 VCRIGHT_3RowSeatReclineState 15 "SEAT_ADJUSTABLE_FOLD_FLAT_STATE_SNA" 12 "SEAT_ADJUSTABLE_FOLD_FLAT_STATE_CALIBRATING_ABSOLUTE_SENSOR" 11 "SEAT_ADJUSTABLE_FOLD_FLAT_STATE_CALIBRATING_ZERO_POSITION" 10 "SEAT_ADJUSTABLE_FOLD_FLAT_STATE_WAITING_TO_CLEAR_FOR_UNFOLD" 9 "SEAT_ADJUSTABLE_FOLD_FLAT_STATE_WAITING_TO_CLEAR_FOR_FOLD" 8 "SEAT_ADJUSTABLE_FOLD_FLAT_STATE_MOVING_REARWARD_TO_POSITION" 7 "SEAT_ADJUSTABLE_FOLD_FLAT_STATE_MOVING_FORWARD_TO_POSITION" 6 "SEAT_ADJUSTABLE_FOLD_FLAT_STATE_UNFOLDING" 5 "SEAT_ADJUSTABLE_FOLD_FLAT_STATE_FOLDING" 4 "SEAT_ADJUSTABLE_FOLD_FLAT_STATE_ADJUSTING_REARWARD_FAST" 3 "SEAT_ADJUSTABLE_FOLD_FLAT_STATE_ADJUSTING_FORWARD_FAST" 2 "SEAT_ADJUSTABLE_FOLD_FLAT_STATE_ADJUSTING_REARWARD_COMFORT" 1 "SEAT_ADJUSTABLE_FOLD_FLAT_STATE_ADJUSTING_FORWARD_COMFORT" 0 "SEAT_ADJUSTABLE_FOLD_FLAT_STATE_STOPPED" ;
VAL_ 739 VCRIGHT_3RowSeatReclineNextToggl 2 "SEAT_ADJUSTABLE_FOLD_FLAT_NEXT_TOGGLE_DIRECTION_SNA" 1 "SEAT_ADJUSTABLE_FOLD_FLAT_NEXT_TOGGLE_DIRECTION_UNFOLD" 0 "SEAT_ADJUSTABLE_FOLD_FLAT_NEXT_TOGGLE_DIRECTION_FOLD" ;
VAL_ 739 VCRIGHT_3RowSeatReclinePositionS 4 "SEAT_ADJUSTABLE_FOLD_FLAT_POSITION_STATE_SNA" 3 "SEAT_ADJUSTABLE_FOLD_FLAT_POSITION_STATE_UNKNOWN" 2 "SEAT_ADJUSTABLE_FOLD_FLAT_POSITION_STATE_UNSAFE_INTERMEDIATE" 1 "SEAT_ADJUSTABLE_FOLD_FLAT_POSITION_STATE_UNFOLDED" 0 "SEAT_ADJUSTABLE_FOLD_FLAT_POSITION_STATE_FOLDED" ;
VAL_ 739 VCRIGHT_3RowSeatReclineAbsPosSwi 3 "SWITCH_FAULT" 2 "SWITCH_ON" 1 "SWITCH_OFF" 0 "SWITCH_SNA" ;
VAL_ 835 VCRIGHT_autonomyBehaviorStatus 2 "DRIVERLESS_NO_TAKEOVER" 1 "DRIVERLESS_TAKEOVER" 0 "DRIVER" ;
VAL_ 835 VCRIGHT_LVBatteryTypeDBG 5 "LV_BATTERY_TYPE_TESLA_48V_LI_ION" 4 "LV_BATTERY_TYPE_TESLA_16V_LI_ION" 3 "LV_BATTERY_TYPE_CATL_LI_ION" 2 "LV_BATTERY_TYPE_CLARIOS_B24_FLOODED" 1 "LV_BATTERY_TYPE_ATLASBX_B24_FLOODED" 0 "LV_BATTERY_TYPE_UNKNOWN" ;
VAL_ 835 VCRIGHT_rearDefrostState 4 "HEATER_STATE_FAULT" 3 "HEATER_STATE_OFF_UNAVAILABLE" 2 "HEATER_STATE_OFF" 1 "HEATER_STATE_ON" 0 "HEATER_STATE_SNA" ;
VAL_ 835 VCRIGHT_mirrorHeatState 4 "HEATER_STATE_FAULT" 3 "HEATER_STATE_OFF_UNAVAILABLE" 2 "HEATER_STATE_OFF" 1 "HEATER_STATE_ON" 0 "HEATER_STATE_SNA" ;
VAL_ 835 VCRIGHT_steeringWheelHeaterDCTgt 127 "SNA" ;
